VERSION "created by canmatrix"

NS_ :

BS_:

BU_: MD1_ECM ETC NODE_5 BSM_EBS RM_IRCS IC_Multic SGW BCM_NBM VCM NODE_31 ETS NODE_45 FCCU DICO NODE_72 FMReceiver SGW2 VCU ADCU MRGEN DTCO MBMS TPMS AI_CAID ELC ELC_R NODE_F7 BMS3 TUROLLA PCM SRR_Front_Left SRR_Rear_Right SRR_Front_Right SRR_Front SRR_Rear_Left ELFA3_S THERMOKING_M TMU_HP_Rr NODE_B1 NODE_B2 NODE_B3 NODE_B4 NODE_B5 NODE_B6 NODE_B7 NODE_B8 BMS2 NODE_B9 NODE_BA NODE_FC NODE_BB NODE_BC NODE_BE NODE_BD NODE_BF ACU NODE_C0 BMS1 NODE_C1 FCU NODE_C3 NODE_C4 NODE_EC NODE_C5 NODE_C6 NODE_C7 NODE_C8 VCU2 NODE_CA NODE_CB NODE_CD NODE_CE NODE_CF NODE_ED ST_ScanTool MASTER68_STD1 NODE_D1 NODE_F2 NODE_FD NODE_D2 MCSL NODE_EB NODE_D3 NODE_D4 NODE_D5 NODE_D6 VCCU NODE_D8 NODE_D9 NODE_F9 DiagTool NODE_DA NODE_DB NODE_DC NODE_DD NODE_DE NODE_DF NODE_E0 NODE_E1 NODE_E2 NODE_E9 NODE_E3 SAS NODE_FB NODE_F8 NODE_E6 ELFA3 NODE_F THERMOKING_D FMS MULTIC_S MULTIC_2 BMS4 BMS5 BMS6 BMS7 BMS8 BMS9 BMS10 BMS11 NODE_71

BO_ 2566725632 A1DOC1: 8 MD1_ECM
 SG_ At1DocInTemp : 0|16@1+ (0.03125,-273) [-273|1734.96875] "°C"  PCM

BO_ 2565874432 A1SCRDSI1: 8 MD1_ECM
 SG_ At1DefActDosQty : 0|16@1+ (0.3,0) [0|19276.5] "g/h"  PCM

BO_ 2499624448 A1SCREGT1: 8 MD1_ECM
 SG_ At1ScrOutTemp : 24|16@1+ (0.03125,-273) [-273|1734.96875] "°C"  PCM
 SG_ At1ScrInTemp : 0|16@1+ (0.03125,-273) [-273|1734.96875] "°C"  PCM

BO_ 2566811431 ACC1_27: 8 VCM
 SG_ AccSetDistMode : 27|3@1+ (1,0) [0|7] ""  PCM
 SG_ AccMode : 24|3@1+ (1,0) [0|7] ""  PCM

BO_ 2566803735 ACC2_17: 8 IC_Multic
 SG_ AccUseDem : 0|2@1+ (1,0) [0|3] ""  PCM

BO_ 2565406464 ACKM_00: 8 MD1_ECM
 SG_ Pgn_Busy m3 : 40|24@1+ (1,0) [0|16777215] "binary"  PCM
 SG_ Pgn_Ad m2 : 40|24@1+ (1,0) [0|16777215] "binary"  PCM
 SG_ Pgn_Nack m1 : 40|24@1+ (1,0) [0|16777215] "binary"  PCM
 SG_ Pgn_Ack m0 : 40|24@1+ (1,0) [0|16777215] "binary"  PCM
 SG_ CtrlByte_Ackm M : 0|8@1+ (1,0) [0|255] "binary"  PCM

BO_ 2565406467 ACKM_03: 8 ETC
 SG_ Pgn_Busy_E8FF03 m3 : 40|24@1+ (1,0) [0|16777215] "binary"  PCM
 SG_ Pgn_Ad_E8FF03 m2 : 40|24@1+ (1,0) [0|16777215] "binary"  PCM
 SG_ Pgn_Nack_E8FF03 m1 : 40|24@1+ (1,0) [0|16777215] "binary"  PCM
 SG_ Pgn_Ack_E8FF03 m0 : 40|24@1+ (1,0) [0|16777215] "binary"  PCM
 SG_ CtrlByte_Ackm_E8FF03 M : 0|8@1+ (1,0) [0|255] "binary"  PCM

BO_ 2565406475 ACKM_0B: 8 BSM_EBS
 SG_ Pgn_Busy_E8FF0B m3 : 40|24@1+ (1,0) [0|16777215] "binary"  PCM
 SG_ Pgn_Ad_E8FF0B m2 : 40|24@1+ (1,0) [0|16777215] "binary"  PCM
 SG_ Pgn_Nack_E8FF0B m1 : 40|24@1+ (1,0) [0|16777215] "binary"  PCM
 SG_ Pgn_Ack_E8FF0B m0 : 40|24@1+ (1,0) [0|16777215] "binary"  PCM
 SG_ CtrlByte_Ackm_E8FF0B M : 0|8@1+ (1,0) [0|255] "binary"  PCM

BO_ 2565406487 ACKM_17: 8 IC_Multic
 SG_ Pgn_Busy_E8FF17 m3 : 40|24@1+ (1,0) [0|16777215] "binary"  PCM
 SG_ Pgn_Ad_E8FF17 m2 : 40|24@1+ (1,0) [0|16777215] "binary"  PCM
 SG_ Pgn_Nack_E8FF17 m1 : 40|24@1+ (1,0) [0|16777215] "binary"  PCM
 SG_ Pgn_Ack_E8FF17 m0 : 40|24@1+ (1,0) [0|16777215] "binary"  PCM
 SG_ CtrlByte_Ackm_E8FF17 M : 0|8@1+ (1,0) [0|255] "binary"  PCM

BO_ 2565406492 ACKM_1C: 8 PCM
 SG_ Pgn_Busy_E8FF1C m3 : 40|24@1+ (1,0) [0|16777215] "binary" Vector__XXX
 SG_ Pgn_Ad_E8FF1C m2 : 40|24@1+ (1,0) [0|16777215] "binary" Vector__XXX
 SG_ Pgn_Nack_E8FF1C m1 : 40|24@1+ (1,0) [0|16777215] "binary" Vector__XXX
 SG_ Pgn_Ack_E8FF1C m0 : 40|24@1+ (1,0) [0|16777215] "binary" Vector__XXX
 SG_ AddrBusy m3 : 32|8@1+ (1,0) [0|255] "" Vector__XXX
 SG_ AddrAccessDenied m2 : 32|8@1+ (1,0) [0|255] "" Vector__XXX
 SG_ AddrNack m1 : 32|8@1+ (1,0) [0|255] "" Vector__XXX
 SG_ AddrAckd m0 : 32|8@1+ (1,0) [0|255] "" Vector__XXX
 SG_ CtrlByte_Ackm_E8FF1C M : 0|8@1+ (1,0) [0|255] "binary" Vector__XXX

BO_ 2565406493 ACKM_1D: 8 SGW
 SG_ Pgn_Busy_E8FF1D m3 : 40|24@1+ (1,0) [0|16777215] "binary"  PCM
 SG_ Pgn_Ad_E8FF1D m2 : 40|24@1+ (1,0) [0|16777215] "binary"  PCM
 SG_ Pgn_Nack_E8FF1D m1 : 40|24@1+ (1,0) [0|16777215] "binary"  PCM
 SG_ Pgn_Ack_E8FF1D m0 : 40|24@1+ (1,0) [0|16777215] "binary"  PCM
 SG_ AddrBusy_E8FF1D m3 : 32|8@1+ (1,0) [0|255] ""  PCM
 SG_ AddrAccessDenied_E8FF1D m2 : 32|8@1+ (1,0) [0|255] ""  PCM
 SG_ AddrNack_E8FF1D m1 : 32|8@1+ (1,0) [0|255] ""  PCM
 SG_ AddrAckd_E8FF1D m0 : 32|8@1+ (1,0) [0|255] ""  PCM
 SG_ CtrlByte_Ackm_E8FF1D M : 0|8@1+ (1,0) [0|255] "binary"  PCM

BO_ 2565406503 ACKM_27: 8 VCM
 SG_ Pgn_Busy_E8FF27 m3 : 40|24@1+ (1,0) [0|16777215] "binary"  PCM
 SG_ Pgn_Ad_E8FF27 m2 : 40|24@1+ (1,0) [0|16777215] "binary"  PCM
 SG_ Pgn_Nack_E8FF27 m1 : 40|24@1+ (1,0) [0|16777215] "binary"  PCM
 SG_ Pgn_Ack_E8FF27 m0 : 40|24@1+ (1,0) [0|16777215] "binary"  PCM
 SG_ CtrlByte_Ackm_E8FF27 M : 0|8@1+ (1,0) [0|255] "binary"  PCM

BO_ 2565406515 ACKM_33: 8 TPMS
 SG_ Pgn_Busy_E8FF33 m3 : 40|24@1+ (1,0) [0|16777215] "binary"  PCM
 SG_ Pgn_Ad_E8FF33 m2 : 40|24@1+ (1,0) [0|16777215] "binary"  PCM
 SG_ Pgn_Nack_E8FF33 m1 : 40|24@1+ (1,0) [0|16777215] "binary"  PCM
 SG_ Pgn_Ack_E8FF33 m0 : 40|24@1+ (1,0) [0|16777215] "binary"  PCM
 SG_ CtrlByte_Ackm_E8FF33 M : 0|8@1+ (1,0) [0|255] "binary"  PCM

BO_ 2565406520 ACKM_38: 8 ETS
 SG_ Pgn_Busy_E8FF38 m3 : 40|24@1+ (1,0) [0|16777215] "binary"  PCM
 SG_ Pgn_Ad_E8FF38 m2 : 40|24@1+ (1,0) [0|16777215] "binary"  PCM
 SG_ Pgn_Nack_E8FF38 m1 : 40|24@1+ (1,0) [0|16777215] "binary"  PCM
 SG_ Pgn_Ack_E8FF38 m0 : 40|24@1+ (1,0) [0|16777215] "binary"  PCM
 SG_ CtrlByte_Ackm_E8FF38 M : 0|8@1+ (1,0) [0|255] "binary"  PCM

BO_ 2565406590 ACKM_7E: 8 SGW2
 SG_ Pgn_Busy_E8FF7E m3 : 40|24@1+ (1,0) [0|16777215] "binary"  PCM
 SG_ Pgn_Ad_E8FF7E m2 : 40|24@1+ (1,0) [0|16777215] "binary"  PCM
 SG_ Pgn_Nack_E8FF7E m1 : 40|24@1+ (1,0) [0|16777215] "binary"  PCM
 SG_ Pgn_Ack_E8FF7E m0 : 40|24@1+ (1,0) [0|16777215] "binary"  PCM
 SG_ CtrlByte_Ackm_E8FF7E M : 0|8@1+ (1,0) [0|255] "binary"  PCM

BO_ 2565406622 ACKM_9E: 8 ADCU
 SG_ Pgn_Busy_E8FF9E m3 : 40|24@1+ (1,0) [0|16777215] "binary"  PCM
 SG_ Pgn_Ad_E8FF9E m2 : 40|24@1+ (1,0) [0|16777215] "binary"  PCM
 SG_ Pgn_Nack_E8FF9E m1 : 40|24@1+ (1,0) [0|16777215] "binary"  PCM
 SG_ Pgn_Ack_E8FF9E m0 : 40|24@1+ (1,0) [0|16777215] "binary"  PCM
 SG_ CtrlByte_Ackm_E8FF9E M : 0|8@1+ (1,0) [0|255] "binary"  PCM

BO_ 2565406624 ACKM_A0: 8 MRGEN
 SG_ Pgn_Busy_E8FFA0 m3 : 40|24@1+ (1,0) [0|16777215] "binary"  PCM
 SG_ Pgn_Ad_E8FFA0 m2 : 40|24@1+ (1,0) [0|16777215] "binary"  PCM
 SG_ Pgn_Nack_E8FFA0 m1 : 40|24@1+ (1,0) [0|16777215] "binary"  PCM
 SG_ Pgn_Ack_E8FFA0 m0 : 40|24@1+ (1,0) [0|16777215] "binary"  PCM
 SG_ CtrlByte_Ackm_E8FFA0 M : 0|8@1+ (1,0) [0|255] "binary"  PCM

BO_ 2364551072 AEBS1_A0: 8 MRGEN
 SG_ TimeToCollWithRelvObj : 16|8@1+ (0.05,0) [0|12.5] "s"  PCM
 SG_ AebsSts : 0|4@1+ (1,0) [0|15] ""  PCM

BO_ 2349572119 AEBS2_17_A0: 8 IC_Multic
 SG_ DrivActvDemForAebs : 0|2@1+ (1,0) [0|3] ""  PCM,MRGEN

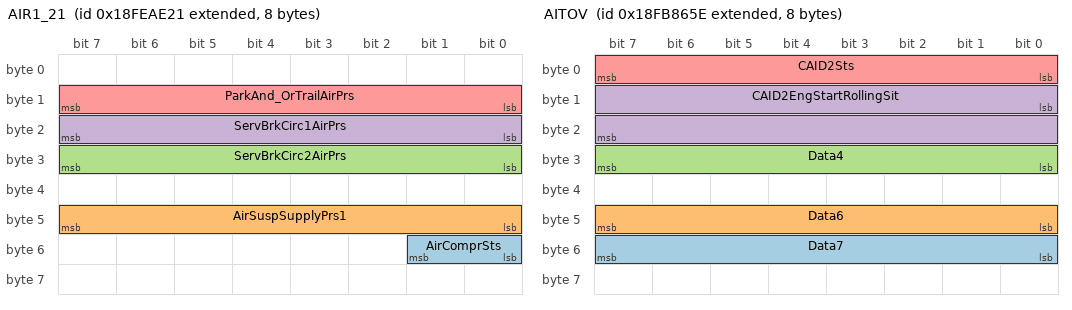
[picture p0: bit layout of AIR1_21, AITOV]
BO_ 2566827553 AIR1_21: 8 BCM_NBM
 SG_ AirComprSts : 48|2@1+ (1,0) [0|3] ""  PCM
 SG_ AirSuspSupplyPrs1 : 40|8@1+ (8,0) [0|2000] "kPa"  PCM
 SG_ ServBrkCirc2AirPrs : 24|8@1+ (8,0) [0|2000] "kPa"  PCM
 SG_ ServBrkCirc1AirPrs : 16|8@1+ (8,0) [0|2000] "kPa"  PCM
 SG_ ParkAnd_OrTrailAirPrs : 8|8@1+ (8,0) [0|2000] "kPa"  PCM

BO_ 2566620766 AITOV: 8 AI_CAID
 SG_ Data7 : 48|8@1+ (1,0) [0|250] ""  PCM
 SG_ Data6 : 40|8@1+ (1,0) [0|250] ""  PCM
 SG_ Data4 : 24|8@1+ (1,0) [0|250] ""  PCM
 SG_ CAID2EngStartRollingSit : 8|16@1+ (1,0) [0|64255] ""  PCM
 SG_ CAID2Sts : 0|8@1+ (1,0) [0|250] ""  PCM

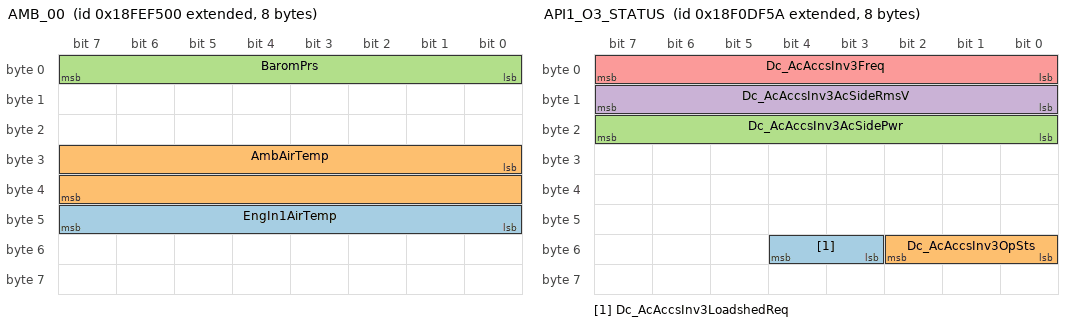
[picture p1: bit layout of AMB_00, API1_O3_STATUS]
BO_ 2566845696 AMB_00: 8 MD1_ECM
 SG_ EngIn1AirTemp : 40|8@1+ (1,-40) [-40|210] "°C"  PCM
 SG_ AmbAirTemp : 24|16@1+ (0.03125,-273) [-273|1734.96875] "°C"  PCM
 SG_ BaromPrs : 0|8@1+ (0.5,0) [0|125] "kPa"  PCM

BO_ 2566845719 AMB_17: 8 IC_Multic
 SG_ AmbAirTemp_FEF517 : 24|16@1+ (0.03125,-273) [-273|1734.96875] "°C"  PCM
 SG_ CabInternTemp : 8|16@1+ (0.03125,-273) [-273|1734.96875] "°C"  PCM

BO_ 2565920602 API1_O1_STATUS: 8 DICO
 SG_ Dc_AcAccsInv1Freq : 0|8@1+ (1,0) [0|250] "Hz"  PCM

BO_ 2565921626 API1_O2_STATUS: 8 DICO
 SG_ Dc_AcAccsInv2OpSts : 48|3@1+ (1,0) [0|7] ""  PCM
 SG_ Dc_AcAccsInv2AcSidePwr : 16|8@1+ (0.1,0) [0|25] "kW"  PCM

BO_ 2565922650 API1_O3_STATUS: 8 DICO
 SG_ Dc_AcAccsInv3LoadshedReq : 51|2@1+ (1,0) [0|3] ""  PCM
 SG_ Dc_AcAccsInv3OpSts : 48|3@1+ (1,0) [0|7] ""  PCM
 SG_ Dc_AcAccsInv3AcSidePwr : 16|8@1+ (0.1,0) [0|25] "kW"  PCM
 SG_ Dc_AcAccsInv3AcSideRmsV : 8|8@1+ (2,0) [0|500] "Vrms"  PCM
 SG_ Dc_AcAccsInv3Freq : 0|8@1+ (1,0) [0|250] "Hz"  PCM

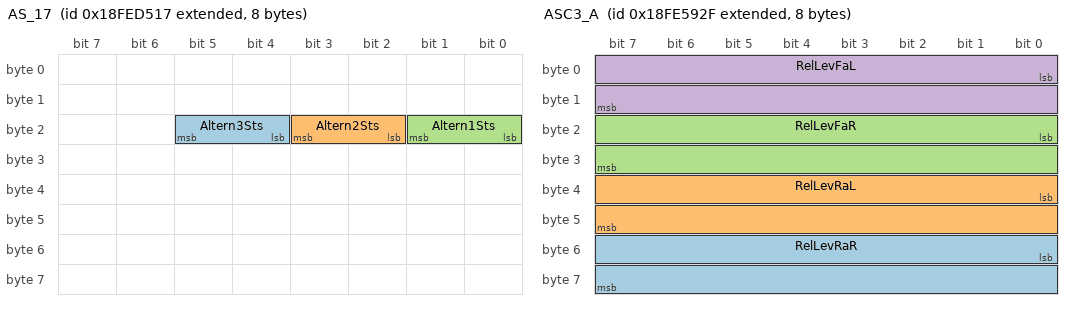
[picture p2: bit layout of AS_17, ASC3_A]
BO_ 2566837527 AS_17: 8 IC_Multic
 SG_ Altern3Sts : 20|2@1+ (1,0) [0|3] ""  PCM
 SG_ Altern2Sts : 18|2@1+ (1,0) [0|3] ""  PCM
 SG_ Altern1Sts : 16|2@1+ (1,0) [0|3] ""  PCM

BO_ 2365479471 ASC1_A: 8 ELC
 SG_ KneelInfo : 24|4@1+ (1,0) [0|15] ""  PCM

BO_ 2365479488 ASC1_B: 8 ELC_R
 SG_ KneelInfo_E5A40 : 24|4@1+ (1,0) [0|15] ""  PCM

BO_ 2566805807 ASC3_A: 8 ELC
 SG_ RelLevRaR : 48|16@1+ (0.1,-3200) [-3200|3225.5] "mm"  PCM
 SG_ RelLevRaL : 32|16@1+ (0.1,-3200) [-3200|3225.5] "mm"  PCM
 SG_ RelLevFaR : 16|16@1+ (0.1,-3200) [-3200|3225.5] "mm"  PCM
 SG_ RelLevFaL : 0|16@1+ (0.1,-3200) [-3200|3225.5] "mm"  PCM

BO_ 2566805824 ASC3_B: 8 ELC_R
 SG_ RelLevRaR_FE5940 : 48|16@1+ (0.1,-3200) [-3200|3225.5] "mm"  PCM
 SG_ RelLevRaL_FE5940 : 32|16@1+ (0.1,-3200) [-3200|3225.5] "mm"  PCM

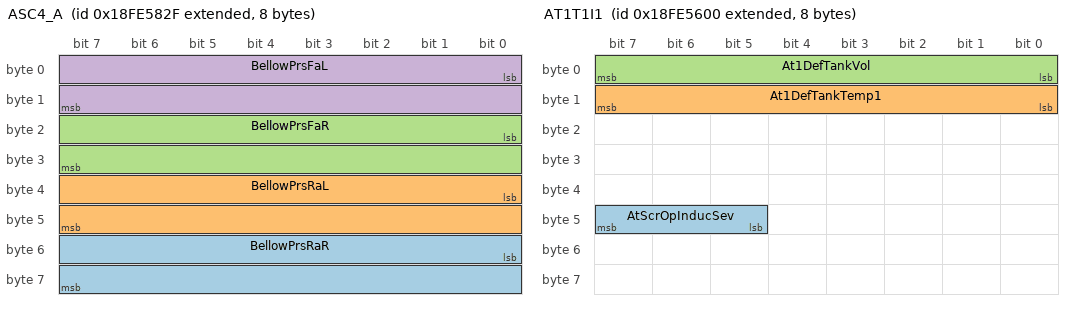
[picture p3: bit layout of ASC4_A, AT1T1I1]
BO_ 2566805551 ASC4_A: 8 ELC
 SG_ BellowPrsRaR : 48|16@1+ (0.1,0) [0|6425.5] "kPa"  PCM
 SG_ BellowPrsRaL : 32|16@1+ (0.1,0) [0|6425.5] "kPa"  PCM
 SG_ BellowPrsFaR : 16|16@1+ (0.1,0) [0|6425.5] "kPa"  PCM
 SG_ BellowPrsFaL : 0|16@1+ (0.1,0) [0|6425.5] "kPa"  PCM

BO_ 2566805568 ASC4_B: 8 ELC_R
 SG_ BellowPrsRaR_FE5840 : 48|16@1+ (0.1,0) [0|6425.5] "kPa"  PCM
 SG_ BellowPrsRaL_FE5840 : 32|16@1+ (0.1,0) [0|6425.5] "kPa"  PCM

BO_ 2566763520 AT1IG2: 8 MD1_ECM
 SG_ At1DpfInTemp : 16|16@1+ (0.03125,-273) [-273|1734.96875] "°C"  PCM

BO_ 2566804992 AT1T1I1: 8 MD1_ECM
 SG_ AtScrOpInducSev : 45|3@1+ (1,0) [0|7] ""  PCM
 SG_ At1DefTankTemp1 : 8|8@1+ (1,-40) [-40|210] "°C"  PCM
 SG_ At1DefTankVol : 0|8@1+ (0.4,0) [0|100] "%"  PCM

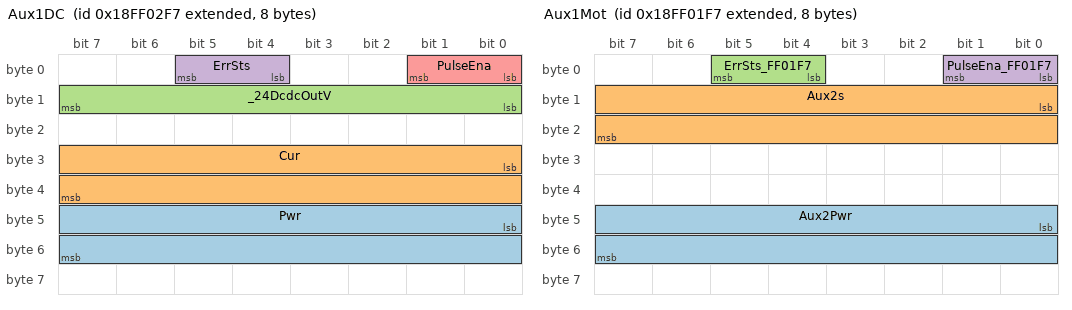
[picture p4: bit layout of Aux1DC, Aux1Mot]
BO_ 2566849271 Aux1DC: 8 NODE_F7
 SG_ Pwr : 40|16@1+ (0.005,-160) [-160|161.275] "Kw"  PCM
 SG_ Cur : 24|16@1+ (0.05,-1600) [-1600|1612.75] "A"  PCM
 SG_ _24DcdcOutV : 8|8@1+ (0.2,0) [0|50] "V"  PCM
 SG_ ErrSts : 4|2@1+ (1,0) [0|3] ""  PCM
 SG_ PulseEna : 0|2@1+ (1,0) [0|3] ""  PCM

BO_ 2566849015 Aux1Mot: 8 NODE_F7
 SG_ Aux2Pwr : 40|16@1+ (0.005,-160) [-160|161.275] "Kw"  PCM
 SG_ Aux2s : 8|16@1+ (1,-32127) [-32127|32128] "rpm"  PCM
 SG_ ErrSts_FF01F7 : 4|2@1+ (1,0) [0|3] ""  PCM
 SG_ PulseEna_FF01F7 : 0|2@1+ (1,0) [0|3] ""  PCM

BO_ 2566848759 Aux1St: 8 NODE_F7
 SG_ DcLinkV : 32|8@1+ (4,0) [0|1000] "V"  PCM
 SG_ Term15Sts : 8|2@1+ (1,0) [0|3] ""  PCM

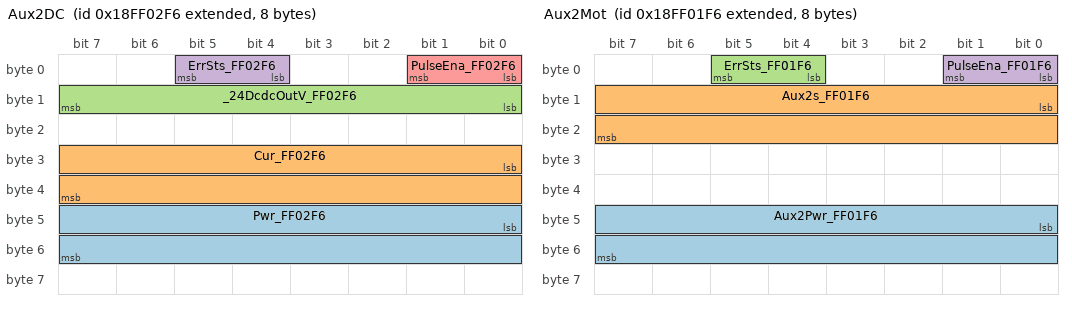
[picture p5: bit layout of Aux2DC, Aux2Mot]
BO_ 2566849270 Aux2DC: 8 BMS3
 SG_ Pwr_FF02F6 : 40|16@1+ (0.005,-160) [-160|161.275] "Kw"  PCM
 SG_ Cur_FF02F6 : 24|16@1+ (0.05,-1600) [-1600|1612.75] "A"  PCM
 SG_ _24DcdcOutV_FF02F6 : 8|8@1+ (0.2,0) [0|50] "V"  PCM
 SG_ ErrSts_FF02F6 : 4|2@1+ (1,0) [0|3] ""  PCM
 SG_ PulseEna_FF02F6 : 0|2@1+ (1,0) [0|3] ""  PCM

BO_ 2566849014 Aux2Mot: 8 BMS3
 SG_ Aux2Pwr_FF01F6 : 40|16@1+ (0.005,-160) [-160|161.275] "Kw"  PCM
 SG_ Aux2s_FF01F6 : 8|16@1+ (1,-32127) [-32127|32128] "rpm"  PCM
 SG_ ErrSts_FF01F6 : 4|2@1+ (1,0) [0|3] ""  PCM
 SG_ PulseEna_FF01F6 : 0|2@1+ (1,0) [0|3] ""  PCM

BO_ 2566848758 Aux2St: 8 BMS3
 SG_ DcLinkV_FF00F6 : 32|8@1+ (4,0) [0|1000] "V"  PCM
 SG_ Term15Sts_FF00F6 : 8|2@1+ (1,0) [0|3] ""  PCM

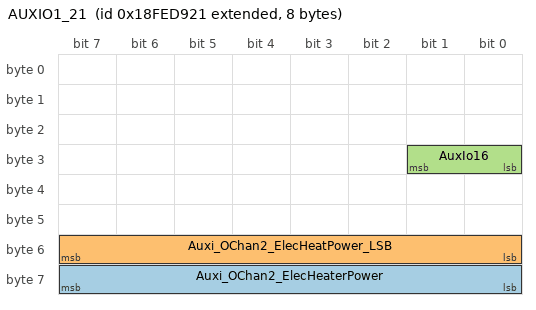
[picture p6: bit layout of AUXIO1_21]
BO_ 2566838561 AUXIO1_21: 8 BCM_NBM
 SG_ Auxi_OChan2_ElecHeaterPower : 56|8@1+ (1,0) [0|255] " kW"  PCM
 SG_ Auxi_OChan2_ElecHeatPower_LSB : 48|8@1+ (1,0) [0|255] " kW"  PCM
 SG_ AuxIo16 : 24|2@1+ (1,0) [0|3] ""  PCM

CM_ BO_ 2566725632 "- CUC.C.PCM..3..TELEM: FPT request - Diesel vehicle only";
CM_ BO_ 2565874432 "- Diesel vehicle only";
CM_ BO_ 2499624448 "- Testing purpose.
- CUC.C.PCM..3..TELEM: FPT request - Diesel vehicle only";
CM_ BO_ 2566811431 "- Only if ACC option is enabled";
CM_ BO_ 2566803735 "- Only if ACC option is enabled.
-  VCM VDB File: For bus both signals are in ACC2_17.
- s.Ib..24.work.TELEM: Telem FE: In acccording with NGT file";
CM_ BO_ 2565406464 "- NACK required as a response to a destination specific request that cannot be served, ACK/NACK not permitted for a global request (SAE J1939/21).
-  Negative ACK MD1 to ALL.";
CM_ SG_ 2565406464 Pgn_Busy "- Value Table filled with the most commonly used PGNs in Iveco applications, ECU implementation may differ";
CM_ SG_ 2565406464 Pgn_Ad "- Value Table filled with the most commonly used PGNs in Iveco applications, ECU implementation may differ";
CM_ SG_ 2565406464 Pgn_Nack "- Value Table filled with the most commonly used PGNs in Iveco applications, ECU implementation may differ";
CM_ SG_ 2565406464 Pgn_Ack "- Value Table filled with the most commonly used PGNs in Iveco applications, ECU implementation may differ";
CM_ BO_ 2565406467 "- NACK required as a response to a destination specific request that cannot be served, ACK/NACK not permitted for a global request (SAE J1939/21).
-  Negative ACK Gearbox to ALL.";
CM_ SG_ 2565406467 Pgn_Busy_E8FF03 "- Value Table filled with the most commonly used PGNs in Iveco applications, ECU implementation may differ";
CM_ SG_ 2565406467 Pgn_Ad_E8FF03 "- Value Table filled with the most commonly used PGNs in Iveco applications, ECU implementation may differ";
CM_ SG_ 2565406467 Pgn_Nack_E8FF03 "- Value Table filled with the most commonly used PGNs in Iveco applications, ECU implementation may differ";
CM_ SG_ 2565406467 Pgn_Ack_E8FF03 "- Value Table filled with the most commonly used PGNs in Iveco applications, ECU implementation may differ";
CM_ BO_ 2565406475 "- NACK required as a response to a destination specific request that cannot be served, ACK/NACK not permitted for a global request (SAE J1939/21).
-  Negative ACK EBS to ALL.";
CM_ SG_ 2565406475 Pgn_Busy_E8FF0B "- Value Table filled with the most commonly used PGNs in Iveco applications, ECU implementation may differ";
CM_ SG_ 2565406475 Pgn_Ad_E8FF0B "- Value Table filled with the most commonly used PGNs in Iveco applications, ECU implementation may differ";
CM_ SG_ 2565406475 Pgn_Nack_E8FF0B "- Value Table filled with the most commonly used PGNs in Iveco applications, ECU implementation may differ";
CM_ SG_ 2565406475 Pgn_Ack_E8FF0B "- Value Table filled with the most commonly used PGNs in Iveco applications, ECU implementation may differ";
CM_ BO_ 2565406487 "- NACK required as a response to a destination specific request that cannot be served, ACK/NACK not permitted for a global request (SAE J1939/21).
-  Negative ACK IC to ALL.";
CM_ SG_ 2565406487 Pgn_Busy_E8FF17 "- Value Table filled with the most commonly used PGNs in Iveco applications, ECU implementation may differ";
CM_ SG_ 2565406487 Pgn_Ad_E8FF17 "- Value Table filled with the most commonly used PGNs in Iveco applications, ECU implementation may differ";
CM_ SG_ 2565406487 Pgn_Nack_E8FF17 "- Value Table filled with the most commonly used PGNs in Iveco applications, ECU implementation may differ";
CM_ SG_ 2565406487 Pgn_Ack_E8FF17 "- Value Table filled with the most commonly used PGNs in Iveco applications, ECU implementation may differ";
CM_ BO_ 2565406492 "- NACK required as a response to a destination specific request that cannot be served, ACK/NACK not permitted for a global request (SAE J1939/21).
-  Negative ACK eHorizon to ALL. eHorizon integrated on PCM3 starting from ADAS.";
CM_ SG_ 2565406492 Pgn_Busy_E8FF1C "- Value Table filled with the most commonly used PGNs in Iveco applications, ECU implementation may differ";
CM_ SG_ 2565406492 Pgn_Ad_E8FF1C "- Value Table filled with the most commonly used PGNs in Iveco applications, ECU implementation may differ";
CM_ SG_ 2565406492 Pgn_Nack_E8FF1C "- Value Table filled with the most commonly used PGNs in Iveco applications, ECU implementation may differ";
CM_ SG_ 2565406492 Pgn_Ack_E8FF1C "- Value Table filled with the most commonly used PGNs in Iveco applications, ECU implementation may differ";
CM_ BO_ 2565406493 "- NACK required as a response to a destination specific request that cannot be served, ACK/NACK not permitted for a global request (SAE J1939/21).
-  Negative ACK SGW1 to ALL.";
CM_ SG_ 2565406493 Pgn_Busy_E8FF1D "- Value Table filled with the most commonly used PGNs in Iveco applications, ECU implementation may differ";
CM_ SG_ 2565406493 Pgn_Ad_E8FF1D "- Value Table filled with the most commonly used PGNs in Iveco applications, ECU implementation may differ";
CM_ SG_ 2565406493 Pgn_Nack_E8FF1D "- Value Table filled with the most commonly used PGNs in Iveco applications, ECU implementation may differ";
CM_ SG_ 2565406493 Pgn_Ack_E8FF1D "- Value Table filled with the most commonly used PGNs in Iveco applications, ECU implementation may differ";
CM_ BO_ 2565406503 "- NACK required as a response to a destination specific request that cannot be served, ACK/NACK not permitted for a global request (SAE J1939/21).
-  Negative ACK VCM4 to ALL.";
CM_ SG_ 2565406503 Pgn_Busy_E8FF27 "- Value Table filled with the most commonly used PGNs in Iveco applications, ECU implementation may differ";
CM_ SG_ 2565406503 Pgn_Ad_E8FF27 "- Value Table filled with the most commonly used PGNs in Iveco applications, ECU implementation may differ";
CM_ SG_ 2565406503 Pgn_Nack_E8FF27 "- Value Table filled with the most commonly used PGNs in Iveco applications, ECU implementation may differ";
CM_ SG_ 2565406503 Pgn_Ack_E8FF27 "- Value Table filled with the most commonly used PGNs in Iveco applications, ECU implementation may differ";
CM_ BO_ 2565406515 "- NACK required as a response to a destination specific request that cannot be served, ACK/NACK not permitted for a global request (SAE J1939/21).
-  Negative ACK TPMS to ALL.";
CM_ SG_ 2565406515 Pgn_Busy_E8FF33 "- Value Table filled with the most commonly used PGNs in Iveco applications, ECU implementation may differ";
CM_ SG_ 2565406515 Pgn_Ad_E8FF33 "- Value Table filled with the most commonly used PGNs in Iveco applications, ECU implementation may differ";
CM_ SG_ 2565406515 Pgn_Nack_E8FF33 "- Value Table filled with the most commonly used PGNs in Iveco applications, ECU implementation may differ";
CM_ SG_ 2565406515 Pgn_Ack_E8FF33 "- Value Table filled with the most commonly used PGNs in Iveco applications, ECU implementation may differ";
CM_ BO_ 2565406520 "- Negative ACK ETS to ALL. NACK required as a response to a destination specific request that cannot be served, ACK/NACK not permitted for a global request (SAE J1939/21).
-  Only CW Diesel.";
CM_ SG_ 2565406520 Pgn_Busy_E8FF38 "- Value Table filled with the most commonly used PGNs in Iveco applications, ECU implementation may differ";
CM_ SG_ 2565406520 Pgn_Ad_E8FF38 "- Value Table filled with the most commonly used PGNs in Iveco applications, ECU implementation may differ";
CM_ SG_ 2565406520 Pgn_Nack_E8FF38 "- Value Table filled with the most commonly used PGNs in Iveco applications, ECU implementation may differ";
CM_ SG_ 2565406520 Pgn_Ack_E8FF38 "- Value Table filled with the most commonly used PGNs in Iveco applications, ECU implementation may differ";
CM_ BO_ 2565406590 "- NACK required as a response to a destination specific request that cannot be served, ACK/NACK not permitted for a global request (SAE J1939/21).
-  Negative ACK SGW2 to ALL.";
CM_ SG_ 2565406590 Pgn_Busy_E8FF7E "- Value Table filled with the most commonly used PGNs in Iveco applications, ECU implementation may differ";
CM_ SG_ 2565406590 Pgn_Ad_E8FF7E "- Value Table filled with the most commonly used PGNs in Iveco applications, ECU implementation may differ";
CM_ SG_ 2565406590 Pgn_Nack_E8FF7E "- Value Table filled with the most commonly used PGNs in Iveco applications, ECU implementation may differ";
CM_ SG_ 2565406590 Pgn_Ack_E8FF7E "- Value Table filled with the most commonly used PGNs in Iveco applications, ECU implementation may differ";
CM_ BO_ 2565406622 "- NACK required as a response to a destination specific request that cannot be served, ACK/NACK not permitted for a global request (SAE J1939/21).
-  Negative ACK ADCU to ALL.";
CM_ SG_ 2565406622 Pgn_Busy_E8FF9E "- Value Table filled with the most commonly used PGNs in Iveco applications, ECU implementation may differ";
CM_ SG_ 2565406622 Pgn_Ad_E8FF9E "- Value Table filled with the most commonly used PGNs in Iveco applications, ECU implementation may differ";
CM_ SG_ 2565406622 Pgn_Nack_E8FF9E "- Value Table filled with the most commonly used PGNs in Iveco applications, ECU implementation may differ";
CM_ SG_ 2565406622 Pgn_Ack_E8FF9E "- Value Table filled with the most commonly used PGNs in Iveco applications, ECU implementation may differ";
CM_ BO_ 2565406624 "- NACK required as a response to a destination specific request that cannot be served, ACK/NACK not permitted for a global request (SAE J1939/21).
-  Negative ACK ADCU (AEBS) to ALL. CW Class III only.
-  SA=0xA0. ECU Sender is MRGen21 (CAN RADAR).";
CM_ SG_ 2565406624 Pgn_Busy_E8FFA0 "- Value Table filled with the most commonly used PGNs in Iveco applications, ECU implementation may differ";
CM_ SG_ 2565406624 Pgn_Ad_E8FFA0 "- Value Table filled with the most commonly used PGNs in Iveco applications, ECU implementation may differ";
CM_ SG_ 2565406624 Pgn_Nack_E8FFA0 "- Value Table filled with the most commonly used PGNs in Iveco applications, ECU implementation may differ";
CM_ SG_ 2565406624 Pgn_Ack_E8FFA0 "- Value Table filled with the most commonly used PGNs in Iveco applications, ECU implementation may differ";
CM_ BO_ 2364551072 "- For vehicle with AEBS only (CW Bus only)
-  SA=0xA0. ECU Sender is MRGen21 (CAN RADAR).";
CM_ SG_ 2364551072 TimeToCollWithRelvObj "- 1=20ms";
CM_ BO_ 2349572119 "- CW Bus only
-  DA=0xA0. MRGen21 (CAN RADAR).
-  Update: Gap Interface AEBS on CW Elec BEV only. Not on EBS ZF. (OPL 136)";
CM_ BO_ 2566827553 "- MC.W.VCM....VDB: Transmission rate: 1000/On change";
CM_ SG_ 2566827553 AirComprSts "- NBM send to FF";
CM_ SG_ 2566827553 AirSuspSupplyPrs1 "- Set to FF (not available)";
CM_ SG_ 2566620766 Data6 "- Vehicle Status according to 50436-4:2020";
CM_ BO_ 2566845696 "- Ambient air temperature signal set not available (0xFFFF) in some AMB_00 VDB version hence EDB version is preferred.";
CM_ SG_ 2566845696 EngIn1AirTemp "- Not evaluated by ECM (FFh).
-  Signal available ICE Only";
CM_ SG_ 2566845696 AmbAirTemp "- On Elec vehicles: Data is sent by BCM (AMB_21: 18 FE F5 21) or IC (AMB_17: 18 FE F5 17) ECUs.
-  On ICE vehicles: Data not transfered by VCM. Set to 0xFFFF.";
CM_ SG_ 2566845696 BaromPrs "- FEh in case of defective sensor";
CM_ BO_ 2566845719 "- GX: Multic2 is Sender ECU.
-  Intercity: Only ambient temperature is provided by SPR1 instrument cluster.
-  No more requested on FMS V5.
-  Not used on CAN INFOT, not consomed by RADB.
-  UW: NBM is Sender ECU.";
CM_ SG_ 2566845719 CabInternTemp "- CW only";
CM_ BO_ 2565920602 "- Elec Siemens message available only.";
CM_ SG_ 2565920602 Dc_AcAccsInv1Freq "- Signal to the Accessory Power Inverter frequency of the attached accessory, Corresponds to 100% Frequency Percentage Command parameter";
CM_ BO_ 2565921626 "- 'DC/AC Accessory Inverter 2 Feedback'' / ''DCAC_AI2_FDBK'' in NormeJ1939DA
-  Elec Siemens message available only.";
CM_ SG_ 2565921626 Dc_AcAccsInv2OpSts "- Signal from the API 1 Output 2 declaring the status of the inverter, The Inverter Output Faulted state will be communicated when the inverter has shutdown due to an overload condition or other fault,";
CM_ SG_ 2565921626 Dc_AcAccsInv2AcSidePwr "- Signal from the API 1 Output 2 declaring present operating power of the inverter";
CM_ BO_ 2565922650 "- Elec Siemens 18m with HeatPunp available only. Gx BEV only.";
CM_ SG_ 2565922650 Dc_AcAccsInv3LoadshedReq "- API 1 Output 3  Loadshed Request";
CM_ SG_ 2565922650 Dc_AcAccsInv3OpSts "- API 1 Output 3 Operating Status";
CM_ SG_ 2565922650 Dc_AcAccsInv3AcSidePwr "- API 1 Output 3 Inverter Power";
CM_ SG_ 2565922650 Dc_AcAccsInv3AcSideRmsV "- API 1 Output 3 Operating Voltage";
CM_ SG_ 2565922650 Dc_AcAccsInv3Freq "- API 1 Output 3 Operating Frequency";
CM_ BO_ 2566837527 "- On CAN FMS: Predisposal (confirmation by responsible), even concerning FE applications.
-  Used RATP.";
CM_ BO_ 2365479488 "- From Articulated bus Dolly";
CM_ BO_ 2566805807 "- The message contains relative levels (in millimeters) to the nominal ride height (Normal level).";
CM_ BO_ 2566805824 "- From Articulated bus Dolly";
CM_ BO_ 2566805551 "- The message contains actual air bellow pressures in kilopascals (KPa) based on the pressure sensor  installed in the bellows.
- CUC.C.PCM..3..TELEM: : DSE Fonctionnement
- EBC.ZF.BSM..27..VDB: to be considered for future usage
- OVG.Mtx.FMS.4.24.Generic.FMSi: if option";
CM_ BO_ 2566805568 "- Specific RATP. PCM3: DSE Fonctionnement";
CM_ BO_ 2566763520 "- FPT request - Only for Diesel vehicles";
CM_ SG_ 2566763520 At1DpfInTemp "- The maximum value is 1734,96875 (not 1735).";
CM_ BO_ 2566804992 "- Diesel vehicle only";
CM_ BO_ 2566849271 "- Specific to Siemens Full Elec vehicles. DC DC 24V (main). Only Elfa2.";
CM_ BO_ 2566849015 "- Specific to Siemens Full Elec vehicles. Air compressor. Only Elfa2.";
CM_ BO_ 2566848759 "- Specific to Siemens Full Elec vehicles. Air compressor. Only Elfa2.";
CM_ BO_ 2566849270 "- Specific to Siemens Full Elec vehicles. DC DC 24V (secondary). Only Elfa2.";
CM_ BO_ 2566849014 "- Specific to Siemens Full Elec vehicles. Air compressor. Only Elfa2.";
CM_ BO_ 2566848758 "- Specific to Siemens Full Elec vehicles. Air compressor. Only Elfa2.";
CM_ SG_ 2566838561 AuxIo16 "- Active electric heater.
- VS1.B.SGW..23..FMSi: FMSV5 ZEV only.";
BA_DEF_ BO_  "CI_MsgDefinition" STRING ;
BA_DEF_ BO_  "CI_MsgId" INT 0 2147483647;
BA_DEF_ BO_  "CI_MsgName" STRING ;
BA_DEF_ BO_  "GenMsgCycleTime" INT 0 3600000;
BA_DEF_ BO_  "GenMsgCycleTimeFast" INT 0 3600000;
BA_DEF_ BO_  "GenMsgDelayTime" INT 0 3600000;
BA_DEF_ BO_  "GenMsgILSupport" ENUM  "No","Yes";
BA_DEF_ BO_  "GenMsgNrOfRepetition" INT 0 1000000;
BA_DEF_ BO_  "GenMsgRequestable" INT 0 1;
BA_DEF_ BO_  "GenMsgSendType" ENUM  "cyclic","NotUsed","NotUsed","NotUsed","NotUsed","NotUsed","NotUsed","IfActive","noMsgSendType";
BA_DEF_ BO_  "GenMsgStartDelayTime" INT 0 100000;
BA_DEF_ BO_  "TpJ1939VarDlc" ENUM  "No","Yes";
BA_DEF_ BO_  "VFrameFormat" ENUM  "StandardCAN","ExtendedCAN","reserved","J1939PG";
BA_DEF_ SG_  "CI_ParId" STRING ;
BA_DEF_ SG_  "CI_SigId" INT 0 2147483647;
BA_DEF_ SG_  "CI_SigName" STRING ;
BA_DEF_ SG_  "GenSigEVName" STRING ;
BA_DEF_ SG_  "GenSigILSupport" ENUM  "No","Yes";
BA_DEF_ SG_  "GenSigInactiveValue" INT 0 2147483647;
BA_DEF_ SG_  "GenSigSendType" ENUM  "Cyclic","OnWrite","OnWriteWithRepetition","OnChange","OnChangeWithRepetition","IfActive","IfActiveWithRepetition","NoSigSendType";
BA_DEF_ SG_  "GenSigStartValue" INT 0 2147483647;
BA_DEF_ SG_  "GenSigTimeoutTime_ACM_CANAIR" INT 0 3600000;
BA_DEF_ SG_  "GenSigTimeoutTime_ACU" INT 0 3600000;
BA_DEF_ SG_  "GenSigTimeoutTime_ADCU" INT 0 3600000;
BA_DEF_ SG_  "GenSigTimeoutTime_AI_CAID" INT 0 3600000;
BA_DEF_ SG_  "GenSigTimeoutTime_ASM_ELC5_Fr" INT 0 3600000;
BA_DEF_ SG_  "GenSigTimeoutTime_AVAS" INT 0 3600000;
BA_DEF_ SG_  "GenSigTimeoutTime_Av2HP" INT 0 3600000;
BA_DEF_ SG_  "GenSigTimeoutTime_BCM_NBM" INT 0 3600000;
BA_DEF_ SG_  "GenSigTimeoutTime_BSM_EBS" INT 0 3600000;
BA_DEF_ SG_  "GenSigTimeoutTime_DICO" INT 0 3600000;
BA_DEF_ SG_  "GenSigTimeoutTime_DMS" INT 0 3600000;
BA_DEF_ SG_  "GenSigTimeoutTime_EBS_EBR" INT 0 3600000;
BA_DEF_ SG_  "GenSigTimeoutTime_ECM_MD1_D" INT 0 3600000;
BA_DEF_ SG_  "GenSigTimeoutTime_ECM_MD1_G" INT 0 3600000;
BA_DEF_ SG_  "GenSigTimeoutTime_ETC_DiwaNXT" INT 0 3600000;
BA_DEF_ SG_  "GenSigTimeoutTime_ETC_DiwaNXT_MH" INT 0 3600000;
BA_DEF_ SG_  "GenSigTimeoutTime_ETC_Ecolife2" INT 0 3600000;
BA_DEF_ SG_  "GenSigTimeoutTime_FCCU" INT 0 3600000;
BA_DEF_ SG_  "GenSigTimeoutTime_FMS_FMS4" INT 0 3600000;
BA_DEF_ SG_  "GenSigTimeoutTime_FMS_FMS5" INT 0 3600000;
BA_DEF_ SG_  "GenSigTimeoutTime_HVPDU_HV_BOX" INT 0 3600000;
BA_DEF_ SG_  "GenSigTimeoutTime_IC_MulticII" INT 0 3600000;
BA_DEF_ SG_  "GenSigTimeoutTime_IC_MulticS" INT 0 3600000;
BA_DEF_ SG_  "GenSigTimeoutTime_INVEM1_ELFA3" INT 0 3600000;
BA_DEF_ SG_  "GenSigTimeoutTime_MBMS" INT 0 3600000;
BA_DEF_ SG_  "GenSigTimeoutTime_MCSL" INT 0 3600000;
BA_DEF_ SG_  "GenSigTimeoutTime_MPPxPTFE2" INT 0 3600000;
BA_DEF_ SG_  "GenSigTimeoutTime_PCM" INT 0 3600000;
BA_DEF_ SG_  "GenSigTimeoutTime_RDAB_SmtRadio" INT 0 3600000;
BA_DEF_ SG_  "GenSigTimeoutTime_RM_INTD" INT 0 3600000;
BA_DEF_ SG_  "GenSigTimeoutTime_RM_IRCS" INT 0 3600000;
BA_DEF_ SG_  "GenSigTimeoutTime_SAS" INT 0 3600000;
BA_DEF_ SG_  "GenSigTimeoutTime_SGW" INT 0 3600000;
BA_DEF_ SG_  "GenSigTimeoutTime_SGW2" INT 0 3600000;
BA_DEF_ SG_  "GenSigTimeoutTime_TASM_ETS" INT 0 3600000;
BA_DEF_ SG_  "GenSigTimeoutTime_TMU_HP_Fr" INT 0 3600000;
BA_DEF_ SG_  "GenSigTimeoutTime_TMU_HP_Rr" INT 0 3600000;
BA_DEF_ SG_  "GenSigTimeoutTime_TPMS" INT 0 3600000;
BA_DEF_ SG_  "GenSigTimeoutTime_Tacho_DTCO" INT 0 3600000;
BA_DEF_ SG_  "GenSigTimeoutTime_Tacho_MTCO" INT 0 3600000;
BA_DEF_ SG_  "GenSigTimeoutTime_Tacho_TSU" INT 0 3600000;
BA_DEF_ SG_  "GenSigTimeoutTime_VCM" INT 0 3600000;
BA_DEF_ SG_  "GenSigTimeoutTime_VCU" INT 0 3600000;
BA_DEF_ SG_  "GenSigTimeoutTime_VMU" INT 0 3600000;
BA_DEF_ SG_  "SPN" INT 0 524287;
BA_DEF_ SG_  "SigType" ENUM  "Default","Range","RangeSigned","ASCII","Discrete","Control","ReferencePGN","DTC","StringDelimiter","StringLength","StringLengthControl";
BA_DEF_ BU_  "ILUsed" ENUM  "No","Yes";
BA_DEF_ BU_  "NmStationAddress" INT 0 255;
BA_DEF_ BU_  "NodeLayerModules" STRING ;
BA_DEF_  "Baudrate" INT 0 1000000;
BA_DEF_  "BusType" STRING ;
BA_DEF_  "CI_CcdVersion" STRING ;
BA_DEF_  "Manufacturer" STRING ;
BA_DEF_DEF_  "CI_MsgDefinition" "";
BA_DEF_DEF_  "CI_MsgId" 0;
BA_DEF_DEF_  "CI_MsgName" "";
BA_DEF_DEF_  "GenMsgCycleTime" 0;
BA_DEF_DEF_  "GenMsgCycleTimeFast" 0;
BA_DEF_DEF_  "GenMsgDelayTime" 1;
BA_DEF_DEF_  "GenMsgILSupport" "Yes";
BA_DEF_DEF_  "GenMsgNrOfRepetition" 0;
BA_DEF_DEF_  "GenMsgRequestable" 0;
BA_DEF_DEF_  "GenMsgSendType" "noMsgSendType";
BA_DEF_DEF_  "GenMsgStartDelayTime" 0;
BA_DEF_DEF_  "TpJ1939VarDlc" "No";
BA_DEF_DEF_  "VFrameFormat" "J1939PG";
BA_DEF_DEF_  "CI_ParId" "";
BA_DEF_DEF_  "CI_SigId" 0;
BA_DEF_DEF_  "CI_SigName" "";
BA_DEF_DEF_  "GenSigEVName" "Env@Nodename_@Signame";
BA_DEF_DEF_  "GenSigILSupport" "Yes";
BA_DEF_DEF_  "GenSigInactiveValue" 0;
BA_DEF_DEF_  "GenSigSendType" "NoSigSendType";
BA_DEF_DEF_  "GenSigStartValue" 0;
BA_DEF_DEF_  "GenSigTimeoutTime_ACM_CANAIR" 0;
BA_DEF_DEF_  "GenSigTimeoutTime_ACU" 0;
BA_DEF_DEF_  "GenSigTimeoutTime_ADCU" 0;
BA_DEF_DEF_  "GenSigTimeoutTime_AI_CAID" 0;
BA_DEF_DEF_  "GenSigTimeoutTime_ASM_ELC5_Fr" 0;
BA_DEF_DEF_  "GenSigTimeoutTime_AVAS" 0;
BA_DEF_DEF_  "GenSigTimeoutTime_Av2HP" 0;
BA_DEF_DEF_  "GenSigTimeoutTime_BCM_NBM" 0;
BA_DEF_DEF_  "GenSigTimeoutTime_BSM_EBS" 0;
BA_DEF_DEF_  "GenSigTimeoutTime_DICO" 0;
BA_DEF_DEF_  "GenSigTimeoutTime_DMS" 0;
BA_DEF_DEF_  "GenSigTimeoutTime_EBS_EBR" 0;
BA_DEF_DEF_  "GenSigTimeoutTime_ECM_MD1_D" 0;
BA_DEF_DEF_  "GenSigTimeoutTime_ECM_MD1_G" 0;
BA_DEF_DEF_  "GenSigTimeoutTime_ETC_DiwaNXT" 0;
BA_DEF_DEF_  "GenSigTimeoutTime_ETC_DiwaNXT_MH" 0;
BA_DEF_DEF_  "GenSigTimeoutTime_ETC_Ecolife2" 0;
BA_DEF_DEF_  "GenSigTimeoutTime_FCCU" 0;
BA_DEF_DEF_  "GenSigTimeoutTime_FMS_FMS4" 0;
BA_DEF_DEF_  "GenSigTimeoutTime_FMS_FMS5" 0;
BA_DEF_DEF_  "GenSigTimeoutTime_HVPDU_HV_BOX" 0;
BA_DEF_DEF_  "GenSigTimeoutTime_IC_MulticII" 0;
BA_DEF_DEF_  "GenSigTimeoutTime_IC_MulticS" 0;
BA_DEF_DEF_  "GenSigTimeoutTime_INVEM1_ELFA3" 0;
BA_DEF_DEF_  "GenSigTimeoutTime_MBMS" 0;
BA_DEF_DEF_  "GenSigTimeoutTime_MCSL" 0;
BA_DEF_DEF_  "GenSigTimeoutTime_MPPxPTFE2" 0;
BA_DEF_DEF_  "GenSigTimeoutTime_PCM" 0;
BA_DEF_DEF_  "GenSigTimeoutTime_RDAB_SmtRadio" 0;
BA_DEF_DEF_  "GenSigTimeoutTime_RM_INTD" 0;
BA_DEF_DEF_  "GenSigTimeoutTime_RM_IRCS" 0;
BA_DEF_DEF_  "GenSigTimeoutTime_SAS" 0;
BA_DEF_DEF_  "GenSigTimeoutTime_SGW" 0;
BA_DEF_DEF_  "GenSigTimeoutTime_SGW2" 0;
BA_DEF_DEF_  "GenSigTimeoutTime_TASM_ETS" 0;
BA_DEF_DEF_  "GenSigTimeoutTime_TMU_HP_Fr" 0;
BA_DEF_DEF_  "GenSigTimeoutTime_TMU_HP_Rr" 0;
BA_DEF_DEF_  "GenSigTimeoutTime_TPMS" 0;
BA_DEF_DEF_  "GenSigTimeoutTime_Tacho_DTCO" 0;
BA_DEF_DEF_  "GenSigTimeoutTime_Tacho_MTCO" 0;
BA_DEF_DEF_  "GenSigTimeoutTime_Tacho_TSU" 0;
BA_DEF_DEF_  "GenSigTimeoutTime_VCM" 0;
BA_DEF_DEF_  "GenSigTimeoutTime_VCU" 0;
BA_DEF_DEF_  "GenSigTimeoutTime_VMU" 0;
BA_DEF_DEF_  "SPN" 0;
BA_DEF_DEF_  "SigType" "Default";
BA_DEF_DEF_  "ILUsed" "Yes";
BA_DEF_DEF_  "NmStationAddress" 254;
BA_DEF_DEF_  "NodeLayerModules" "J1939_IL.dll";
BA_DEF_DEF_  "Baudrate" 0;
BA_DEF_DEF_  "BusType" "";
BA_DEF_DEF_  "CI_CcdVersion" "";
BA_DEF_DEF_  "Manufacturer" "";
BA_ "Manufacturer" "Vector";
BA_ "CI_CcdVersion" "AE";
BA_ "BusType" "CAN";
BA_ "Baudrate" 500000;
BA_ "NmStationAddress" BU_ MD1_ECM 0;
BA_ "NmStationAddress" BU_ ETC 3;
BA_ "NmStationAddress" BU_ NODE_5 5;
BA_ "NmStationAddress" BU_ BSM_EBS 11;
BA_ "NmStationAddress" BU_ RM_IRCS 16;
BA_ "NmStationAddress" BU_ IC_Multic 23;
BA_ "NmStationAddress" BU_ SGW 29;
BA_ "NmStationAddress" BU_ BCM_NBM 33;
BA_ "NmStationAddress" BU_ VCM 39;
BA_ "NmStationAddress" BU_ NODE_31 49;
BA_ "NmStationAddress" BU_ ETS 56;
BA_ "NmStationAddress" BU_ NODE_45 69;
BA_ "NmStationAddress" BU_ FCCU 73;
BA_ "NmStationAddress" BU_ DICO 90;
BA_ "NmStationAddress" BU_ NODE_72 114;
BA_ "NmStationAddress" BU_ FMReceiver 117;
BA_ "NmStationAddress" BU_ SGW2 126;
BA_ "NmStationAddress" BU_ VCU 128;
BA_ "NmStationAddress" BU_ ADCU 158;
BA_ "NmStationAddress" BU_ MRGEN 160;
BA_ "NmStationAddress" BU_ DTCO 238;
BA_ "NmStationAddress" BU_ MBMS 243;
BA_ "NmStationAddress" BU_ TPMS 51;
BA_ "NmStationAddress" BU_ AI_CAID 94;
BA_ "NmStationAddress" BU_ ELC 47;
BA_ "NmStationAddress" BU_ ELC_R 64;
BA_ "NmStationAddress" BU_ NODE_F7 247;
BA_ "NmStationAddress" BU_ BMS3 246;
BA_ "NmStationAddress" BU_ TUROLLA 46;
BA_ "NmStationAddress" BU_ PCM 74;
BA_ "NmStationAddress" BU_ SRR_Front_Left 144;
BA_ "NmStationAddress" BU_ SRR_Rear_Right 145;
BA_ "NmStationAddress" BU_ SRR_Front_Right 146;
BA_ "NmStationAddress" BU_ SRR_Front 156;
BA_ "NmStationAddress" BU_ SRR_Rear_Left 232;
BA_ "NmStationAddress" BU_ ELFA3_S 240;
BA_ "NmStationAddress" BU_ THERMOKING_M 25;
BA_ "NmStationAddress" BU_ TMU_HP_Rr 58;
BA_ "NmStationAddress" BU_ NODE_B1 177;
BA_ "NmStationAddress" BU_ NODE_B2 178;
BA_ "NmStationAddress" BU_ NODE_B3 179;
BA_ "NmStationAddress" BU_ NODE_B4 180;
BA_ "NmStationAddress" BU_ NODE_B5 181;
BA_ "NmStationAddress" BU_ NODE_B6 182;
BA_ "NmStationAddress" BU_ NODE_B7 183;
BA_ "NmStationAddress" BU_ NODE_B8 184;
BA_ "NmStationAddress" BU_ BMS2 245;
BA_ "NmStationAddress" BU_ NODE_B9 185;
BA_ "NmStationAddress" BU_ NODE_BA 186;
BA_ "NmStationAddress" BU_ NODE_FC 252;
BA_ "NmStationAddress" BU_ NODE_BB 187;
BA_ "NmStationAddress" BU_ NODE_BC 188;
BA_ "NmStationAddress" BU_ NODE_BE 190;
BA_ "NmStationAddress" BU_ NODE_BD 189;
BA_ "NmStationAddress" BU_ NODE_BF 191;
BA_ "NmStationAddress" BU_ ACU 231;
BA_ "NmStationAddress" BU_ NODE_C0 192;
BA_ "NmStationAddress" BU_ BMS1 244;
BA_ "NmStationAddress" BU_ NODE_C1 193;
BA_ "NmStationAddress" BU_ FCU 194;
BA_ "NmStationAddress" BU_ NODE_C3 195;
BA_ "NmStationAddress" BU_ NODE_C4 196;
BA_ "NmStationAddress" BU_ NODE_EC 236;
BA_ "NmStationAddress" BU_ NODE_C5 197;
BA_ "NmStationAddress" BU_ NODE_C6 198;
BA_ "NmStationAddress" BU_ NODE_C7 199;
BA_ "NmStationAddress" BU_ NODE_C8 200;
BA_ "NmStationAddress" BU_ VCU2 201;
BA_ "NmStationAddress" BU_ NODE_CA 202;
BA_ "NmStationAddress" BU_ NODE_CB 203;
BA_ "NmStationAddress" BU_ NODE_CD 205;
BA_ "NmStationAddress" BU_ NODE_CE 206;
BA_ "NmStationAddress" BU_ NODE_CF 207;
BA_ "NmStationAddress" BU_ NODE_ED 237;
BA_ "NmStationAddress" BU_ ST_ScanTool 241;
BA_ "NmStationAddress" BU_ MASTER68_STD1 208;
BA_ "NmStationAddress" BU_ NODE_D1 209;
BA_ "NmStationAddress" BU_ NODE_F2 242;
BA_ "NmStationAddress" BU_ NODE_FD 253;
BA_ "NmStationAddress" BU_ NODE_D2 210;
BA_ "NmStationAddress" BU_ MCSL 234;
BA_ "NmStationAddress" BU_ NODE_EB 235;
BA_ "NmStationAddress" BU_ NODE_D3 211;
BA_ "NmStationAddress" BU_ NODE_D4 212;
BA_ "NmStationAddress" BU_ NODE_D5 213;
BA_ "NmStationAddress" BU_ NODE_D6 214;
BA_ "NmStationAddress" BU_ VCCU 215;
BA_ "NmStationAddress" BU_ NODE_D8 216;
BA_ "NmStationAddress" BU_ NODE_D9 217;
BA_ "NmStationAddress" BU_ NODE_F9 249;
BA_ "NmStationAddress" BU_ DiagTool 250;
BA_ "NmStationAddress" BU_ NODE_DA 218;
BA_ "NmStationAddress" BU_ NODE_DB 219;
BA_ "NmStationAddress" BU_ NODE_DC 220;
BA_ "NmStationAddress" BU_ NODE_DD 221;
BA_ "NmStationAddress" BU_ NODE_DE 222;
BA_ "NmStationAddress" BU_ NODE_DF 223;
BA_ "NmStationAddress" BU_ NODE_E0 224;
BA_ "NmStationAddress" BU_ NODE_E1 225;
BA_ "NmStationAddress" BU_ NODE_E2 226;
BA_ "NmStationAddress" BU_ NODE_E9 233;
BA_ "NmStationAddress" BU_ NODE_E3 227;
BA_ "NmStationAddress" BU_ SAS 228;
BA_ "NmStationAddress" BU_ NODE_FB 251;
BA_ "NmStationAddress" BU_ NODE_F8 248;
BA_ "NmStationAddress" BU_ NODE_E6 230;
BA_ "NmStationAddress" BU_ ELFA3 239;
BA_ "NmStationAddress" BU_ NODE_F 15;
BA_ "NmStationAddress" BU_ THERMOKING_D 26;
BA_ "NmStationAddress" BU_ FMS 37;
BA_ "NmStationAddress" BU_ MULTIC_S 96;
BA_ "NmStationAddress" BU_ MULTIC_2 98;
BA_ "NmStationAddress" BU_ BMS4 134;
BA_ "NmStationAddress" BU_ BMS5 135;
BA_ "NmStationAddress" BU_ BMS6 136;
BA_ "NmStationAddress" BU_ BMS7 137;
BA_ "NmStationAddress" BU_ BMS8 138;
BA_ "NmStationAddress" BU_ BMS9 139;
BA_ "NmStationAddress" BU_ BMS10 140;
BA_ "NmStationAddress" BU_ BMS11 141;
BA_ "NmStationAddress" BU_ NODE_71 113;
BA_ "GenMsgStartDelayTime" BO_ 2566725632 25;
BA_ "GenMsgSendType" BO_ 2566725632 0;
BA_ "GenMsgDelayTime" BO_ 2566725632 250;
BA_ "GenMsgCycleTimeFast" BO_ 2566725632 500;
BA_ "GenMsgCycleTime" BO_ 2566725632 500;
BA_ "CI_MsgName" BO_ 2566725632 "A1DOC1 - Aftertreatment 1 Diesel Oxidation Catalyst 1";
BA_ "CI_MsgId" BO_ 2566725632 1604;
BA_ "CI_MsgDefinition" BO_ 2566725632 "J1939DA";
BA_ "GenMsgStartDelayTime" BO_ 2565874432 11;
BA_ "GenMsgSendType" BO_ 2565874432 0;
BA_ "GenMsgDelayTime" BO_ 2565874432 25;
BA_ "GenMsgCycleTimeFast" BO_ 2565874432 50;
BA_ "GenMsgCycleTime" BO_ 2565874432 50;
BA_ "CI_MsgName" BO_ 2565874432 "A1SCRDSI1 - Aftertreatment 1 SCR Dosing System Information 1";
BA_ "CI_MsgId" BO_ 2565874432 1238;
BA_ "CI_MsgDefinition" BO_ 2565874432 "J1939DA";
BA_ "GenMsgStartDelayTime" BO_ 2499624448 24;
BA_ "GenMsgSendType" BO_ 2499624448 0;
BA_ "GenMsgDelayTime" BO_ 2499624448 250;
BA_ "GenMsgCycleTimeFast" BO_ 2499624448 500;
BA_ "GenMsgCycleTime" BO_ 2499624448 500;
BA_ "CI_MsgName" BO_ 2499624448 "A1SCREGT1 - Aftertreatment 1 SCR Exhaust Gas Temperature 1";
BA_ "CI_MsgId" BO_ 2499624448 1611;
BA_ "CI_MsgDefinition" BO_ 2499624448 "J1939DA";
BA_ "GenMsgStartDelayTime" BO_ 2566811431 22;
BA_ "GenMsgSendType" BO_ 2566811431 0;
BA_ "GenMsgDelayTime" BO_ 2566811431 50;
BA_ "GenMsgCycleTimeFast" BO_ 2566811431 100;
BA_ "GenMsgCycleTime" BO_ 2566811431 100;
BA_ "CI_MsgName" BO_ 2566811431 "ACC1_27 - Adaptive Cruise Control 1";
BA_ "CI_MsgId" BO_ 2566811431 3765;
BA_ "CI_MsgDefinition" BO_ 2566811431 "J1939DA";
BA_ "GenMsgStartDelayTime" BO_ 2566803735 60;
BA_ "GenMsgSendType" BO_ 2566803735 0;
BA_ "GenMsgDelayTime" BO_ 2566803735 125;
BA_ "GenMsgCycleTimeFast" BO_ 2566803735 250;
BA_ "GenMsgCycleTime" BO_ 2566803735 250;
BA_ "CI_MsgName" BO_ 2566803735 "ACC2_17 - Adaptive Cruise Control, Operator Input";
BA_ "CI_MsgId" BO_ 2566803735 3787;
BA_ "CI_MsgDefinition" BO_ 2566803735 "J1939DA";
BA_ "CI_MsgName" BO_ 2565406464 "ACKM_00 - Acknowledgment Message";
BA_ "CI_MsgId" BO_ 2565406464 11104;
BA_ "CI_MsgDefinition" BO_ 2565406464 "J1939-21";
BA_ "CI_MsgName" BO_ 2565406467 "ACKM_03 - Acknowledgment Message";
BA_ "CI_MsgId" BO_ 2565406467 11146;
BA_ "CI_MsgDefinition" BO_ 2565406467 "J1939-21";
BA_ "GenMsgDelayTime" BO_ 2565406475 200;
BA_ "CI_MsgName" BO_ 2565406475 "ACKM_0B - Acknowledgment Message";
BA_ "CI_MsgId" BO_ 2565406475 11160;
BA_ "CI_MsgDefinition" BO_ 2565406475 "J1939-21";
BA_ "CI_MsgName" BO_ 2565406487 "ACKM_17 - Acknowledgment Message";
BA_ "CI_MsgId" BO_ 2565406487 11174;
BA_ "CI_MsgDefinition" BO_ 2565406487 "J1939-21";
BA_ "CI_MsgName" BO_ 2565406492 "ACKM_1C - Acknowledgment Message";
BA_ "CI_MsgId" BO_ 2565406492 11188;
BA_ "CI_MsgDefinition" BO_ 2565406492 "J1939-21";
BA_ "CI_MsgName" BO_ 2565406493 "ACKM_1D - Acknowledgment Message";
BA_ "CI_MsgId" BO_ 2565406493 11202;
BA_ "CI_MsgDefinition" BO_ 2565406493 "J1939-21";
BA_ "CI_MsgName" BO_ 2565406503 "ACKM_27 - Acknowledgment Message";
BA_ "CI_MsgId" BO_ 2565406503 11216;
BA_ "CI_MsgDefinition" BO_ 2565406503 "J1939-21";
BA_ "CI_MsgName" BO_ 2565406515 "ACKM_33 - Acknowledgment Message";
BA_ "CI_MsgId" BO_ 2565406515 13488;
BA_ "CI_MsgDefinition" BO_ 2565406515 "J1939-21";
BA_ "CI_MsgName" BO_ 2565406520 "ACKM_38 - Acknowledgment Message";
BA_ "CI_MsgId" BO_ 2565406520 11326;
BA_ "CI_MsgDefinition" BO_ 2565406520 "J1939-21";
BA_ "CI_MsgName" BO_ 2565406590 "ACKM_7E - Acknowledgment Message";
BA_ "CI_MsgId" BO_ 2565406590 11258;
BA_ "CI_MsgDefinition" BO_ 2565406590 "J1939-21";
BA_ "CI_MsgName" BO_ 2565406622 "ACKM_9E - Acknowledgment Message";
BA_ "CI_MsgId" BO_ 2565406622 17283;
BA_ "CI_MsgDefinition" BO_ 2565406622 "J1939-21";
BA_ "CI_MsgName" BO_ 2565406624 "ACKM_A0 - Acknowledgment Message";
BA_ "CI_MsgId" BO_ 2565406624 11272;
BA_ "CI_MsgDefinition" BO_ 2565406624 "J1939-21";
BA_ "GenMsgStartDelayTime" BO_ 2364551072 2;
BA_ "GenMsgSendType" BO_ 2364551072 0;
BA_ "GenMsgDelayTime" BO_ 2364551072 10;
BA_ "GenMsgCycleTimeFast" BO_ 2364551072 50;
BA_ "GenMsgCycleTime" BO_ 2364551072 50;
BA_ "CI_MsgName" BO_ 2364551072 "AEBS1_A0 - Advanced Emergency Braking System 1";
BA_ "CI_MsgId" BO_ 2364551072 363;
BA_ "CI_MsgDefinition" BO_ 2364551072 "J1939DA";
BA_ "GenMsgStartDelayTime" BO_ 2349572119 59;
BA_ "GenMsgSendType" BO_ 2349572119 0;
BA_ "GenMsgDelayTime" BO_ 2349572119 125;
BA_ "GenMsgCycleTimeFast" BO_ 2349572119 250;
BA_ "GenMsgCycleTime" BO_ 2349572119 250;
BA_ "CI_MsgName" BO_ 2349572119 "AEBS2_17_A0 - Advanced Emergency Braking System 2";
BA_ "CI_MsgId" BO_ 2349572119 372;
BA_ "CI_MsgDefinition" BO_ 2349572119 "J1939 p2p";
BA_ "GenMsgStartDelayTime" BO_ 2566827553 120;
BA_ "GenMsgSendType" BO_ 2566827553 0;
BA_ "GenMsgDelayTime" BO_ 2566827553 500;
BA_ "GenMsgCycleTimeFast" BO_ 2566827553 1000;
BA_ "GenMsgCycleTime" BO_ 2566827553 1000;
BA_ "CI_MsgName" BO_ 2566827553 "AIR1_21 - Air Supply Pressure";
BA_ "CI_MsgId" BO_ 2566827553 2597;
BA_ "CI_MsgDefinition" BO_ 2566827553 "J1939DA";
BA_ "GenMsgSendType" BO_ 2566620766 0;
BA_ "GenMsgDelayTime" BO_ 2566620766 100;
BA_ "GenMsgCycleTimeFast" BO_ 2566620766 200;
BA_ "GenMsgCycleTime" BO_ 2566620766 200;
BA_ "CI_MsgName" BO_ 2566620766 "AITOV - Alcohol Interlock To Vehicle";
BA_ "CI_MsgId" BO_ 2566620766 2611;
BA_ "CI_MsgDefinition" BO_ 2566620766 "CENELEC EN 50436-4";
BA_ "GenMsgStartDelayTime" BO_ 2566845696 44;
BA_ "GenMsgSendType" BO_ 2566845696 0;
BA_ "GenMsgDelayTime" BO_ 2566845696 500;
BA_ "GenMsgCycleTimeFast" BO_ 2566845696 1000;
BA_ "GenMsgCycleTime" BO_ 2566845696 1000;
BA_ "CI_MsgName" BO_ 2566845696 "AMB_00 - Ambient Conditions";
BA_ "CI_MsgId" BO_ 2566845696 2024;
BA_ "CI_MsgDefinition" BO_ 2566845696 "J1939DA";
BA_ "GenMsgStartDelayTime" BO_ 2566845719 133;
BA_ "GenMsgSendType" BO_ 2566845719 0;
BA_ "GenMsgDelayTime" BO_ 2566845719 500;
BA_ "GenMsgCycleTimeFast" BO_ 2566845719 1000;
BA_ "GenMsgCycleTime" BO_ 2566845719 1000;
BA_ "CI_MsgName" BO_ 2566845719 "AMB_17 - Ambient Conditions";
BA_ "CI_MsgId" BO_ 2566845719 2030;
BA_ "CI_MsgDefinition" BO_ 2566845719 "J1939DA";
BA_ "GenMsgStartDelayTime" BO_ 2565920602 8;
BA_ "GenMsgSendType" BO_ 2565920602 0;
BA_ "GenMsgDelayTime" BO_ 2565920602 50;
BA_ "GenMsgCycleTimeFast" BO_ 2565920602 100;
BA_ "GenMsgCycleTime" BO_ 2565920602 100;
BA_ "CI_MsgName" BO_ 2565920602 "API1_O1_STATUS - Accessory Power Inverter 1 STATUS - Output 1";
BA_ "CI_MsgId" BO_ 2565920602 2058;
BA_ "CI_MsgDefinition" BO_ 2565920602 "J1939DA";
BA_ "GenMsgStartDelayTime" BO_ 2565921626 10;
BA_ "GenMsgSendType" BO_ 2565921626 0;
BA_ "GenMsgDelayTime" BO_ 2565921626 50;
BA_ "GenMsgCycleTimeFast" BO_ 2565921626 100;
BA_ "GenMsgCycleTime" BO_ 2565921626 100;
BA_ "CI_MsgName" BO_ 2565921626 "API1_O2_STATUS - Accessory Power Inverter 1 STATUS - Output 2";
BA_ "CI_MsgId" BO_ 2565921626 2074;
BA_ "CI_MsgDefinition" BO_ 2565921626 "J1939DA";
BA_ "GenMsgStartDelayTime" BO_ 2565922650 12;
BA_ "GenMsgSendType" BO_ 2565922650 0;
BA_ "GenMsgDelayTime" BO_ 2565922650 50;
BA_ "GenMsgCycleTimeFast" BO_ 2565922650 100;
BA_ "GenMsgCycleTime" BO_ 2565922650 100;
BA_ "CI_MsgName" BO_ 2565922650 "API1_O3_STATUS - Accessory Power Inverter 1 STATUS - Output 3";
BA_ "CI_MsgId" BO_ 2565922650 14810;
BA_ "CI_MsgDefinition" BO_ 2565922650 "J1939DA";
BA_ "GenMsgStartDelayTime" BO_ 2566837527 85;
BA_ "GenMsgSendType" BO_ 2566837527 0;
BA_ "GenMsgDelayTime" BO_ 2566837527 100;
BA_ "GenMsgCycleTimeFast" BO_ 2566837527 1000;
BA_ "GenMsgCycleTime" BO_ 2566837527 1000;
BA_ "CI_MsgName" BO_ 2566837527 "AS_17 - Alternator Information";
BA_ "CI_MsgId" BO_ 2566837527 2199;
BA_ "CI_MsgDefinition" BO_ 2566837527 "J1939DA";
BA_ "GenMsgSendType" BO_ 2365479471 0;
BA_ "GenMsgDelayTime" BO_ 2365479471 50;
BA_ "GenMsgCycleTimeFast" BO_ 2365479471 100;
BA_ "GenMsgCycleTime" BO_ 2365479471 100;
BA_ "CI_MsgName" BO_ 2365479471 "ASC1_A - Air Suspension Control 1";
BA_ "CI_MsgId" BO_ 2365479471 3012;
BA_ "CI_MsgDefinition" BO_ 2365479471 "J1939DA";
BA_ "GenMsgSendType" BO_ 2365479488 0;
BA_ "GenMsgDelayTime" BO_ 2365479488 50;
BA_ "GenMsgCycleTimeFast" BO_ 2365479488 100;
BA_ "GenMsgCycleTime" BO_ 2365479488 100;
BA_ "CI_MsgName" BO_ 2365479488 "ASC1_B - Air Suspension Control 1";
BA_ "CI_MsgId" BO_ 2365479488 3038;
BA_ "CI_MsgDefinition" BO_ 2365479488 "J1939DA";
BA_ "GenMsgStartDelayTime" BO_ 2566805807 4;
BA_ "GenMsgSendType" BO_ 2566805807 0;
BA_ "GenMsgDelayTime" BO_ 2566805807 50;
BA_ "GenMsgCycleTimeFast" BO_ 2566805807 100;
BA_ "GenMsgCycleTime" BO_ 2566805807 100;
BA_ "CI_MsgName" BO_ 2566805807 "ASC3_A - Air Suspension Control 3";
BA_ "CI_MsgId" BO_ 2566805807 3079;
BA_ "CI_MsgDefinition" BO_ 2566805807 "J1939DA";
BA_ "GenMsgStartDelayTime" BO_ 2566805824 4;
BA_ "GenMsgSendType" BO_ 2566805824 0;
BA_ "GenMsgDelayTime" BO_ 2566805824 50;
BA_ "GenMsgCycleTimeFast" BO_ 2566805824 100;
BA_ "GenMsgCycleTime" BO_ 2566805824 100;
BA_ "CI_MsgName" BO_ 2566805824 "ASC3_B - Air Suspension Control 3";
BA_ "CI_MsgId" BO_ 2566805824 3084;
BA_ "CI_MsgDefinition" BO_ 2566805824 "J1939DA";
BA_ "GenMsgStartDelayTime" BO_ 2566805551 2;
BA_ "GenMsgSendType" BO_ 2566805551 0;
BA_ "GenMsgDelayTime" BO_ 2566805551 50;
BA_ "GenMsgCycleTimeFast" BO_ 2566805551 100;
BA_ "GenMsgCycleTime" BO_ 2566805551 100;
BA_ "CI_MsgName" BO_ 2566805551 "ASC4_A - Air Suspension Control 4";
BA_ "CI_MsgId" BO_ 2566805551 3089;
BA_ "CI_MsgDefinition" BO_ 2566805551 "J1939DA";
BA_ "GenMsgStartDelayTime" BO_ 2566805568 2;
BA_ "GenMsgSendType" BO_ 2566805568 0;
BA_ "GenMsgDelayTime" BO_ 2566805568 50;
BA_ "GenMsgCycleTimeFast" BO_ 2566805568 100;
BA_ "GenMsgCycleTime" BO_ 2566805568 100;
BA_ "CI_MsgName" BO_ 2566805568 "ASC4_B - Air Suspension Control 4";
BA_ "CI_MsgId" BO_ 2566805568 3094;
BA_ "CI_MsgDefinition" BO_ 2566805568 "J1939DA";
BA_ "GenMsgStartDelayTime" BO_ 2566763520 26;
BA_ "GenMsgSendType" BO_ 2566763520 0;
BA_ "GenMsgDelayTime" BO_ 2566763520 250;
BA_ "GenMsgCycleTimeFast" BO_ 2566763520 500;
BA_ "GenMsgCycleTime" BO_ 2566763520 500;
BA_ "CI_MsgName" BO_ 2566763520 "AT1IG2 - Aftertreatment 1 Intake Gas 2";
BA_ "CI_MsgId" BO_ 2566763520 1226;
BA_ "CI_MsgDefinition" BO_ 2566763520 "J1939DA";
BA_ "GenMsgStartDelayTime" BO_ 2566804992 46;
BA_ "GenMsgSendType" BO_ 2566804992 0;
BA_ "GenMsgDelayTime" BO_ 2566804992 500;
BA_ "GenMsgCycleTimeFast" BO_ 2566804992 1000;
BA_ "GenMsgCycleTime" BO_ 2566804992 1000;
BA_ "CI_MsgName" BO_ 2566804992 "AT1T1I1 - Aftertreatment 1 Diesel Exhaust Fluid Tank 1 Information 1";
BA_ "CI_MsgId" BO_ 2566804992 1245;
BA_ "CI_MsgDefinition" BO_ 2566804992 "J1939DA";
BA_ "GenMsgStartDelayTime" BO_ 2566849271 16;
BA_ "GenMsgSendType" BO_ 2566849271 0;
BA_ "GenMsgDelayTime" BO_ 2566849271 50;
BA_ "GenMsgCycleTimeFast" BO_ 2566849271 100;
BA_ "GenMsgCycleTime" BO_ 2566849271 100;
BA_ "CI_MsgName" BO_ 2566849271 "Aux1DC - Aux1DCDCFeedback";
BA_ "CI_MsgId" BO_ 2566849271 1255;
BA_ "CI_MsgDefinition" BO_ 2566849271 "Iveco Proprietary";
BA_ "GenMsgStartDelayTime" BO_ 2566849015 14;
BA_ "GenMsgSendType" BO_ 2566849015 0;
BA_ "GenMsgDelayTime" BO_ 2566849015 50;
BA_ "GenMsgCycleTimeFast" BO_ 2566849015 100;
BA_ "GenMsgCycleTime" BO_ 2566849015 100;
BA_ "CI_MsgName" BO_ 2566849015 "Aux1Mot - Aux1MotorFeedback";
BA_ "CI_MsgId" BO_ 2566849015 1261;
BA_ "CI_MsgDefinition" BO_ 2566849015 "Iveco Proprietary";
BA_ "GenMsgStartDelayTime" BO_ 2566848759 12;
BA_ "GenMsgSendType" BO_ 2566848759 0;
BA_ "GenMsgDelayTime" BO_ 2566848759 50;
BA_ "GenMsgCycleTimeFast" BO_ 2566848759 100;
BA_ "GenMsgCycleTime" BO_ 2566848759 100;
BA_ "CI_MsgName" BO_ 2566848759 "Aux1St - Aux1Status";
BA_ "CI_MsgId" BO_ 2566848759 1266;
BA_ "CI_MsgDefinition" BO_ 2566848759 "Iveco Proprietary";
BA_ "GenMsgStartDelayTime" BO_ 2566849270 15;
BA_ "GenMsgSendType" BO_ 2566849270 0;
BA_ "GenMsgDelayTime" BO_ 2566849270 50;
BA_ "GenMsgCycleTimeFast" BO_ 2566849270 100;
BA_ "GenMsgCycleTime" BO_ 2566849270 100;
BA_ "CI_MsgName" BO_ 2566849270 "Aux2DC - Aux2DCDCFeedback";
BA_ "CI_MsgId" BO_ 2566849270 1269;
BA_ "CI_MsgDefinition" BO_ 2566849270 "Iveco Proprietary";
BA_ "GenMsgStartDelayTime" BO_ 2566849014 13;
BA_ "GenMsgSendType" BO_ 2566849014 0;
BA_ "GenMsgDelayTime" BO_ 2566849014 50;
BA_ "GenMsgCycleTimeFast" BO_ 2566849014 100;
BA_ "GenMsgCycleTime" BO_ 2566849014 100;
BA_ "CI_MsgName" BO_ 2566849014 "Aux2Mot - Aux2MotorFeedback";
BA_ "CI_MsgId" BO_ 2566849014 1275;
BA_ "CI_MsgDefinition" BO_ 2566849014 "Iveco Proprietary";
BA_ "GenMsgStartDelayTime" BO_ 2566848758 11;
BA_ "GenMsgSendType" BO_ 2566848758 0;
BA_ "GenMsgDelayTime" BO_ 2566848758 50;
BA_ "GenMsgCycleTimeFast" BO_ 2566848758 100;
BA_ "GenMsgCycleTime" BO_ 2566848758 100;
BA_ "CI_MsgName" BO_ 2566848758 "Aux2St - Aux2Status";
BA_ "CI_MsgId" BO_ 2566848758 1280;
BA_ "CI_MsgDefinition" BO_ 2566848758 "Iveco Proprietary";
BA_ "GenMsgStartDelayTime" BO_ 2566838561 66;
BA_ "GenMsgSendType" BO_ 2566838561 0;
BA_ "GenMsgDelayTime" BO_ 2566838561 100;
BA_ "GenMsgCycleTimeFast" BO_ 2566838561 100;
BA_ "GenMsgCycleTime" BO_ 2566838561 100;
BA_ "CI_MsgName" BO_ 2566838561 "AUXIO1_21 - Auxiliary Input/Output Status 1";
BA_ "CI_MsgId" BO_ 2566838561 2948;
BA_ "CI_MsgDefinition" BO_ 2566838561 "J1939DA";
BA_ "SigType" SG_ 2566725632 At1DocInTemp 1;
BA_ "SPN" SG_ 2566725632 At1DocInTemp 4765;
BA_ "GenSigTimeoutTime_SGW" SG_ 2566725632 At1DocInTemp 2500;
BA_ "GenSigTimeoutTime_PCM" SG_ 2566725632 At1DocInTemp 2500;
BA_ "GenSigStartValue" SG_ 2566725632 At1DocInTemp 8736;
BA_ "CI_SigName" SG_ 2566725632 At1DocInTemp "Aftertreatment 1 Diesel Oxidation Catalyst Intake Temperature";
BA_ "CI_SigId" SG_ 2566725632 At1DocInTemp 1605;
BA_ "CI_ParId" SG_ 2566725632 At1DocInTemp "4765";
BA_ "SigType" SG_ 2565874432 At1DefActDosQty 1;
BA_ "SPN" SG_ 2565874432 At1DefActDosQty 4331;
BA_ "GenSigTimeoutTime_VCM" SG_ 2565874432 At1DefActDosQty 500;
BA_ "GenSigTimeoutTime_SGW" SG_ 2565874432 At1DefActDosQty 500;
BA_ "GenSigTimeoutTime_PCM" SG_ 2565874432 At1DefActDosQty 500;
BA_ "CI_SigName" SG_ 2565874432 At1DefActDosQty "Aftertreatment 1 Diesel Exhaust Fluid Actual Dosing Quantity";
BA_ "CI_SigId" SG_ 2565874432 At1DefActDosQty 1239;
BA_ "CI_ParId" SG_ 2565874432 At1DefActDosQty "4331";
BA_ "SigType" SG_ 2499624448 At1ScrOutTemp 1;
BA_ "SPN" SG_ 2499624448 At1ScrOutTemp 4363;
BA_ "GenSigTimeoutTime_SGW" SG_ 2499624448 At1ScrOutTemp 2500;
BA_ "GenSigTimeoutTime_PCM" SG_ 2499624448 At1ScrOutTemp 2500;
BA_ "GenSigStartValue" SG_ 2499624448 At1ScrOutTemp 8736;
BA_ "CI_SigName" SG_ 2499624448 At1ScrOutTemp "Aftertreatment 1 SCR Outlet Temperature";
BA_ "CI_SigId" SG_ 2499624448 At1ScrOutTemp 1614;
BA_ "CI_ParId" SG_ 2499624448 At1ScrOutTemp "4363";
BA_ "SigType" SG_ 2499624448 At1ScrInTemp 1;
BA_ "SPN" SG_ 2499624448 At1ScrInTemp 4360;
BA_ "GenSigTimeoutTime_SGW" SG_ 2499624448 At1ScrInTemp 2500;
BA_ "GenSigTimeoutTime_PCM" SG_ 2499624448 At1ScrInTemp 2500;
BA_ "GenSigStartValue" SG_ 2499624448 At1ScrInTemp 8736;
BA_ "CI_SigName" SG_ 2499624448 At1ScrInTemp "Aftertreatment 1 SCR Intake Temperature";
BA_ "CI_SigId" SG_ 2499624448 At1ScrInTemp 1612;
BA_ "CI_ParId" SG_ 2499624448 At1ScrInTemp "4360";
BA_ "SPN" SG_ 2566811431 AccSetDistMode 1589;
BA_ "GenSigTimeoutTime_SGW" SG_ 2566811431 AccSetDistMode 500;
BA_ "GenSigTimeoutTime_PCM" SG_ 2566811431 AccSetDistMode 500;
BA_ "GenSigTimeoutTime_IC_MulticS" SG_ 2566811431 AccSetDistMode 500;
BA_ "CI_SigName" SG_ 2566811431 AccSetDistMode "Adaptive cruise control set distance mode";
BA_ "CI_SigId" SG_ 2566811431 AccSetDistMode 3770;
BA_ "CI_ParId" SG_ 2566811431 AccSetDistMode "1589";
BA_ "SPN" SG_ 2566811431 AccMode 1590;
BA_ "GenSigTimeoutTime_SGW" SG_ 2566811431 AccMode 500;
BA_ "GenSigTimeoutTime_PCM" SG_ 2566811431 AccMode 500;
BA_ "GenSigTimeoutTime_IC_MulticS" SG_ 2566811431 AccMode 500;
BA_ "GenSigTimeoutTime_BSM_EBS" SG_ 2566811431 AccMode 500;
BA_ "CI_SigName" SG_ 2566811431 AccMode "Adaptive Cruise Control Mode";
BA_ "CI_SigId" SG_ 2566811431 AccMode 3769;
BA_ "CI_ParId" SG_ 2566811431 AccMode "1590";
BA_ "SigType" SG_ 2566803735 AccUseDem 4;
BA_ "SPN" SG_ 2566803735 AccUseDem 5023;
BA_ "GenSigTimeoutTime_VCM" SG_ 2566803735 AccUseDem 1250;
BA_ "GenSigTimeoutTime_SGW" SG_ 2566803735 AccUseDem 1250;
BA_ "GenSigTimeoutTime_PCM" SG_ 2566803735 AccUseDem 1250;
BA_ "CI_SigName" SG_ 2566803735 AccUseDem "ACC usage demand";
BA_ "CI_SigId" SG_ 2566803735 AccUseDem 3788;
BA_ "CI_ParId" SG_ 2566803735 AccUseDem "5023";
BA_ "SPN" SG_ 2565406464 Pgn_Busy 2549;
BA_ "CI_SigName" SG_ 2565406464 Pgn_Busy "Parameter Group Number (NACK_Busy)";
BA_ "CI_SigId" SG_ 2565406464 Pgn_Busy 11117;
BA_ "CI_ParId" SG_ 2565406464 Pgn_Busy "2549";
BA_ "SPN" SG_ 2565406464 Pgn_Ad 2547;
BA_ "CI_SigName" SG_ 2565406464 Pgn_Ad "Parameter Group Number (NACK_AD)";
BA_ "CI_SigId" SG_ 2565406464 Pgn_Ad 11116;
BA_ "CI_ParId" SG_ 2565406464 Pgn_Ad "2547";
BA_ "SPN" SG_ 2565406464 Pgn_Nack 2545;
BA_ "CI_SigName" SG_ 2565406464 Pgn_Nack "Parameter Group Number (NACK)";
BA_ "CI_SigId" SG_ 2565406464 Pgn_Nack 11115;
BA_ "CI_ParId" SG_ 2565406464 Pgn_Nack "2545";
BA_ "SPN" SG_ 2565406464 Pgn_Ack 2543;
BA_ "CI_SigName" SG_ 2565406464 Pgn_Ack "Parameter Group Number (ACK)";
BA_ "CI_SigId" SG_ 2565406464 Pgn_Ack 11114;
BA_ "CI_ParId" SG_ 2565406464 Pgn_Ack "2543";
BA_ "SPN" SG_ 2565406464 CtrlByte_Ackm 2541;
BA_ "CI_SigName" SG_ 2565406464 CtrlByte_Ackm "Control Byte (ACKM)";
BA_ "CI_SigId" SG_ 2565406464 CtrlByte_Ackm 11105;
BA_ "CI_ParId" SG_ 2565406464 CtrlByte_Ackm "2541";
BA_ "SPN" SG_ 2565406467 Pgn_Busy_E8FF03 2549;
BA_ "CI_SigName" SG_ 2565406467 Pgn_Busy_E8FF03 "Parameter Group Number (NACK_Busy)";
BA_ "CI_SigId" SG_ 2565406467 Pgn_Busy_E8FF03 11159;
BA_ "CI_ParId" SG_ 2565406467 Pgn_Busy_E8FF03 "2549";
BA_ "SPN" SG_ 2565406467 Pgn_Ad_E8FF03 2547;
BA_ "CI_SigName" SG_ 2565406467 Pgn_Ad_E8FF03 "Parameter Group Number (NACK_AD)";
BA_ "CI_SigId" SG_ 2565406467 Pgn_Ad_E8FF03 11158;
BA_ "CI_ParId" SG_ 2565406467 Pgn_Ad_E8FF03 "2547";
BA_ "SPN" SG_ 2565406467 Pgn_Nack_E8FF03 2545;
BA_ "CI_SigName" SG_ 2565406467 Pgn_Nack_E8FF03 "Parameter Group Number (NACK)";
BA_ "CI_SigId" SG_ 2565406467 Pgn_Nack_E8FF03 11157;
BA_ "CI_ParId" SG_ 2565406467 Pgn_Nack_E8FF03 "2545";
BA_ "SPN" SG_ 2565406467 Pgn_Ack_E8FF03 2543;
BA_ "CI_SigName" SG_ 2565406467 Pgn_Ack_E8FF03 "Parameter Group Number (ACK)";
BA_ "CI_SigId" SG_ 2565406467 Pgn_Ack_E8FF03 11156;
BA_ "CI_ParId" SG_ 2565406467 Pgn_Ack_E8FF03 "2543";
BA_ "SPN" SG_ 2565406467 CtrlByte_Ackm_E8FF03 2541;
BA_ "CI_SigName" SG_ 2565406467 CtrlByte_Ackm_E8FF03 "Control Byte (ACKM)";
BA_ "CI_SigId" SG_ 2565406467 CtrlByte_Ackm_E8FF03 11147;
BA_ "CI_ParId" SG_ 2565406467 CtrlByte_Ackm_E8FF03 "2541";
BA_ "SPN" SG_ 2565406475 Pgn_Busy_E8FF0B 2549;
BA_ "CI_SigName" SG_ 2565406475 Pgn_Busy_E8FF0B "Parameter Group Number (NACK_Busy)";
BA_ "CI_SigId" SG_ 2565406475 Pgn_Busy_E8FF0B 11173;
BA_ "CI_ParId" SG_ 2565406475 Pgn_Busy_E8FF0B "2549";
BA_ "SPN" SG_ 2565406475 Pgn_Ad_E8FF0B 2547;
BA_ "CI_SigName" SG_ 2565406475 Pgn_Ad_E8FF0B "Parameter Group Number (NACK_AD)";
BA_ "CI_SigId" SG_ 2565406475 Pgn_Ad_E8FF0B 11172;
BA_ "CI_ParId" SG_ 2565406475 Pgn_Ad_E8FF0B "2547";
BA_ "SPN" SG_ 2565406475 Pgn_Nack_E8FF0B 2545;
BA_ "CI_SigName" SG_ 2565406475 Pgn_Nack_E8FF0B "Parameter Group Number (NACK)";
BA_ "CI_SigId" SG_ 2565406475 Pgn_Nack_E8FF0B 11171;
BA_ "CI_ParId" SG_ 2565406475 Pgn_Nack_E8FF0B "2545";
BA_ "SPN" SG_ 2565406475 Pgn_Ack_E8FF0B 2543;
BA_ "CI_SigName" SG_ 2565406475 Pgn_Ack_E8FF0B "Parameter Group Number (ACK)";
BA_ "CI_SigId" SG_ 2565406475 Pgn_Ack_E8FF0B 11170;
BA_ "CI_ParId" SG_ 2565406475 Pgn_Ack_E8FF0B "2543";
BA_ "SPN" SG_ 2565406475 CtrlByte_Ackm_E8FF0B 2541;
BA_ "CI_SigName" SG_ 2565406475 CtrlByte_Ackm_E8FF0B "Control Byte (ACKM)";
BA_ "CI_SigId" SG_ 2565406475 CtrlByte_Ackm_E8FF0B 11161;
BA_ "CI_ParId" SG_ 2565406475 CtrlByte_Ackm_E8FF0B "2541";
BA_ "SPN" SG_ 2565406487 Pgn_Busy_E8FF17 2549;
BA_ "CI_SigName" SG_ 2565406487 Pgn_Busy_E8FF17 "Parameter Group Number (NACK_Busy)";
BA_ "CI_SigId" SG_ 2565406487 Pgn_Busy_E8FF17 11187;
BA_ "CI_ParId" SG_ 2565406487 Pgn_Busy_E8FF17 "2549";
BA_ "SPN" SG_ 2565406487 Pgn_Ad_E8FF17 2547;
BA_ "CI_SigName" SG_ 2565406487 Pgn_Ad_E8FF17 "Parameter Group Number (NACK_AD)";
BA_ "CI_SigId" SG_ 2565406487 Pgn_Ad_E8FF17 11186;
BA_ "CI_ParId" SG_ 2565406487 Pgn_Ad_E8FF17 "2547";
BA_ "SPN" SG_ 2565406487 Pgn_Nack_E8FF17 2545;
BA_ "CI_SigName" SG_ 2565406487 Pgn_Nack_E8FF17 "Parameter Group Number (NACK)";
BA_ "CI_SigId" SG_ 2565406487 Pgn_Nack_E8FF17 11185;
BA_ "CI_ParId" SG_ 2565406487 Pgn_Nack_E8FF17 "2545";
BA_ "SPN" SG_ 2565406487 Pgn_Ack_E8FF17 2543;
BA_ "CI_SigName" SG_ 2565406487 Pgn_Ack_E8FF17 "Parameter Group Number (ACK)";
BA_ "CI_SigId" SG_ 2565406487 Pgn_Ack_E8FF17 11184;
BA_ "CI_ParId" SG_ 2565406487 Pgn_Ack_E8FF17 "2543";
BA_ "SPN" SG_ 2565406487 CtrlByte_Ackm_E8FF17 2541;
BA_ "CI_SigName" SG_ 2565406487 CtrlByte_Ackm_E8FF17 "Control Byte (ACKM)";
BA_ "CI_SigId" SG_ 2565406487 CtrlByte_Ackm_E8FF17 11175;
BA_ "CI_ParId" SG_ 2565406487 CtrlByte_Ackm_E8FF17 "2541";
BA_ "SPN" SG_ 2565406492 Pgn_Busy_E8FF1C 2549;
BA_ "CI_SigName" SG_ 2565406492 Pgn_Busy_E8FF1C "Parameter Group Number (NACK_Busy)";
BA_ "CI_SigId" SG_ 2565406492 Pgn_Busy_E8FF1C 11201;
BA_ "CI_ParId" SG_ 2565406492 Pgn_Busy_E8FF1C "2549";
BA_ "SPN" SG_ 2565406492 Pgn_Ad_E8FF1C 2547;
BA_ "CI_SigName" SG_ 2565406492 Pgn_Ad_E8FF1C "Parameter Group Number (NACK_AD)";
BA_ "CI_SigId" SG_ 2565406492 Pgn_Ad_E8FF1C 11200;
BA_ "CI_ParId" SG_ 2565406492 Pgn_Ad_E8FF1C "2547";
BA_ "SPN" SG_ 2565406492 Pgn_Nack_E8FF1C 2545;
BA_ "CI_SigName" SG_ 2565406492 Pgn_Nack_E8FF1C "Parameter Group Number (NACK)";
BA_ "CI_SigId" SG_ 2565406492 Pgn_Nack_E8FF1C 11199;
BA_ "CI_ParId" SG_ 2565406492 Pgn_Nack_E8FF1C "2545";
BA_ "SPN" SG_ 2565406492 Pgn_Ack_E8FF1C 2543;
BA_ "CI_SigName" SG_ 2565406492 Pgn_Ack_E8FF1C "Parameter Group Number (ACK)";
BA_ "CI_SigId" SG_ 2565406492 Pgn_Ack_E8FF1C 11198;
BA_ "CI_ParId" SG_ 2565406492 Pgn_Ack_E8FF1C "2543";
BA_ "SPN" SG_ 2565406492 AddrBusy 3293;
BA_ "CI_SigName" SG_ 2565406492 AddrBusy "Address Busy";
BA_ "CI_SigId" SG_ 2565406492 AddrBusy 11197;
BA_ "CI_ParId" SG_ 2565406492 AddrBusy "3293";
BA_ "SPN" SG_ 2565406492 AddrAccessDenied 3292;
BA_ "CI_SigName" SG_ 2565406492 AddrAccessDenied "Address Access Denied";
BA_ "CI_SigId" SG_ 2565406492 AddrAccessDenied 11196;
BA_ "CI_ParId" SG_ 2565406492 AddrAccessDenied "3292";
BA_ "SPN" SG_ 2565406492 AddrNack 3291;
BA_ "CI_SigName" SG_ 2565406492 AddrNack "Address Negative Acknowledgement";
BA_ "CI_SigId" SG_ 2565406492 AddrNack 11195;
BA_ "CI_ParId" SG_ 2565406492 AddrNack "3291";
BA_ "SPN" SG_ 2565406492 AddrAckd 3290;
BA_ "CI_SigName" SG_ 2565406492 AddrAckd "Address Acknowledged";
BA_ "CI_SigId" SG_ 2565406492 AddrAckd 11194;
BA_ "CI_ParId" SG_ 2565406492 AddrAckd "3290";
BA_ "SPN" SG_ 2565406492 CtrlByte_Ackm_E8FF1C 2541;
BA_ "CI_SigName" SG_ 2565406492 CtrlByte_Ackm_E8FF1C "Control Byte (ACKM)";
BA_ "CI_SigId" SG_ 2565406492 CtrlByte_Ackm_E8FF1C 11189;
BA_ "CI_ParId" SG_ 2565406492 CtrlByte_Ackm_E8FF1C "2541";
BA_ "SPN" SG_ 2565406493 Pgn_Busy_E8FF1D 2549;
BA_ "CI_SigName" SG_ 2565406493 Pgn_Busy_E8FF1D "Parameter Group Number (NACK_Busy)";
BA_ "CI_SigId" SG_ 2565406493 Pgn_Busy_E8FF1D 11215;
BA_ "CI_ParId" SG_ 2565406493 Pgn_Busy_E8FF1D "2549";
BA_ "SPN" SG_ 2565406493 Pgn_Ad_E8FF1D 2547;
BA_ "CI_SigName" SG_ 2565406493 Pgn_Ad_E8FF1D "Parameter Group Number (NACK_AD)";
BA_ "CI_SigId" SG_ 2565406493 Pgn_Ad_E8FF1D 11214;
BA_ "CI_ParId" SG_ 2565406493 Pgn_Ad_E8FF1D "2547";
BA_ "SPN" SG_ 2565406493 Pgn_Nack_E8FF1D 2545;
BA_ "CI_SigName" SG_ 2565406493 Pgn_Nack_E8FF1D "Parameter Group Number (NACK)";
BA_ "CI_SigId" SG_ 2565406493 Pgn_Nack_E8FF1D 11213;
BA_ "CI_ParId" SG_ 2565406493 Pgn_Nack_E8FF1D "2545";
BA_ "SPN" SG_ 2565406493 Pgn_Ack_E8FF1D 2543;
BA_ "CI_SigName" SG_ 2565406493 Pgn_Ack_E8FF1D "Parameter Group Number (ACK)";
BA_ "CI_SigId" SG_ 2565406493 Pgn_Ack_E8FF1D 11212;
BA_ "CI_ParId" SG_ 2565406493 Pgn_Ack_E8FF1D "2543";
BA_ "SPN" SG_ 2565406493 AddrBusy_E8FF1D 3293;
BA_ "CI_SigName" SG_ 2565406493 AddrBusy_E8FF1D "Address Busy";
BA_ "CI_SigId" SG_ 2565406493 AddrBusy_E8FF1D 11211;
BA_ "CI_ParId" SG_ 2565406493 AddrBusy_E8FF1D "3293";
BA_ "SPN" SG_ 2565406493 AddrAccessDenied_E8FF1D 3292;
BA_ "CI_SigName" SG_ 2565406493 AddrAccessDenied_E8FF1D "Address Access Denied";
BA_ "CI_SigId" SG_ 2565406493 AddrAccessDenied_E8FF1D 11210;
BA_ "CI_ParId" SG_ 2565406493 AddrAccessDenied_E8FF1D "3292";
BA_ "SPN" SG_ 2565406493 AddrNack_E8FF1D 3291;
BA_ "CI_SigName" SG_ 2565406493 AddrNack_E8FF1D "Address Negative Acknowledgement";
BA_ "CI_SigId" SG_ 2565406493 AddrNack_E8FF1D 11209;
BA_ "CI_ParId" SG_ 2565406493 AddrNack_E8FF1D "3291";
BA_ "SPN" SG_ 2565406493 AddrAckd_E8FF1D 3290;
BA_ "CI_SigName" SG_ 2565406493 AddrAckd_E8FF1D "Address Acknowledged";
BA_ "CI_SigId" SG_ 2565406493 AddrAckd_E8FF1D 11208;
BA_ "CI_ParId" SG_ 2565406493 AddrAckd_E8FF1D "3290";
BA_ "SPN" SG_ 2565406493 CtrlByte_Ackm_E8FF1D 2541;
BA_ "CI_SigName" SG_ 2565406493 CtrlByte_Ackm_E8FF1D "Control Byte (ACKM)";
BA_ "CI_SigId" SG_ 2565406493 CtrlByte_Ackm_E8FF1D 11203;
BA_ "CI_ParId" SG_ 2565406493 CtrlByte_Ackm_E8FF1D "2541";
BA_ "SPN" SG_ 2565406503 Pgn_Busy_E8FF27 2549;
BA_ "CI_SigName" SG_ 2565406503 Pgn_Busy_E8FF27 "Parameter Group Number (NACK_Busy)";
BA_ "CI_SigId" SG_ 2565406503 Pgn_Busy_E8FF27 11229;
BA_ "CI_ParId" SG_ 2565406503 Pgn_Busy_E8FF27 "2549";
BA_ "SPN" SG_ 2565406503 Pgn_Ad_E8FF27 2547;
BA_ "CI_SigName" SG_ 2565406503 Pgn_Ad_E8FF27 "Parameter Group Number (NACK_AD)";
BA_ "CI_SigId" SG_ 2565406503 Pgn_Ad_E8FF27 11228;
BA_ "CI_ParId" SG_ 2565406503 Pgn_Ad_E8FF27 "2547";
BA_ "SPN" SG_ 2565406503 Pgn_Nack_E8FF27 2545;
BA_ "CI_SigName" SG_ 2565406503 Pgn_Nack_E8FF27 "Parameter Group Number (NACK)";
BA_ "CI_SigId" SG_ 2565406503 Pgn_Nack_E8FF27 11227;
BA_ "CI_ParId" SG_ 2565406503 Pgn_Nack_E8FF27 "2545";
BA_ "SPN" SG_ 2565406503 Pgn_Ack_E8FF27 2543;
BA_ "CI_SigName" SG_ 2565406503 Pgn_Ack_E8FF27 "Parameter Group Number (ACK)";
BA_ "CI_SigId" SG_ 2565406503 Pgn_Ack_E8FF27 11226;
BA_ "CI_ParId" SG_ 2565406503 Pgn_Ack_E8FF27 "2543";
BA_ "SPN" SG_ 2565406503 CtrlByte_Ackm_E8FF27 2541;
BA_ "CI_SigName" SG_ 2565406503 CtrlByte_Ackm_E8FF27 "Control Byte (ACKM)";
BA_ "CI_SigId" SG_ 2565406503 CtrlByte_Ackm_E8FF27 11217;
BA_ "CI_ParId" SG_ 2565406503 CtrlByte_Ackm_E8FF27 "2541";
BA_ "SPN" SG_ 2565406515 Pgn_Busy_E8FF33 2549;
BA_ "CI_SigName" SG_ 2565406515 Pgn_Busy_E8FF33 "Parameter Group Number (NACK_Busy)";
BA_ "CI_SigId" SG_ 2565406515 Pgn_Busy_E8FF33 13501;
BA_ "CI_ParId" SG_ 2565406515 Pgn_Busy_E8FF33 "2549";
BA_ "SPN" SG_ 2565406515 Pgn_Ad_E8FF33 2547;
BA_ "CI_SigName" SG_ 2565406515 Pgn_Ad_E8FF33 "Parameter Group Number (NACK_AD)";
BA_ "CI_SigId" SG_ 2565406515 Pgn_Ad_E8FF33 13500;
BA_ "CI_ParId" SG_ 2565406515 Pgn_Ad_E8FF33 "2547";
BA_ "SPN" SG_ 2565406515 Pgn_Nack_E8FF33 2545;
BA_ "CI_SigName" SG_ 2565406515 Pgn_Nack_E8FF33 "Parameter Group Number (NACK)";
BA_ "CI_SigId" SG_ 2565406515 Pgn_Nack_E8FF33 13499;
BA_ "CI_ParId" SG_ 2565406515 Pgn_Nack_E8FF33 "2545";
BA_ "SPN" SG_ 2565406515 Pgn_Ack_E8FF33 2543;
BA_ "CI_SigName" SG_ 2565406515 Pgn_Ack_E8FF33 "Parameter Group Number (ACK)";
BA_ "CI_SigId" SG_ 2565406515 Pgn_Ack_E8FF33 13498;
BA_ "CI_ParId" SG_ 2565406515 Pgn_Ack_E8FF33 "2543";
BA_ "SPN" SG_ 2565406515 CtrlByte_Ackm_E8FF33 2541;
BA_ "CI_SigName" SG_ 2565406515 CtrlByte_Ackm_E8FF33 "Control Byte (ACKM)";
BA_ "CI_SigId" SG_ 2565406515 CtrlByte_Ackm_E8FF33 13489;
BA_ "CI_ParId" SG_ 2565406515 CtrlByte_Ackm_E8FF33 "2541";
BA_ "SPN" SG_ 2565406520 Pgn_Busy_E8FF38 2549;
BA_ "CI_SigName" SG_ 2565406520 Pgn_Busy_E8FF38 "Parameter Group Number (NACK_Busy)";
BA_ "CI_SigId" SG_ 2565406520 Pgn_Busy_E8FF38 11339;
BA_ "CI_ParId" SG_ 2565406520 Pgn_Busy_E8FF38 "2549";
BA_ "SPN" SG_ 2565406520 Pgn_Ad_E8FF38 2547;
BA_ "CI_SigName" SG_ 2565406520 Pgn_Ad_E8FF38 "Parameter Group Number (NACK_AD)";
BA_ "CI_SigId" SG_ 2565406520 Pgn_Ad_E8FF38 11338;
BA_ "CI_ParId" SG_ 2565406520 Pgn_Ad_E8FF38 "2547";
BA_ "SPN" SG_ 2565406520 Pgn_Nack_E8FF38 2545;
BA_ "CI_SigName" SG_ 2565406520 Pgn_Nack_E8FF38 "Parameter Group Number (NACK)";
BA_ "CI_SigId" SG_ 2565406520 Pgn_Nack_E8FF38 11337;
BA_ "CI_ParId" SG_ 2565406520 Pgn_Nack_E8FF38 "2545";
BA_ "SPN" SG_ 2565406520 Pgn_Ack_E8FF38 2543;
BA_ "CI_SigName" SG_ 2565406520 Pgn_Ack_E8FF38 "Parameter Group Number (ACK)";
BA_ "CI_SigId" SG_ 2565406520 Pgn_Ack_E8FF38 11336;
BA_ "CI_ParId" SG_ 2565406520 Pgn_Ack_E8FF38 "2543";
BA_ "SPN" SG_ 2565406520 CtrlByte_Ackm_E8FF38 2541;
BA_ "CI_SigName" SG_ 2565406520 CtrlByte_Ackm_E8FF38 "Control Byte (ACKM)";
BA_ "CI_SigId" SG_ 2565406520 CtrlByte_Ackm_E8FF38 11327;
BA_ "CI_ParId" SG_ 2565406520 CtrlByte_Ackm_E8FF38 "2541";
BA_ "SPN" SG_ 2565406590 Pgn_Busy_E8FF7E 2549;
BA_ "CI_SigName" SG_ 2565406590 Pgn_Busy_E8FF7E "Parameter Group Number (NACK_Busy)";
BA_ "CI_SigId" SG_ 2565406590 Pgn_Busy_E8FF7E 11271;
BA_ "CI_ParId" SG_ 2565406590 Pgn_Busy_E8FF7E "2549";
BA_ "SPN" SG_ 2565406590 Pgn_Ad_E8FF7E 2547;
BA_ "CI_SigName" SG_ 2565406590 Pgn_Ad_E8FF7E "Parameter Group Number (NACK_AD)";
BA_ "CI_SigId" SG_ 2565406590 Pgn_Ad_E8FF7E 11270;
BA_ "CI_ParId" SG_ 2565406590 Pgn_Ad_E8FF7E "2547";
BA_ "SPN" SG_ 2565406590 Pgn_Nack_E8FF7E 2545;
BA_ "CI_SigName" SG_ 2565406590 Pgn_Nack_E8FF7E "Parameter Group Number (NACK)";
BA_ "CI_SigId" SG_ 2565406590 Pgn_Nack_E8FF7E 11269;
BA_ "CI_ParId" SG_ 2565406590 Pgn_Nack_E8FF7E "2545";
BA_ "SPN" SG_ 2565406590 Pgn_Ack_E8FF7E 2543;
BA_ "CI_SigName" SG_ 2565406590 Pgn_Ack_E8FF7E "Parameter Group Number (ACK)";
BA_ "CI_SigId" SG_ 2565406590 Pgn_Ack_E8FF7E 11268;
BA_ "CI_ParId" SG_ 2565406590 Pgn_Ack_E8FF7E "2543";
BA_ "SPN" SG_ 2565406590 CtrlByte_Ackm_E8FF7E 2541;
BA_ "CI_SigName" SG_ 2565406590 CtrlByte_Ackm_E8FF7E "Control Byte (ACKM)";
BA_ "CI_SigId" SG_ 2565406590 CtrlByte_Ackm_E8FF7E 11259;
BA_ "CI_ParId" SG_ 2565406590 CtrlByte_Ackm_E8FF7E "2541";
BA_ "SPN" SG_ 2565406622 Pgn_Busy_E8FF9E 2549;
BA_ "CI_SigName" SG_ 2565406622 Pgn_Busy_E8FF9E "Parameter Group Number (NACK_Busy)";
BA_ "CI_SigId" SG_ 2565406622 Pgn_Busy_E8FF9E 17296;
BA_ "CI_ParId" SG_ 2565406622 Pgn_Busy_E8FF9E "2549";
BA_ "SPN" SG_ 2565406622 Pgn_Ad_E8FF9E 2547;
BA_ "CI_SigName" SG_ 2565406622 Pgn_Ad_E8FF9E "Parameter Group Number (NACK_AD)";
BA_ "CI_SigId" SG_ 2565406622 Pgn_Ad_E8FF9E 17295;
BA_ "CI_ParId" SG_ 2565406622 Pgn_Ad_E8FF9E "2547";
BA_ "SPN" SG_ 2565406622 Pgn_Nack_E8FF9E 2545;
BA_ "CI_SigName" SG_ 2565406622 Pgn_Nack_E8FF9E "Parameter Group Number (NACK)";
BA_ "CI_SigId" SG_ 2565406622 Pgn_Nack_E8FF9E 17294;
BA_ "CI_ParId" SG_ 2565406622 Pgn_Nack_E8FF9E "2545";
BA_ "SPN" SG_ 2565406622 Pgn_Ack_E8FF9E 2543;
BA_ "CI_SigName" SG_ 2565406622 Pgn_Ack_E8FF9E "Parameter Group Number (ACK)";
BA_ "CI_SigId" SG_ 2565406622 Pgn_Ack_E8FF9E 17293;
BA_ "CI_ParId" SG_ 2565406622 Pgn_Ack_E8FF9E "2543";
BA_ "SPN" SG_ 2565406622 CtrlByte_Ackm_E8FF9E 2541;
BA_ "CI_SigName" SG_ 2565406622 CtrlByte_Ackm_E8FF9E "Control Byte (ACKM)";
BA_ "CI_SigId" SG_ 2565406622 CtrlByte_Ackm_E8FF9E 17284;
BA_ "CI_ParId" SG_ 2565406622 CtrlByte_Ackm_E8FF9E "2541";
BA_ "SPN" SG_ 2565406624 Pgn_Busy_E8FFA0 2549;
BA_ "CI_SigName" SG_ 2565406624 Pgn_Busy_E8FFA0 "Parameter Group Number (NACK_Busy)";
BA_ "CI_SigId" SG_ 2565406624 Pgn_Busy_E8FFA0 11285;
BA_ "CI_ParId" SG_ 2565406624 Pgn_Busy_E8FFA0 "2549";
BA_ "SPN" SG_ 2565406624 Pgn_Ad_E8FFA0 2547;
BA_ "CI_SigName" SG_ 2565406624 Pgn_Ad_E8FFA0 "Parameter Group Number (NACK_AD)";
BA_ "CI_SigId" SG_ 2565406624 Pgn_Ad_E8FFA0 11284;
BA_ "CI_ParId" SG_ 2565406624 Pgn_Ad_E8FFA0 "2547";
BA_ "SPN" SG_ 2565406624 Pgn_Nack_E8FFA0 2545;
BA_ "CI_SigName" SG_ 2565406624 Pgn_Nack_E8FFA0 "Parameter Group Number (NACK)";
BA_ "CI_SigId" SG_ 2565406624 Pgn_Nack_E8FFA0 11283;
BA_ "CI_ParId" SG_ 2565406624 Pgn_Nack_E8FFA0 "2545";
BA_ "SPN" SG_ 2565406624 Pgn_Ack_E8FFA0 2543;
BA_ "CI_SigName" SG_ 2565406624 Pgn_Ack_E8FFA0 "Parameter Group Number (ACK)";
BA_ "CI_SigId" SG_ 2565406624 Pgn_Ack_E8FFA0 11282;
BA_ "CI_ParId" SG_ 2565406624 Pgn_Ack_E8FFA0 "2543";
BA_ "SPN" SG_ 2565406624 CtrlByte_Ackm_E8FFA0 2541;
BA_ "CI_SigName" SG_ 2565406624 CtrlByte_Ackm_E8FFA0 "Control Byte (ACKM)";
BA_ "CI_SigId" SG_ 2565406624 CtrlByte_Ackm_E8FFA0 11273;
BA_ "CI_ParId" SG_ 2565406624 CtrlByte_Ackm_E8FFA0 "2541";
BA_ "SigType" SG_ 2364551072 TimeToCollWithRelvObj 1;
BA_ "SPN" SG_ 2364551072 TimeToCollWithRelvObj 5680;
BA_ "GenSigTimeoutTime_SGW" SG_ 2364551072 TimeToCollWithRelvObj 500;
BA_ "GenSigTimeoutTime_PCM" SG_ 2364551072 TimeToCollWithRelvObj 500;
BA_ "GenSigTimeoutTime_IC_MulticS" SG_ 2364551072 TimeToCollWithRelvObj 500;
BA_ "GenSigSendType" SG_ 2364551072 TimeToCollWithRelvObj 3;
BA_ "CI_SigName" SG_ 2364551072 TimeToCollWithRelvObj "Time to collision with relevant object";
BA_ "CI_SigId" SG_ 2364551072 TimeToCollWithRelvObj 368;
BA_ "CI_ParId" SG_ 2364551072 TimeToCollWithRelvObj "5680";
BA_ "SPN" SG_ 2364551072 AebsSts 5676;
BA_ "GenSigTimeoutTime_VMU" SG_ 2364551072 AebsSts 500;
BA_ "GenSigTimeoutTime_VCM" SG_ 2364551072 AebsSts 500;
BA_ "GenSigTimeoutTime_SGW" SG_ 2364551072 AebsSts 500;
BA_ "GenSigTimeoutTime_PCM" SG_ 2364551072 AebsSts 500;
BA_ "GenSigTimeoutTime_IC_MulticS" SG_ 2364551072 AebsSts 500;
BA_ "GenSigTimeoutTime_BSM_EBS" SG_ 2364551072 AebsSts 500;
BA_ "GenSigTimeoutTime_BCM_NBM" SG_ 2364551072 AebsSts 500;
BA_ "GenSigSendType" SG_ 2364551072 AebsSts 3;
BA_ "CI_SigName" SG_ 2364551072 AebsSts "Forward Collision Advanced Emergency Braking System State";
BA_ "CI_SigId" SG_ 2364551072 AebsSts 364;
BA_ "CI_ParId" SG_ 2364551072 AebsSts "5676";
BA_ "SigType" SG_ 2349572119 DrivActvDemForAebs 4;
BA_ "SPN" SG_ 2349572119 DrivActvDemForAebs 5681;
BA_ "GenSigTimeoutTime_SGW" SG_ 2349572119 DrivActvDemForAebs 1250;
BA_ "GenSigTimeoutTime_PCM" SG_ 2349572119 DrivActvDemForAebs 1250;
BA_ "GenSigTimeoutTime_ADCU" SG_ 2349572119 DrivActvDemForAebs 1250;
BA_ "GenSigSendType" SG_ 2349572119 DrivActvDemForAebs 3;
BA_ "CI_SigName" SG_ 2349572119 DrivActvDemForAebs "Driver activation demand for Advanced Emergency Braking System";
BA_ "CI_SigId" SG_ 2349572119 DrivActvDemForAebs 373;
BA_ "CI_ParId" SG_ 2349572119 DrivActvDemForAebs "5681";
BA_ "SigType" SG_ 2566827553 AirComprSts 4;
BA_ "SPN" SG_ 2566827553 AirComprSts 1351;
BA_ "GenSigTimeoutTime_VCM" SG_ 2566827553 AirComprSts 5000;
BA_ "GenSigTimeoutTime_SGW" SG_ 2566827553 AirComprSts 5000;
BA_ "GenSigTimeoutTime_PCM" SG_ 2566827553 AirComprSts 5000;
BA_ "CI_SigName" SG_ 2566827553 AirComprSts "Air Compressor Status";
BA_ "CI_SigId" SG_ 2566827553 AirComprSts 2604;
BA_ "CI_ParId" SG_ 2566827553 AirComprSts "1351";
BA_ "SigType" SG_ 2566827553 AirSuspSupplyPrs1 1;
BA_ "SPN" SG_ 2566827553 AirSuspSupplyPrs1 1090;
BA_ "GenSigTimeoutTime_VCM" SG_ 2566827553 AirSuspSupplyPrs1 5000;
BA_ "GenSigTimeoutTime_SGW" SG_ 2566827553 AirSuspSupplyPrs1 5000;
BA_ "GenSigTimeoutTime_PCM" SG_ 2566827553 AirSuspSupplyPrs1 5000;
BA_ "GenSigTimeoutTime_BSM_EBS" SG_ 2566827553 AirSuspSupplyPrs1 5000;
BA_ "CI_SigName" SG_ 2566827553 AirSuspSupplyPrs1 "Air Suspension Supply Pressure 1";
BA_ "CI_SigId" SG_ 2566827553 AirSuspSupplyPrs1 2603;
BA_ "CI_ParId" SG_ 2566827553 AirSuspSupplyPrs1 "1090";
BA_ "SigType" SG_ 2566827553 ServBrkCirc2AirPrs 1;
BA_ "SPN" SG_ 2566827553 ServBrkCirc2AirPrs 1088;
BA_ "GenSigTimeoutTime_VCM" SG_ 2566827553 ServBrkCirc2AirPrs 5000;
BA_ "GenSigTimeoutTime_SGW" SG_ 2566827553 ServBrkCirc2AirPrs 5000;
BA_ "GenSigTimeoutTime_PCM" SG_ 2566827553 ServBrkCirc2AirPrs 5000;
BA_ "GenSigTimeoutTime_MPPxPTFE2" SG_ 2566827553 ServBrkCirc2AirPrs 5000;
BA_ "GenSigTimeoutTime_IC_MulticS" SG_ 2566827553 ServBrkCirc2AirPrs 5000;
BA_ "GenSigTimeoutTime_FMS_FMS5" SG_ 2566827553 ServBrkCirc2AirPrs 5000;
BA_ "GenSigTimeoutTime_FMS_FMS4" SG_ 2566827553 ServBrkCirc2AirPrs 5000;
BA_ "GenSigTimeoutTime_BSM_EBS" SG_ 2566827553 ServBrkCirc2AirPrs 5000;
BA_ "CI_SigName" SG_ 2566827553 ServBrkCirc2AirPrs "Service Brake Circuit 2 Air Pressure";
BA_ "CI_SigId" SG_ 2566827553 ServBrkCirc2AirPrs 2601;
BA_ "CI_ParId" SG_ 2566827553 ServBrkCirc2AirPrs "1088";
BA_ "SigType" SG_ 2566827553 ServBrkCirc1AirPrs 1;
BA_ "SPN" SG_ 2566827553 ServBrkCirc1AirPrs 1087;
BA_ "GenSigTimeoutTime_VCM" SG_ 2566827553 ServBrkCirc1AirPrs 5000;
BA_ "GenSigTimeoutTime_SGW" SG_ 2566827553 ServBrkCirc1AirPrs 5000;
BA_ "GenSigTimeoutTime_PCM" SG_ 2566827553 ServBrkCirc1AirPrs 5000;
BA_ "GenSigTimeoutTime_MPPxPTFE2" SG_ 2566827553 ServBrkCirc1AirPrs 5000;
BA_ "GenSigTimeoutTime_IC_MulticS" SG_ 2566827553 ServBrkCirc1AirPrs 5000;
BA_ "GenSigTimeoutTime_FMS_FMS5" SG_ 2566827553 ServBrkCirc1AirPrs 5000;
BA_ "GenSigTimeoutTime_FMS_FMS4" SG_ 2566827553 ServBrkCirc1AirPrs 5000;
BA_ "GenSigTimeoutTime_BSM_EBS" SG_ 2566827553 ServBrkCirc1AirPrs 5000;
BA_ "CI_SigName" SG_ 2566827553 ServBrkCirc1AirPrs "Service Brake Circuit 1 Air Pressure";
BA_ "CI_SigId" SG_ 2566827553 ServBrkCirc1AirPrs 2600;
BA_ "CI_ParId" SG_ 2566827553 ServBrkCirc1AirPrs "1087";
BA_ "SigType" SG_ 2566827553 ParkAnd_OrTrailAirPrs 1;
BA_ "SPN" SG_ 2566827553 ParkAnd_OrTrailAirPrs 1086;
BA_ "GenSigTimeoutTime_VCM" SG_ 2566827553 ParkAnd_OrTrailAirPrs 5000;
BA_ "GenSigTimeoutTime_SGW" SG_ 2566827553 ParkAnd_OrTrailAirPrs 5000;
BA_ "GenSigTimeoutTime_PCM" SG_ 2566827553 ParkAnd_OrTrailAirPrs 5000;
BA_ "GenSigTimeoutTime_IC_MulticS" SG_ 2566827553 ParkAnd_OrTrailAirPrs 5000;
BA_ "GenSigTimeoutTime_BSM_EBS" SG_ 2566827553 ParkAnd_OrTrailAirPrs 5000;
BA_ "CI_SigName" SG_ 2566827553 ParkAnd_OrTrailAirPrs "Parking and/or Trailer Air Pressure";
BA_ "CI_SigId" SG_ 2566827553 ParkAnd_OrTrailAirPrs 2599;
BA_ "CI_ParId" SG_ 2566827553 ParkAnd_OrTrailAirPrs "1086";
BA_ "GenSigTimeoutTime_SGW2" SG_ 2566620766 Data7 1000;
BA_ "GenSigTimeoutTime_SGW" SG_ 2566620766 Data7 1000;
BA_ "GenSigTimeoutTime_PCM" SG_ 2566620766 Data7 1000;
BA_ "GenSigTimeoutTime_IC_MulticS" SG_ 2566620766 Data7 1000;
BA_ "GenSigTimeoutTime_BCM_NBM" SG_ 2566620766 Data7 1000;
BA_ "CI_SigName" SG_ 2566620766 Data7 "Data7";
BA_ "CI_SigId" SG_ 2566620766 Data7 13531;
BA_ "CI_ParId" SG_ 2566620766 Data7 "IB661";
BA_ "GenSigTimeoutTime_SGW2" SG_ 2566620766 Data6 1000;
BA_ "GenSigTimeoutTime_SGW" SG_ 2566620766 Data6 1000;
BA_ "GenSigTimeoutTime_PCM" SG_ 2566620766 Data6 1000;
BA_ "GenSigTimeoutTime_IC_MulticS" SG_ 2566620766 Data6 1000;
BA_ "GenSigTimeoutTime_BCM_NBM" SG_ 2566620766 Data6 1000;
BA_ "CI_SigName" SG_ 2566620766 Data6 "Data6";
BA_ "CI_SigId" SG_ 2566620766 Data6 13530;
BA_ "CI_ParId" SG_ 2566620766 Data6 "IB660";
BA_ "GenSigTimeoutTime_SGW2" SG_ 2566620766 Data4 1000;
BA_ "GenSigTimeoutTime_SGW" SG_ 2566620766 Data4 1000;
BA_ "GenSigTimeoutTime_PCM" SG_ 2566620766 Data4 1000;
BA_ "GenSigTimeoutTime_IC_MulticS" SG_ 2566620766 Data4 1000;
BA_ "GenSigTimeoutTime_BCM_NBM" SG_ 2566620766 Data4 1000;
BA_ "CI_SigName" SG_ 2566620766 Data4 "Data4";
BA_ "CI_SigId" SG_ 2566620766 Data4 13529;
BA_ "CI_ParId" SG_ 2566620766 Data4 "IB659";
BA_ "GenSigTimeoutTime_SGW2" SG_ 2566620766 CAID2EngStartRollingSit 1000;
BA_ "GenSigTimeoutTime_SGW" SG_ 2566620766 CAID2EngStartRollingSit 1000;
BA_ "GenSigTimeoutTime_PCM" SG_ 2566620766 CAID2EngStartRollingSit 1000;
BA_ "GenSigTimeoutTime_IC_MulticS" SG_ 2566620766 CAID2EngStartRollingSit 1000;
BA_ "GenSigTimeoutTime_BCM_NBM" SG_ 2566620766 CAID2EngStartRollingSit 1000;
BA_ "CI_SigName" SG_ 2566620766 CAID2EngStartRollingSit "CAID2 Engine Start / Rolling situation";
BA_ "CI_SigId" SG_ 2566620766 CAID2EngStartRollingSit 13528;
BA_ "CI_ParId" SG_ 2566620766 CAID2EngStartRollingSit "IB658";
BA_ "GenSigTimeoutTime_SGW2" SG_ 2566620766 CAID2Sts 1000;
BA_ "GenSigTimeoutTime_SGW" SG_ 2566620766 CAID2Sts 1000;
BA_ "GenSigTimeoutTime_PCM" SG_ 2566620766 CAID2Sts 1000;
BA_ "GenSigTimeoutTime_IC_MulticS" SG_ 2566620766 CAID2Sts 1000;
BA_ "GenSigTimeoutTime_BCM_NBM" SG_ 2566620766 CAID2Sts 1000;
BA_ "CI_SigName" SG_ 2566620766 CAID2Sts "CAID2 Status";
BA_ "CI_SigId" SG_ 2566620766 CAID2Sts 13527;
BA_ "CI_ParId" SG_ 2566620766 CAID2Sts "IB657";
BA_ "SigType" SG_ 2566845696 EngIn1AirTemp 1;
BA_ "SPN" SG_ 2566845696 EngIn1AirTemp 172;
BA_ "GenSigTimeoutTime_VCM" SG_ 2566845696 EngIn1AirTemp 5000;
BA_ "GenSigTimeoutTime_SGW" SG_ 2566845696 EngIn1AirTemp 5000;
BA_ "GenSigTimeoutTime_PCM" SG_ 2566845696 EngIn1AirTemp 5000;
BA_ "GenSigTimeoutTime_FMS_FMS5" SG_ 2566845696 EngIn1AirTemp 5000;
BA_ "GenSigTimeoutTime_FMS_FMS4" SG_ 2566845696 EngIn1AirTemp 5000;
BA_ "GenSigStartValue" SG_ 2566845696 EngIn1AirTemp 40;
BA_ "CI_SigName" SG_ 2566845696 EngIn1AirTemp "Engine Intake 1 Air Temperature";
BA_ "CI_SigId" SG_ 2566845696 EngIn1AirTemp 2028;
BA_ "CI_ParId" SG_ 2566845696 EngIn1AirTemp "172";
BA_ "SigType" SG_ 2566845696 AmbAirTemp 1;
BA_ "SPN" SG_ 2566845696 AmbAirTemp 171;
BA_ "GenSigTimeoutTime_VCM" SG_ 2566845696 AmbAirTemp 5000;
BA_ "GenSigTimeoutTime_TASM_ETS" SG_ 2566845696 AmbAirTemp 5000;
BA_ "GenSigTimeoutTime_SGW" SG_ 2566845696 AmbAirTemp 5000;
BA_ "GenSigTimeoutTime_PCM" SG_ 2566845696 AmbAirTemp 5000;
BA_ "GenSigTimeoutTime_ETC_Ecolife2" SG_ 2566845696 AmbAirTemp 5000;
BA_ "GenSigTimeoutTime_BSM_EBS" SG_ 2566845696 AmbAirTemp 5000;
BA_ "GenSigStartValue" SG_ 2566845696 AmbAirTemp 8736;
BA_ "CI_SigName" SG_ 2566845696 AmbAirTemp "Ambient Air Temperature";
BA_ "CI_SigId" SG_ 2566845696 AmbAirTemp 2027;
BA_ "CI_ParId" SG_ 2566845696 AmbAirTemp "171";
BA_ "SigType" SG_ 2566845696 BaromPrs 1;
BA_ "SPN" SG_ 2566845696 BaromPrs 108;
BA_ "GenSigTimeoutTime_VCM" SG_ 2566845696 BaromPrs 5000;
BA_ "GenSigTimeoutTime_TPMS" SG_ 2566845696 BaromPrs 5000;
BA_ "GenSigTimeoutTime_SGW" SG_ 2566845696 BaromPrs 5000;
BA_ "GenSigTimeoutTime_PCM" SG_ 2566845696 BaromPrs 5000;
BA_ "GenSigTimeoutTime_MPPxPTFE2" SG_ 2566845696 BaromPrs 5000;
BA_ "GenSigTimeoutTime_FMS_FMS5" SG_ 2566845696 BaromPrs 5000;
BA_ "GenSigTimeoutTime_FMS_FMS4" SG_ 2566845696 BaromPrs 5000;
BA_ "CI_SigName" SG_ 2566845696 BaromPrs "Barometric Pressure";
BA_ "CI_SigId" SG_ 2566845696 BaromPrs 2025;
BA_ "CI_ParId" SG_ 2566845696 BaromPrs "108";
BA_ "SigType" SG_ 2566845719 AmbAirTemp_FEF517 1;
BA_ "SPN" SG_ 2566845719 AmbAirTemp_FEF517 171;
BA_ "GenSigTimeoutTime_VMU" SG_ 2566845719 AmbAirTemp_FEF517 5000;
BA_ "GenSigTimeoutTime_VCU" SG_ 2566845719 AmbAirTemp_FEF517 5000;
BA_ "GenSigTimeoutTime_SGW" SG_ 2566845719 AmbAirTemp_FEF517 5000;
BA_ "GenSigTimeoutTime_PCM" SG_ 2566845719 AmbAirTemp_FEF517 5000;
BA_ "GenSigTimeoutTime_IC_MulticS" SG_ 2566845719 AmbAirTemp_FEF517 5000;
BA_ "GenSigTimeoutTime_BSM_EBS" SG_ 2566845719 AmbAirTemp_FEF517 5000;
BA_ "GenSigTimeoutTime_BCM_NBM" SG_ 2566845719 AmbAirTemp_FEF517 5000;
BA_ "GenSigTimeoutTime_ACM_CANAIR" SG_ 2566845719 AmbAirTemp_FEF517 5000;
BA_ "GenSigStartValue" SG_ 2566845719 AmbAirTemp_FEF517 8736;
BA_ "CI_SigName" SG_ 2566845719 AmbAirTemp_FEF517 "Ambient Air Temperature";
BA_ "CI_SigId" SG_ 2566845719 AmbAirTemp_FEF517 2033;
BA_ "CI_ParId" SG_ 2566845719 AmbAirTemp_FEF517 "171";
BA_ "SigType" SG_ 2566845719 CabInternTemp 1;
BA_ "SPN" SG_ 2566845719 CabInternTemp 170;
BA_ "GenSigTimeoutTime_SGW" SG_ 2566845719 CabInternTemp 5000;
BA_ "GenSigTimeoutTime_PCM" SG_ 2566845719 CabInternTemp 5000;
BA_ "GenSigStartValue" SG_ 2566845719 CabInternTemp 8736;
BA_ "CI_SigName" SG_ 2566845719 CabInternTemp "Cab Interior Temperature";
BA_ "CI_SigId" SG_ 2566845719 CabInternTemp 2032;
BA_ "CI_ParId" SG_ 2566845719 CabInternTemp "170";
BA_ "SigType" SG_ 2565920602 Dc_AcAccsInv1Freq 1;
BA_ "SPN" SG_ 2565920602 Dc_AcAccsInv1Freq 8337;
BA_ "GenSigTimeoutTime_SGW" SG_ 2565920602 Dc_AcAccsInv1Freq 500;
BA_ "GenSigTimeoutTime_PCM" SG_ 2565920602 Dc_AcAccsInv1Freq 500;
BA_ "GenSigTimeoutTime_MPPxPTFE2" SG_ 2565920602 Dc_AcAccsInv1Freq 500;
BA_ "GenSigTimeoutTime_FMS_FMS4" SG_ 2565920602 Dc_AcAccsInv1Freq 500;
BA_ "GenSigTimeoutTime_BCM_NBM" SG_ 2565920602 Dc_AcAccsInv1Freq 500;
BA_ "CI_SigName" SG_ 2565920602 Dc_AcAccsInv1Freq "DC/AC Accessory Inverter 1 Frequency";
BA_ "CI_SigId" SG_ 2565920602 Dc_AcAccsInv1Freq 2059;
BA_ "CI_ParId" SG_ 2565920602 Dc_AcAccsInv1Freq "8337";
BA_ "SPN" SG_ 2565921626 Dc_AcAccsInv2OpSts 8354;
BA_ "GenSigTimeoutTime_SGW" SG_ 2565921626 Dc_AcAccsInv2OpSts 500;
BA_ "GenSigTimeoutTime_PCM" SG_ 2565921626 Dc_AcAccsInv2OpSts 500;
BA_ "GenSigTimeoutTime_MPPxPTFE2" SG_ 2565921626 Dc_AcAccsInv2OpSts 500;
BA_ "GenSigTimeoutTime_FMS_FMS4" SG_ 2565921626 Dc_AcAccsInv2OpSts 500;
BA_ "GenSigTimeoutTime_BCM_NBM" SG_ 2565921626 Dc_AcAccsInv2OpSts 500;
BA_ "GenSigTimeoutTime_ACM_CANAIR" SG_ 2565921626 Dc_AcAccsInv2OpSts 500;
BA_ "CI_SigName" SG_ 2565921626 Dc_AcAccsInv2OpSts "DC/AC Accessory Inverter 2 Operational Status";
BA_ "CI_SigId" SG_ 2565921626 Dc_AcAccsInv2OpSts 2078;
BA_ "CI_ParId" SG_ 2565921626 Dc_AcAccsInv2OpSts "8354";
BA_ "SigType" SG_ 2565921626 Dc_AcAccsInv2AcSidePwr 1;
BA_ "SPN" SG_ 2565921626 Dc_AcAccsInv2AcSidePwr 8353;
BA_ "GenSigTimeoutTime_TMU_HP_Fr" SG_ 2565921626 Dc_AcAccsInv2AcSidePwr 500;
BA_ "GenSigTimeoutTime_SGW" SG_ 2565921626 Dc_AcAccsInv2AcSidePwr 500;
BA_ "GenSigTimeoutTime_PCM" SG_ 2565921626 Dc_AcAccsInv2AcSidePwr 500;
BA_ "GenSigTimeoutTime_MPPxPTFE2" SG_ 2565921626 Dc_AcAccsInv2AcSidePwr 500;
BA_ "GenSigTimeoutTime_FMS_FMS4" SG_ 2565921626 Dc_AcAccsInv2AcSidePwr 500;
BA_ "GenSigTimeoutTime_ACM_CANAIR" SG_ 2565921626 Dc_AcAccsInv2AcSidePwr 500;
BA_ "CI_SigName" SG_ 2565921626 Dc_AcAccsInv2AcSidePwr "DC/AC Accessory Inverter 2 AC Side Power";
BA_ "CI_SigId" SG_ 2565921626 Dc_AcAccsInv2AcSidePwr 2077;
BA_ "CI_ParId" SG_ 2565921626 Dc_AcAccsInv2AcSidePwr "8353";
BA_ "SigType" SG_ 2565922650 Dc_AcAccsInv3LoadshedReq 4;
BA_ "SPN" SG_ 2565922650 Dc_AcAccsInv3LoadshedReq 8369;
BA_ "GenSigTimeoutTime_SGW" SG_ 2565922650 Dc_AcAccsInv3LoadshedReq 500;
BA_ "GenSigTimeoutTime_PCM" SG_ 2565922650 Dc_AcAccsInv3LoadshedReq 500;
BA_ "GenSigTimeoutTime_BCM_NBM" SG_ 2565922650 Dc_AcAccsInv3LoadshedReq 500;
BA_ "CI_SigName" SG_ 2565922650 Dc_AcAccsInv3LoadshedReq "DC/AC Accessory Inverter 3 Loadshed Request";
BA_ "CI_SigId" SG_ 2565922650 Dc_AcAccsInv3LoadshedReq 14815;
BA_ "CI_ParId" SG_ 2565922650 Dc_AcAccsInv3LoadshedReq "8369";
BA_ "SPN" SG_ 2565922650 Dc_AcAccsInv3OpSts 8368;
BA_ "GenSigTimeoutTime_SGW" SG_ 2565922650 Dc_AcAccsInv3OpSts 500;
BA_ "GenSigTimeoutTime_PCM" SG_ 2565922650 Dc_AcAccsInv3OpSts 500;
BA_ "GenSigTimeoutTime_BCM_NBM" SG_ 2565922650 Dc_AcAccsInv3OpSts 500;
BA_ "CI_SigName" SG_ 2565922650 Dc_AcAccsInv3OpSts "DC/AC Accessory Inverter 3 Operational Status";
BA_ "CI_SigId" SG_ 2565922650 Dc_AcAccsInv3OpSts 14814;
BA_ "CI_ParId" SG_ 2565922650 Dc_AcAccsInv3OpSts "8368";
BA_ "SigType" SG_ 2565922650 Dc_AcAccsInv3AcSidePwr 1;
BA_ "SPN" SG_ 2565922650 Dc_AcAccsInv3AcSidePwr 8367;
BA_ "GenSigTimeoutTime_TMU_HP_Rr" SG_ 2565922650 Dc_AcAccsInv3AcSidePwr 500;
BA_ "GenSigTimeoutTime_SGW" SG_ 2565922650 Dc_AcAccsInv3AcSidePwr 500;
BA_ "GenSigTimeoutTime_PCM" SG_ 2565922650 Dc_AcAccsInv3AcSidePwr 500;
BA_ "GenSigTimeoutTime_BCM_NBM" SG_ 2565922650 Dc_AcAccsInv3AcSidePwr 500;
BA_ "CI_SigName" SG_ 2565922650 Dc_AcAccsInv3AcSidePwr "DC/AC Accessory Inverter 3 AC Side Power";
BA_ "CI_SigId" SG_ 2565922650 Dc_AcAccsInv3AcSidePwr 14813;
BA_ "CI_ParId" SG_ 2565922650 Dc_AcAccsInv3AcSidePwr "8367";
BA_ "SigType" SG_ 2565922650 Dc_AcAccsInv3AcSideRmsV 1;
BA_ "SPN" SG_ 2565922650 Dc_AcAccsInv3AcSideRmsV 8366;
BA_ "GenSigTimeoutTime_SGW" SG_ 2565922650 Dc_AcAccsInv3AcSideRmsV 500;
BA_ "GenSigTimeoutTime_PCM" SG_ 2565922650 Dc_AcAccsInv3AcSideRmsV 500;
BA_ "GenSigTimeoutTime_BCM_NBM" SG_ 2565922650 Dc_AcAccsInv3AcSideRmsV 500;
BA_ "CI_SigName" SG_ 2565922650 Dc_AcAccsInv3AcSideRmsV "DC/AC Accessory Inverter 3 AC Side RMS Voltage";
BA_ "CI_SigId" SG_ 2565922650 Dc_AcAccsInv3AcSideRmsV 14812;
BA_ "CI_ParId" SG_ 2565922650 Dc_AcAccsInv3AcSideRmsV "8366";
BA_ "SigType" SG_ 2565922650 Dc_AcAccsInv3Freq 1;
BA_ "SPN" SG_ 2565922650 Dc_AcAccsInv3Freq 8365;
BA_ "GenSigTimeoutTime_TMU_HP_Rr" SG_ 2565922650 Dc_AcAccsInv3Freq 500;
BA_ "GenSigTimeoutTime_SGW" SG_ 2565922650 Dc_AcAccsInv3Freq 500;
BA_ "GenSigTimeoutTime_PCM" SG_ 2565922650 Dc_AcAccsInv3Freq 500;
BA_ "GenSigTimeoutTime_BCM_NBM" SG_ 2565922650 Dc_AcAccsInv3Freq 500;
BA_ "CI_SigName" SG_ 2565922650 Dc_AcAccsInv3Freq "DC/AC Accessory Inverter 3 Frequency";
BA_ "CI_SigId" SG_ 2565922650 Dc_AcAccsInv3Freq 14811;
BA_ "CI_ParId" SG_ 2565922650 Dc_AcAccsInv3Freq "8365";
BA_ "SigType" SG_ 2566837527 Altern3Sts 4;
BA_ "SPN" SG_ 2566837527 Altern3Sts 3355;
BA_ "GenSigTimeoutTime_SGW" SG_ 2566837527 Altern3Sts 5000;
BA_ "GenSigTimeoutTime_PCM" SG_ 2566837527 Altern3Sts 5000;
BA_ "GenSigTimeoutTime_FMS_FMS5" SG_ 2566837527 Altern3Sts 5000;
BA_ "GenSigTimeoutTime_FMS_FMS4" SG_ 2566837527 Altern3Sts 5000;
BA_ "CI_SigName" SG_ 2566837527 Altern3Sts "Alternator 3 Status";
BA_ "CI_SigId" SG_ 2566837527 Altern3Sts 2203;
BA_ "CI_ParId" SG_ 2566837527 Altern3Sts "3355";
BA_ "SigType" SG_ 2566837527 Altern2Sts 4;
BA_ "SPN" SG_ 2566837527 Altern2Sts 3354;
BA_ "GenSigTimeoutTime_SGW" SG_ 2566837527 Altern2Sts 5000;
BA_ "GenSigTimeoutTime_PCM" SG_ 2566837527 Altern2Sts 5000;
BA_ "GenSigTimeoutTime_FMS_FMS5" SG_ 2566837527 Altern2Sts 5000;
BA_ "GenSigTimeoutTime_FMS_FMS4" SG_ 2566837527 Altern2Sts 5000;
BA_ "CI_SigName" SG_ 2566837527 Altern2Sts "Alternator 2 Status";
BA_ "CI_SigId" SG_ 2566837527 Altern2Sts 2202;
BA_ "CI_ParId" SG_ 2566837527 Altern2Sts "3354";
BA_ "SigType" SG_ 2566837527 Altern1Sts 4;
BA_ "SPN" SG_ 2566837527 Altern1Sts 3353;
BA_ "GenSigTimeoutTime_SGW" SG_ 2566837527 Altern1Sts 5000;
BA_ "GenSigTimeoutTime_PCM" SG_ 2566837527 Altern1Sts 5000;
BA_ "GenSigTimeoutTime_FMS_FMS5" SG_ 2566837527 Altern1Sts 5000;
BA_ "GenSigTimeoutTime_FMS_FMS4" SG_ 2566837527 Altern1Sts 5000;
BA_ "CI_SigName" SG_ 2566837527 Altern1Sts "Alternator 1 Status";
BA_ "CI_SigId" SG_ 2566837527 Altern1Sts 2201;
BA_ "CI_ParId" SG_ 2566837527 Altern1Sts "3353";
BA_ "SPN" SG_ 2365479471 KneelInfo 1742;
BA_ "GenSigTimeoutTime_VCM" SG_ 2365479471 KneelInfo 500;
BA_ "GenSigTimeoutTime_SGW" SG_ 2365479471 KneelInfo 500;
BA_ "GenSigTimeoutTime_PCM" SG_ 2365479471 KneelInfo 500;
BA_ "GenSigTimeoutTime_BCM_NBM" SG_ 2365479471 KneelInfo 500;
BA_ "CI_SigName" SG_ 2365479471 KneelInfo "Kneeling Information";
BA_ "CI_SigId" SG_ 2365479471 KneelInfo 3023;
BA_ "CI_ParId" SG_ 2365479471 KneelInfo "1742";
BA_ "SPN" SG_ 2365479488 KneelInfo_E5A40 1742;
BA_ "GenSigTimeoutTime_SGW" SG_ 2365479488 KneelInfo_E5A40 500;
BA_ "GenSigTimeoutTime_PCM" SG_ 2365479488 KneelInfo_E5A40 500;
BA_ "GenSigTimeoutTime_BCM_NBM" SG_ 2365479488 KneelInfo_E5A40 500;
BA_ "CI_SigName" SG_ 2365479488 KneelInfo_E5A40 "Kneeling Information";
BA_ "CI_SigId" SG_ 2365479488 KneelInfo_E5A40 3049;
BA_ "CI_ParId" SG_ 2365479488 KneelInfo_E5A40 "1742";
BA_ "SigType" SG_ 2566805807 RelLevRaR 1;
BA_ "SPN" SG_ 2566805807 RelLevRaR 1723;
BA_ "GenSigTimeoutTime_SGW" SG_ 2566805807 RelLevRaR 500;
BA_ "GenSigTimeoutTime_PCM" SG_ 2566805807 RelLevRaR 500;
BA_ "GenSigTimeoutTime_BSM_EBS" SG_ 2566805807 RelLevRaR 500;
BA_ "GenSigStartValue" SG_ 2566805807 RelLevRaR 32000;
BA_ "CI_SigName" SG_ 2566805807 RelLevRaR "Relative Level Rear Axle Right";
BA_ "CI_SigId" SG_ 2566805807 RelLevRaR 3083;
BA_ "CI_ParId" SG_ 2566805807 RelLevRaR "1723";
BA_ "SigType" SG_ 2566805807 RelLevRaL 1;
BA_ "SPN" SG_ 2566805807 RelLevRaL 1724;
BA_ "GenSigTimeoutTime_SGW" SG_ 2566805807 RelLevRaL 500;
BA_ "GenSigTimeoutTime_PCM" SG_ 2566805807 RelLevRaL 500;
BA_ "GenSigTimeoutTime_BSM_EBS" SG_ 2566805807 RelLevRaL 500;
BA_ "GenSigStartValue" SG_ 2566805807 RelLevRaL 32000;
BA_ "CI_SigName" SG_ 2566805807 RelLevRaL "Relative Level Rear Axle Left";
BA_ "CI_SigId" SG_ 2566805807 RelLevRaL 3082;
BA_ "CI_ParId" SG_ 2566805807 RelLevRaL "1724";
BA_ "SigType" SG_ 2566805807 RelLevFaR 1;
BA_ "SPN" SG_ 2566805807 RelLevFaR 1722;
BA_ "GenSigTimeoutTime_SGW" SG_ 2566805807 RelLevFaR 500;
BA_ "GenSigTimeoutTime_PCM" SG_ 2566805807 RelLevFaR 500;
BA_ "GenSigTimeoutTime_BSM_EBS" SG_ 2566805807 RelLevFaR 500;
BA_ "GenSigStartValue" SG_ 2566805807 RelLevFaR 32000;
BA_ "CI_SigName" SG_ 2566805807 RelLevFaR "Relative Level Front Axle Right";
BA_ "CI_SigId" SG_ 2566805807 RelLevFaR 3081;
BA_ "CI_ParId" SG_ 2566805807 RelLevFaR "1722";
BA_ "SigType" SG_ 2566805807 RelLevFaL 1;
BA_ "SPN" SG_ 2566805807 RelLevFaL 1721;
BA_ "GenSigTimeoutTime_SGW" SG_ 2566805807 RelLevFaL 500;
BA_ "GenSigTimeoutTime_PCM" SG_ 2566805807 RelLevFaL 500;
BA_ "GenSigTimeoutTime_BSM_EBS" SG_ 2566805807 RelLevFaL 500;
BA_ "GenSigStartValue" SG_ 2566805807 RelLevFaL 32000;
BA_ "CI_SigName" SG_ 2566805807 RelLevFaL "Relative Level Front Axle Left";
BA_ "CI_SigId" SG_ 2566805807 RelLevFaL 3080;
BA_ "CI_ParId" SG_ 2566805807 RelLevFaL "1721";
BA_ "SigType" SG_ 2566805824 RelLevRaR_FE5940 1;
BA_ "SPN" SG_ 2566805824 RelLevRaR_FE5940 1723;
BA_ "GenSigTimeoutTime_SGW" SG_ 2566805824 RelLevRaR_FE5940 500;
BA_ "GenSigTimeoutTime_PCM" SG_ 2566805824 RelLevRaR_FE5940 500;
BA_ "GenSigStartValue" SG_ 2566805824 RelLevRaR_FE5940 32000;
BA_ "CI_SigName" SG_ 2566805824 RelLevRaR_FE5940 "Relative Level Rear Axle Right";
BA_ "CI_SigId" SG_ 2566805824 RelLevRaR_FE5940 3087;
BA_ "CI_ParId" SG_ 2566805824 RelLevRaR_FE5940 "1723";
BA_ "SigType" SG_ 2566805824 RelLevRaL_FE5940 1;
BA_ "SPN" SG_ 2566805824 RelLevRaL_FE5940 1724;
BA_ "GenSigTimeoutTime_SGW" SG_ 2566805824 RelLevRaL_FE5940 500;
BA_ "GenSigTimeoutTime_PCM" SG_ 2566805824 RelLevRaL_FE5940 500;
BA_ "GenSigStartValue" SG_ 2566805824 RelLevRaL_FE5940 32000;
BA_ "CI_SigName" SG_ 2566805824 RelLevRaL_FE5940 "Relative Level Rear Axle Left";
BA_ "CI_SigId" SG_ 2566805824 RelLevRaL_FE5940 3088;
BA_ "CI_ParId" SG_ 2566805824 RelLevRaL_FE5940 "1724";
BA_ "SigType" SG_ 2566805551 BellowPrsRaR 1;
BA_ "SPN" SG_ 2566805551 BellowPrsRaR 1728;
BA_ "GenSigTimeoutTime_SGW" SG_ 2566805551 BellowPrsRaR 500;
BA_ "GenSigTimeoutTime_PCM" SG_ 2566805551 BellowPrsRaR 500;
BA_ "GenSigTimeoutTime_MPPxPTFE2" SG_ 2566805551 BellowPrsRaR 500;
BA_ "GenSigTimeoutTime_FMS_FMS5" SG_ 2566805551 BellowPrsRaR 500;
BA_ "GenSigTimeoutTime_FMS_FMS4" SG_ 2566805551 BellowPrsRaR 500;
BA_ "GenSigTimeoutTime_BSM_EBS" SG_ 2566805551 BellowPrsRaR 500;
BA_ "CI_SigName" SG_ 2566805551 BellowPrsRaR "Bellow Pressure Rear Axle Right";
BA_ "CI_SigId" SG_ 2566805551 BellowPrsRaR 3093;
BA_ "CI_ParId" SG_ 2566805551 BellowPrsRaR "1728";
BA_ "SigType" SG_ 2566805551 BellowPrsRaL 1;
BA_ "SPN" SG_ 2566805551 BellowPrsRaL 1727;
BA_ "GenSigTimeoutTime_SGW" SG_ 2566805551 BellowPrsRaL 500;
BA_ "GenSigTimeoutTime_PCM" SG_ 2566805551 BellowPrsRaL 500;
BA_ "GenSigTimeoutTime_MPPxPTFE2" SG_ 2566805551 BellowPrsRaL 500;
BA_ "GenSigTimeoutTime_FMS_FMS5" SG_ 2566805551 BellowPrsRaL 500;
BA_ "GenSigTimeoutTime_FMS_FMS4" SG_ 2566805551 BellowPrsRaL 500;
BA_ "GenSigTimeoutTime_BSM_EBS" SG_ 2566805551 BellowPrsRaL 500;
BA_ "CI_SigName" SG_ 2566805551 BellowPrsRaL "Bellow Pressure Rear Axle Left";
BA_ "CI_SigId" SG_ 2566805551 BellowPrsRaL 3092;
BA_ "CI_ParId" SG_ 2566805551 BellowPrsRaL "1727";
BA_ "SigType" SG_ 2566805551 BellowPrsFaR 1;
BA_ "SPN" SG_ 2566805551 BellowPrsFaR 1726;
BA_ "GenSigTimeoutTime_SGW" SG_ 2566805551 BellowPrsFaR 500;
BA_ "GenSigTimeoutTime_PCM" SG_ 2566805551 BellowPrsFaR 500;
BA_ "GenSigTimeoutTime_MPPxPTFE2" SG_ 2566805551 BellowPrsFaR 500;
BA_ "GenSigTimeoutTime_FMS_FMS5" SG_ 2566805551 BellowPrsFaR 500;
BA_ "GenSigTimeoutTime_FMS_FMS4" SG_ 2566805551 BellowPrsFaR 500;
BA_ "GenSigTimeoutTime_BSM_EBS" SG_ 2566805551 BellowPrsFaR 500;
BA_ "CI_SigName" SG_ 2566805551 BellowPrsFaR "Bellow Pressure Front Axle Right";
BA_ "CI_SigId" SG_ 2566805551 BellowPrsFaR 3091;
BA_ "CI_ParId" SG_ 2566805551 BellowPrsFaR "1726";
BA_ "SigType" SG_ 2566805551 BellowPrsFaL 1;
BA_ "SPN" SG_ 2566805551 BellowPrsFaL 1725;
BA_ "GenSigTimeoutTime_SGW" SG_ 2566805551 BellowPrsFaL 500;
BA_ "GenSigTimeoutTime_PCM" SG_ 2566805551 BellowPrsFaL 500;
BA_ "GenSigTimeoutTime_MPPxPTFE2" SG_ 2566805551 BellowPrsFaL 500;
BA_ "GenSigTimeoutTime_FMS_FMS5" SG_ 2566805551 BellowPrsFaL 500;
BA_ "GenSigTimeoutTime_FMS_FMS4" SG_ 2566805551 BellowPrsFaL 500;
BA_ "GenSigTimeoutTime_BSM_EBS" SG_ 2566805551 BellowPrsFaL 500;
BA_ "CI_SigName" SG_ 2566805551 BellowPrsFaL "Bellow Pressure Front Axle Left";
BA_ "CI_SigId" SG_ 2566805551 BellowPrsFaL 3090;
BA_ "CI_ParId" SG_ 2566805551 BellowPrsFaL "1725";
BA_ "SigType" SG_ 2566805568 BellowPrsRaR_FE5840 1;
BA_ "SPN" SG_ 2566805568 BellowPrsRaR_FE5840 1728;
BA_ "GenSigTimeoutTime_SGW" SG_ 2566805568 BellowPrsRaR_FE5840 500;
BA_ "GenSigTimeoutTime_PCM" SG_ 2566805568 BellowPrsRaR_FE5840 500;
BA_ "CI_SigName" SG_ 2566805568 BellowPrsRaR_FE5840 "Bellow Pressure Rear Axle Right";
BA_ "CI_SigId" SG_ 2566805568 BellowPrsRaR_FE5840 3098;
BA_ "CI_ParId" SG_ 2566805568 BellowPrsRaR_FE5840 "1728";
BA_ "SigType" SG_ 2566805568 BellowPrsRaL_FE5840 1;
BA_ "SPN" SG_ 2566805568 BellowPrsRaL_FE5840 1727;
BA_ "GenSigTimeoutTime_SGW" SG_ 2566805568 BellowPrsRaL_FE5840 500;
BA_ "GenSigTimeoutTime_PCM" SG_ 2566805568 BellowPrsRaL_FE5840 500;
BA_ "CI_SigName" SG_ 2566805568 BellowPrsRaL_FE5840 "Bellow Pressure Rear Axle Left";
BA_ "CI_SigId" SG_ 2566805568 BellowPrsRaL_FE5840 3097;
BA_ "CI_ParId" SG_ 2566805568 BellowPrsRaL_FE5840 "1727";
BA_ "SigType" SG_ 2566763520 At1DpfInTemp 1;
BA_ "SPN" SG_ 2566763520 At1DpfInTemp 3242;
BA_ "GenSigTimeoutTime_SGW" SG_ 2566763520 At1DpfInTemp 2500;
BA_ "GenSigTimeoutTime_PCM" SG_ 2566763520 At1DpfInTemp 2500;
BA_ "GenSigStartValue" SG_ 2566763520 At1DpfInTemp 8736;
BA_ "CI_SigName" SG_ 2566763520 At1DpfInTemp "Aftertreatment 1 Diesel Particulate Filter Intake Temperature";
BA_ "CI_SigId" SG_ 2566763520 At1DpfInTemp 1228;
BA_ "CI_ParId" SG_ 2566763520 At1DpfInTemp "3242";
BA_ "SPN" SG_ 2566804992 AtScrOpInducSev 5246;
BA_ "GenSigTimeoutTime_VCM" SG_ 2566804992 AtScrOpInducSev 5000;
BA_ "GenSigTimeoutTime_SGW" SG_ 2566804992 AtScrOpInducSev 5000;
BA_ "GenSigTimeoutTime_PCM" SG_ 2566804992 AtScrOpInducSev 5000;
BA_ "GenSigTimeoutTime_IC_MulticS" SG_ 2566804992 AtScrOpInducSev 5000;
BA_ "CI_SigName" SG_ 2566804992 AtScrOpInducSev "Aftertreatment SCR Operator Inducement Severity";
BA_ "CI_SigId" SG_ 2566804992 AtScrOpInducSev 1252;
BA_ "CI_ParId" SG_ 2566804992 AtScrOpInducSev "5246";
BA_ "SigType" SG_ 2566804992 At1DefTankTemp1 1;
BA_ "SPN" SG_ 2566804992 At1DefTankTemp1 3031;
BA_ "GenSigTimeoutTime_VCM" SG_ 2566804992 At1DefTankTemp1 5000;
BA_ "GenSigTimeoutTime_SGW" SG_ 2566804992 At1DefTankTemp1 5000;
BA_ "GenSigTimeoutTime_PCM" SG_ 2566804992 At1DefTankTemp1 5000;
BA_ "GenSigTimeoutTime_BCM_NBM" SG_ 2566804992 At1DefTankTemp1 5000;
BA_ "GenSigStartValue" SG_ 2566804992 At1DefTankTemp1 40;
BA_ "CI_SigName" SG_ 2566804992 At1DefTankTemp1 "Aftertreatment 1 Diesel Exhaust Fluid Tank Temperature 1";
BA_ "CI_SigId" SG_ 2566804992 At1DefTankTemp1 1247;
BA_ "CI_ParId" SG_ 2566804992 At1DefTankTemp1 "3031";
BA_ "SigType" SG_ 2566804992 At1DefTankVol 1;
BA_ "SPN" SG_ 2566804992 At1DefTankVol 1761;
BA_ "GenSigTimeoutTime_VCM" SG_ 2566804992 At1DefTankVol 5000;
BA_ "GenSigTimeoutTime_SGW" SG_ 2566804992 At1DefTankVol 5000;
BA_ "GenSigTimeoutTime_PCM" SG_ 2566804992 At1DefTankVol 5000;
BA_ "GenSigTimeoutTime_IC_MulticS" SG_ 2566804992 At1DefTankVol 5000;
BA_ "GenSigTimeoutTime_FMS_FMS5" SG_ 2566804992 At1DefTankVol 5000;
BA_ "GenSigTimeoutTime_FMS_FMS4" SG_ 2566804992 At1DefTankVol 5000;
BA_ "CI_SigName" SG_ 2566804992 At1DefTankVol "Aftertreatment 1 Diesel Exhaust Fluid Tank Volume";
BA_ "CI_SigId" SG_ 2566804992 At1DefTankVol 1246;
BA_ "CI_ParId" SG_ 2566804992 At1DefTankVol "1761";
BA_ "SigType" SG_ 2566849271 Pwr 1;
BA_ "GenSigTimeoutTime_VCU" SG_ 2566849271 Pwr 500;
BA_ "GenSigTimeoutTime_SGW" SG_ 2566849271 Pwr 500;
BA_ "GenSigTimeoutTime_PCM" SG_ 2566849271 Pwr 500;
BA_ "GenSigStartValue" SG_ 2566849271 Pwr 32000;
BA_ "CI_SigName" SG_ 2566849271 Pwr "Power";
BA_ "CI_SigId" SG_ 2566849271 Pwr 1260;
BA_ "CI_ParId" SG_ 2566849271 Pwr "IB063";
BA_ "SigType" SG_ 2566849271 Cur 1;
BA_ "GenSigTimeoutTime_VCU" SG_ 2566849271 Cur 500;
BA_ "GenSigTimeoutTime_SGW" SG_ 2566849271 Cur 500;
BA_ "GenSigTimeoutTime_PCM" SG_ 2566849271 Cur 500;
BA_ "GenSigStartValue" SG_ 2566849271 Cur 32000;
BA_ "CI_SigName" SG_ 2566849271 Cur "Current";
BA_ "CI_SigId" SG_ 2566849271 Cur 1259;
BA_ "CI_ParId" SG_ 2566849271 Cur "IB062";
BA_ "SigType" SG_ 2566849271 _24DcdcOutV 1;
BA_ "GenSigTimeoutTime_VCU" SG_ 2566849271 _24DcdcOutV 500;
BA_ "GenSigTimeoutTime_SGW" SG_ 2566849271 _24DcdcOutV 500;
BA_ "GenSigTimeoutTime_PCM" SG_ 2566849271 _24DcdcOutV 500;
BA_ "CI_SigName" SG_ 2566849271 _24DcdcOutV "24 DCDC Output_Voltage";
BA_ "CI_SigId" SG_ 2566849271 _24DcdcOutV 1258;
BA_ "CI_ParId" SG_ 2566849271 _24DcdcOutV "IB061";
BA_ "SigType" SG_ 2566849271 ErrSts 4;
BA_ "GenSigTimeoutTime_VCU" SG_ 2566849271 ErrSts 500;
BA_ "GenSigTimeoutTime_SGW" SG_ 2566849271 ErrSts 500;
BA_ "GenSigTimeoutTime_PCM" SG_ 2566849271 ErrSts 500;
BA_ "CI_SigName" SG_ 2566849271 ErrSts "Error Status";
BA_ "CI_SigId" SG_ 2566849271 ErrSts 1257;
BA_ "CI_ParId" SG_ 2566849271 ErrSts "IB060";
BA_ "SigType" SG_ 2566849271 PulseEna 4;
BA_ "GenSigTimeoutTime_VCU" SG_ 2566849271 PulseEna 500;
BA_ "GenSigTimeoutTime_SGW" SG_ 2566849271 PulseEna 500;
BA_ "GenSigTimeoutTime_PCM" SG_ 2566849271 PulseEna 500;
BA_ "CI_SigName" SG_ 2566849271 PulseEna "Pulse enable";
BA_ "CI_SigId" SG_ 2566849271 PulseEna 1256;
BA_ "CI_ParId" SG_ 2566849271 PulseEna "IB059";
BA_ "SigType" SG_ 2566849015 Aux2Pwr 1;
BA_ "GenSigTimeoutTime_VCU" SG_ 2566849015 Aux2Pwr 500;
BA_ "GenSigTimeoutTime_SGW" SG_ 2566849015 Aux2Pwr 500;
BA_ "GenSigTimeoutTime_PCM" SG_ 2566849015 Aux2Pwr 500;
BA_ "GenSigStartValue" SG_ 2566849015 Aux2Pwr 32000;
BA_ "CI_SigName" SG_ 2566849015 Aux2Pwr "Aux 2 Power";
BA_ "CI_SigId" SG_ 2566849015 Aux2Pwr 1265;
BA_ "CI_ParId" SG_ 2566849015 Aux2Pwr "IB065";
BA_ "SigType" SG_ 2566849015 Aux2s 1;
BA_ "GenSigTimeoutTime_VCU" SG_ 2566849015 Aux2s 500;
BA_ "GenSigTimeoutTime_SGW" SG_ 2566849015 Aux2s 500;
BA_ "GenSigTimeoutTime_PCM" SG_ 2566849015 Aux2s 500;
BA_ "GenSigStartValue" SG_ 2566849015 Aux2s 32127;
BA_ "CI_SigName" SG_ 2566849015 Aux2s "Aux 2 Speed";
BA_ "CI_SigId" SG_ 2566849015 Aux2s 1264;
BA_ "CI_ParId" SG_ 2566849015 Aux2s "IB064";
BA_ "SigType" SG_ 2566849015 ErrSts_FF01F7 4;
BA_ "GenSigTimeoutTime_VCU" SG_ 2566849015 ErrSts_FF01F7 500;
BA_ "GenSigTimeoutTime_SGW" SG_ 2566849015 ErrSts_FF01F7 500;
BA_ "GenSigTimeoutTime_PCM" SG_ 2566849015 ErrSts_FF01F7 500;
BA_ "CI_SigName" SG_ 2566849015 ErrSts_FF01F7 "Error Status";
BA_ "CI_SigId" SG_ 2566849015 ErrSts_FF01F7 1263;
BA_ "CI_ParId" SG_ 2566849015 ErrSts_FF01F7 "IB060";
BA_ "SigType" SG_ 2566849015 PulseEna_FF01F7 4;
BA_ "GenSigTimeoutTime_VCU" SG_ 2566849015 PulseEna_FF01F7 500;
BA_ "GenSigTimeoutTime_SGW" SG_ 2566849015 PulseEna_FF01F7 500;
BA_ "GenSigTimeoutTime_PCM" SG_ 2566849015 PulseEna_FF01F7 500;
BA_ "CI_SigName" SG_ 2566849015 PulseEna_FF01F7 "Pulse enable";
BA_ "CI_SigId" SG_ 2566849015 PulseEna_FF01F7 1262;
BA_ "CI_ParId" SG_ 2566849015 PulseEna_FF01F7 "IB059";
BA_ "SigType" SG_ 2566848759 DcLinkV 1;
BA_ "GenSigTimeoutTime_VCU" SG_ 2566848759 DcLinkV 500;
BA_ "GenSigTimeoutTime_SGW" SG_ 2566848759 DcLinkV 500;
BA_ "GenSigTimeoutTime_PCM" SG_ 2566848759 DcLinkV 500;
BA_ "CI_SigName" SG_ 2566848759 DcLinkV "DC Link Voltage";
BA_ "CI_SigId" SG_ 2566848759 DcLinkV 1268;
BA_ "CI_ParId" SG_ 2566848759 DcLinkV "IB067";
BA_ "SigType" SG_ 2566848759 Term15Sts 4;
BA_ "GenSigTimeoutTime_VCU" SG_ 2566848759 Term15Sts 500;
BA_ "GenSigTimeoutTime_SGW" SG_ 2566848759 Term15Sts 500;
BA_ "GenSigTimeoutTime_PCM" SG_ 2566848759 Term15Sts 500;
BA_ "CI_SigName" SG_ 2566848759 Term15Sts "Terminal 15 Status";
BA_ "CI_SigId" SG_ 2566848759 Term15Sts 1267;
BA_ "CI_ParId" SG_ 2566848759 Term15Sts "IB066";
BA_ "SigType" SG_ 2566849270 Pwr_FF02F6 1;
BA_ "GenSigTimeoutTime_VCU" SG_ 2566849270 Pwr_FF02F6 500;
BA_ "GenSigTimeoutTime_SGW" SG_ 2566849270 Pwr_FF02F6 500;
BA_ "GenSigTimeoutTime_PCM" SG_ 2566849270 Pwr_FF02F6 500;
BA_ "GenSigStartValue" SG_ 2566849270 Pwr_FF02F6 32000;
BA_ "CI_SigName" SG_ 2566849270 Pwr_FF02F6 "Power";
BA_ "CI_SigId" SG_ 2566849270 Pwr_FF02F6 1274;
BA_ "CI_ParId" SG_ 2566849270 Pwr_FF02F6 "IB063";
BA_ "SigType" SG_ 2566849270 Cur_FF02F6 1;
BA_ "GenSigTimeoutTime_VCU" SG_ 2566849270 Cur_FF02F6 500;
BA_ "GenSigTimeoutTime_SGW" SG_ 2566849270 Cur_FF02F6 500;
BA_ "GenSigTimeoutTime_PCM" SG_ 2566849270 Cur_FF02F6 500;
BA_ "GenSigStartValue" SG_ 2566849270 Cur_FF02F6 32000;
BA_ "CI_SigName" SG_ 2566849270 Cur_FF02F6 "Current";
BA_ "CI_SigId" SG_ 2566849270 Cur_FF02F6 1273;
BA_ "CI_ParId" SG_ 2566849270 Cur_FF02F6 "IB062";
BA_ "SigType" SG_ 2566849270 _24DcdcOutV_FF02F6 1;
BA_ "GenSigTimeoutTime_VCU" SG_ 2566849270 _24DcdcOutV_FF02F6 500;
BA_ "GenSigTimeoutTime_SGW" SG_ 2566849270 _24DcdcOutV_FF02F6 500;
BA_ "GenSigTimeoutTime_PCM" SG_ 2566849270 _24DcdcOutV_FF02F6 500;
BA_ "CI_SigName" SG_ 2566849270 _24DcdcOutV_FF02F6 "24 DCDC Output_Voltage";
BA_ "CI_SigId" SG_ 2566849270 _24DcdcOutV_FF02F6 1272;
BA_ "CI_ParId" SG_ 2566849270 _24DcdcOutV_FF02F6 "IB061";
BA_ "SigType" SG_ 2566849270 ErrSts_FF02F6 4;
BA_ "GenSigTimeoutTime_VCU" SG_ 2566849270 ErrSts_FF02F6 500;
BA_ "GenSigTimeoutTime_SGW" SG_ 2566849270 ErrSts_FF02F6 500;
BA_ "GenSigTimeoutTime_PCM" SG_ 2566849270 ErrSts_FF02F6 500;
BA_ "CI_SigName" SG_ 2566849270 ErrSts_FF02F6 "Error Status";
BA_ "CI_SigId" SG_ 2566849270 ErrSts_FF02F6 1271;
BA_ "CI_ParId" SG_ 2566849270 ErrSts_FF02F6 "IB060";
BA_ "SigType" SG_ 2566849270 PulseEna_FF02F6 4;
BA_ "GenSigTimeoutTime_VCU" SG_ 2566849270 PulseEna_FF02F6 500;
BA_ "GenSigTimeoutTime_SGW" SG_ 2566849270 PulseEna_FF02F6 500;
BA_ "GenSigTimeoutTime_PCM" SG_ 2566849270 PulseEna_FF02F6 500;
BA_ "CI_SigName" SG_ 2566849270 PulseEna_FF02F6 "Pulse enable";
BA_ "CI_SigId" SG_ 2566849270 PulseEna_FF02F6 1270;
BA_ "CI_ParId" SG_ 2566849270 PulseEna_FF02F6 "IB059";
BA_ "SigType" SG_ 2566849014 Aux2Pwr_FF01F6 1;
BA_ "GenSigTimeoutTime_VCU" SG_ 2566849014 Aux2Pwr_FF01F6 500;
BA_ "GenSigTimeoutTime_SGW" SG_ 2566849014 Aux2Pwr_FF01F6 500;
BA_ "GenSigTimeoutTime_PCM" SG_ 2566849014 Aux2Pwr_FF01F6 500;
BA_ "GenSigStartValue" SG_ 2566849014 Aux2Pwr_FF01F6 32000;
BA_ "CI_SigName" SG_ 2566849014 Aux2Pwr_FF01F6 "Aux 2 Power";
BA_ "CI_SigId" SG_ 2566849014 Aux2Pwr_FF01F6 1279;
BA_ "CI_ParId" SG_ 2566849014 Aux2Pwr_FF01F6 "IB065";
BA_ "SigType" SG_ 2566849014 Aux2s_FF01F6 1;
BA_ "GenSigTimeoutTime_VCU" SG_ 2566849014 Aux2s_FF01F6 500;
BA_ "GenSigTimeoutTime_SGW" SG_ 2566849014 Aux2s_FF01F6 500;
BA_ "GenSigTimeoutTime_PCM" SG_ 2566849014 Aux2s_FF01F6 500;
BA_ "GenSigStartValue" SG_ 2566849014 Aux2s_FF01F6 32127;
BA_ "CI_SigName" SG_ 2566849014 Aux2s_FF01F6 "Aux 2 Speed";
BA_ "CI_SigId" SG_ 2566849014 Aux2s_FF01F6 1278;
BA_ "CI_ParId" SG_ 2566849014 Aux2s_FF01F6 "IB064";
BA_ "SigType" SG_ 2566849014 ErrSts_FF01F6 4;
BA_ "GenSigTimeoutTime_VCU" SG_ 2566849014 ErrSts_FF01F6 500;
BA_ "GenSigTimeoutTime_SGW" SG_ 2566849014 ErrSts_FF01F6 500;
BA_ "GenSigTimeoutTime_PCM" SG_ 2566849014 ErrSts_FF01F6 500;
BA_ "CI_SigName" SG_ 2566849014 ErrSts_FF01F6 "Error Status";
BA_ "CI_SigId" SG_ 2566849014 ErrSts_FF01F6 1277;
BA_ "CI_ParId" SG_ 2566849014 ErrSts_FF01F6 "IB060";
BA_ "SigType" SG_ 2566849014 PulseEna_FF01F6 4;
BA_ "GenSigTimeoutTime_VCU" SG_ 2566849014 PulseEna_FF01F6 500;
BA_ "GenSigTimeoutTime_SGW" SG_ 2566849014 PulseEna_FF01F6 500;
BA_ "GenSigTimeoutTime_PCM" SG_ 2566849014 PulseEna_FF01F6 500;
BA_ "CI_SigName" SG_ 2566849014 PulseEna_FF01F6 "Pulse enable";
BA_ "CI_SigId" SG_ 2566849014 PulseEna_FF01F6 1276;
BA_ "CI_ParId" SG_ 2566849014 PulseEna_FF01F6 "IB059";
BA_ "SigType" SG_ 2566848758 DcLinkV_FF00F6 1;
BA_ "GenSigTimeoutTime_VCU" SG_ 2566848758 DcLinkV_FF00F6 500;
BA_ "GenSigTimeoutTime_SGW" SG_ 2566848758 DcLinkV_FF00F6 500;
BA_ "GenSigTimeoutTime_PCM" SG_ 2566848758 DcLinkV_FF00F6 500;
BA_ "CI_SigName" SG_ 2566848758 DcLinkV_FF00F6 "DC Link Voltage";
BA_ "CI_SigId" SG_ 2566848758 DcLinkV_FF00F6 1282;
BA_ "CI_ParId" SG_ 2566848758 DcLinkV_FF00F6 "IB067";
BA_ "SigType" SG_ 2566848758 Term15Sts_FF00F6 4;
BA_ "GenSigTimeoutTime_VCU" SG_ 2566848758 Term15Sts_FF00F6 500;
BA_ "GenSigTimeoutTime_SGW" SG_ 2566848758 Term15Sts_FF00F6 500;
BA_ "GenSigTimeoutTime_PCM" SG_ 2566848758 Term15Sts_FF00F6 500;
BA_ "CI_SigName" SG_ 2566848758 Term15Sts_FF00F6 "Terminal 15 Status";
BA_ "CI_SigId" SG_ 2566848758 Term15Sts_FF00F6 1281;
BA_ "CI_ParId" SG_ 2566848758 Term15Sts_FF00F6 "IB066";
BA_ "SigType" SG_ 2566838561 Auxi_OChan2_ElecHeaterPower 1;
BA_ "GenSigTimeoutTime_VMU" SG_ 2566838561 Auxi_OChan2_ElecHeaterPower 500;
BA_ "GenSigTimeoutTime_VCU" SG_ 2566838561 Auxi_OChan2_ElecHeaterPower 500;
BA_ "GenSigTimeoutTime_SGW" SG_ 2566838561 Auxi_OChan2_ElecHeaterPower 500;
BA_ "GenSigTimeoutTime_PCM" SG_ 2566838561 Auxi_OChan2_ElecHeaterPower 500;
BA_ "CI_SigName" SG_ 2566838561 Auxi_OChan2_ElecHeaterPower "Auxi_OChan2_ElecHeaterPower";
BA_ "CI_SigId" SG_ 2566838561 Auxi_OChan2_ElecHeaterPower 15027;
BA_ "CI_ParId" SG_ 2566838561 Auxi_OChan2_ElecHeaterPower "IB2118";
BA_ "SigType" SG_ 2566838561 Auxi_OChan2_ElecHeatPower_LSB 1;
BA_ "GenSigTimeoutTime_VMU" SG_ 2566838561 Auxi_OChan2_ElecHeatPower_LSB 500;
BA_ "GenSigTimeoutTime_VCU" SG_ 2566838561 Auxi_OChan2_ElecHeatPower_LSB 500;
BA_ "GenSigTimeoutTime_SGW" SG_ 2566838561 Auxi_OChan2_ElecHeatPower_LSB 500;
BA_ "GenSigTimeoutTime_PCM" SG_ 2566838561 Auxi_OChan2_ElecHeatPower_LSB 500;
BA_ "CI_SigName" SG_ 2566838561 Auxi_OChan2_ElecHeatPower_LSB "Auxi_OChan2_ElecHeatPower_LSB";
BA_ "CI_SigId" SG_ 2566838561 Auxi_OChan2_ElecHeatPower_LSB 15026;
BA_ "CI_ParId" SG_ 2566838561 Auxi_OChan2_ElecHeatPower_LSB "IB2117";
BA_ "SigType" SG_ 2566838561 AuxIo16 4;
BA_ "SPN" SG_ 2566838561 AuxIo16 716;
BA_ "GenSigTimeoutTime_VMU" SG_ 2566838561 AuxIo16 500;
BA_ "GenSigTimeoutTime_VCU" SG_ 2566838561 AuxIo16 500;
BA_ "GenSigTimeoutTime_SGW" SG_ 2566838561 AuxIo16 500;
BA_ "GenSigTimeoutTime_PCM" SG_ 2566838561 AuxIo16 500;
BA_ "GenSigTimeoutTime_MPPxPTFE2" SG_ 2566838561 AuxIo16 500;
BA_ "GenSigTimeoutTime_FMS_FMS5" SG_ 2566838561 AuxIo16 500;
BA_ "CI_SigName" SG_ 2566838561 AuxIo16 "Auxiliary I/O #16";
BA_ "CI_SigId" SG_ 2566838561 AuxIo16 2961;
BA_ "CI_ParId" SG_ 2566838561 AuxIo16 "716";
VAL_ 2566811431 AccSetDistMode 0 "Mode #1, largest distance" 1 "Mode #2" 2 "Mode #3" 3 "Mode #4" 4 "Mode #5,shortest distance" 5 "Conventional CC mode" 6 "Error condition" 7 "Not Available/not valid" ;
VAL_ 2566811431 AccMode 0 "Off, Standby, enabled" 1 "Speed control active" 2 "Distance control active" 3 "Overtake mode" 4 "Hold mode" 5 "Finish mode" 6 "Disabled or error condition" 7 "Not Available/not valid" ;
VAL_ 2566803735 AccUseDem 0 "Not using ACC keeping" 1 "Using ACC distance keeping" 2 "Reserved" 3 "Don't Care" ;
VAL_ 2565406464 Pgn_Busy 37120 "VLSI1" 40448 "DM29" 41216 "DM33" 41728 "DM31" 41984 "DM30" 47360 "PLLT(PlanListLifetime)" 47872 "PLD(PlanListDistance)" 49408 "DM21" 49664 "DM20" 49920 "DM22" 53504 "MaintBcIc" 54016 "DM19" 60928 "ACL" 61184 "STOD" 64342 "HVESP3CFG" 64344 "HVESP2CFG" 64346 "HVESP1CFG" 64529 "TGFI" 64579 "TCSI" 64582 "TSIS" 64583 "MTI" 64605 "HVESSCFG" 64606 "HVESSHIST" 64653 "PII" 64701 "A1SCRSI2" 64782 "AT1OGC2" 64784 "AT1IGC2" 64839 "TML" 64879 "EEC8" 64896 "DM28" 64905 "VDS2" 64906 "J2012" 64912 "AETC" 64920 "AT1HI1" 64949 "DM23" 64950 "DM24" 64951 "DM25" 64952 "DM26" 64953 "TPRI" 64965 "ECUID" 64981 "EEC5" 65039 "LC" 65099 "TCFG2" 65109 "GFD" 65127 "CCC" 65131 "DI" 65136 "CVW" 65144 "TP1" 65145 "TP2" 65146 "TP3" 65195 "ETC6" 65196 "EBC4" 65199 "GFC" 65201 "EH" 65202 "GFI1" 65203 "LFI1" 65208 "GTFI" 65212 "CBI" 65214 "EEC4" 65216 "SERV" 65219 "ETC5" 65221 "ETC4" 65223 "ETC3" 65227 "DM02" 65228 "DM03" 65229 "DM04" 65230 "DM05" 65231 "DM06" 65234 "DM10" 65235 "DM11" 65236 "DM12" 65242 "SOFT" 65244 "IO" 65248 "VD" 65250 "TCFG" 65253 "HOURS" 65254 "TD" 65255 "VH" 65256 "VDS" 65257 "LFC1" 65258 "VW" 65259 "CI" 65260 "VI" 65261 "CCSS" 65284 "PB_DriversConsentOnPersonalData" 65376 "VehCfg" 65413 "PB_3CT" 65482 "PB_ID1" 65484 "PB_VNS" 65502 "Av2" 65520 "SCh" 65521 "DIS" 65524 "PB_IVA" ;
VAL_ 2565406464 Pgn_Ad 37120 "VLSI1" 40448 "DM29" 41216 "DM33" 41728 "DM31" 41984 "DM30" 47360 "PLLT(PlanListLifetime)" 47872 "PLD(PlanListDistance)" 49408 "DM21" 49664 "DM20" 49920 "DM22" 53504 "MaintBcIc" 54016 "DM19" 60928 "ACL" 61184 "STOD" 64342 "HVESP3CFG" 64344 "HVESP2CFG" 64346 "HVESP1CFG" 64529 "TGFI" 64579 "TCSI" 64582 "TSIS" 64583 "MTI" 64605 "HVESSCFG" 64606 "HVESSHIST" 64653 "PII" 64701 "A1SCRSI2" 64782 "AT1OGC2" 64784 "AT1IGC2" 64839 "TML" 64879 "EEC8" 64896 "DM28" 64905 "VDS2" 64906 "J2012" 64912 "AETC" 64920 "AT1HI1" 64949 "DM23" 64950 "DM24" 64951 "DM25" 64952 "DM26" 64953 "TPRI" 64965 "ECUID" 64981 "EEC5" 65039 "LC" 65099 "TCFG2" 65109 "GFD" 65127 "CCC" 65131 "DI" 65136 "CVW" 65144 "TP1" 65145 "TP2" 65146 "TP3" 65195 "ETC6" 65196 "EBC4" 65199 "GFC" 65201 "EH" 65202 "GFI1" 65203 "LFI1" 65208 "GTFI" 65212 "CBI" 65214 "EEC4" 65216 "SERV" 65219 "ETC5" 65221 "ETC4" 65223 "ETC3" 65227 "DM02" 65228 "DM03" 65229 "DM04" 65230 "DM05" 65231 "DM06" 65234 "DM10" 65235 "DM11" 65236 "DM12" 65242 "SOFT" 65244 "IO" 65248 "VD" 65250 "TCFG" 65253 "HOURS" 65254 "TD" 65255 "VH" 65256 "VDS" 65257 "LFC1" 65258 "VW" 65259 "CI" 65260 "VI" 65261 "CCSS" 65284 "PB_DriversConsentOnPersonalData" 65376 "VehCfg" 65413 "PB_3CT" 65482 "PB_ID1" 65484 "PB_VNS" 65502 "Av2" 65520 "SCh" 65521 "DIS" 65524 "PB_IVA" ;
VAL_ 2565406464 Pgn_Nack 37120 "VLSI1" 40448 "DM29" 41216 "DM33" 41728 "DM31" 41984 "DM30" 47360 "PLLT(PlanListLifetime)" 47872 "PLD(PlanListDistance)" 49408 "DM21" 49664 "DM20" 49920 "DM22" 53504 "MaintBcIc" 54016 "DM19" 60928 "ACL" 61184 "STOD" 64342 "HVESP3CFG" 64344 "HVESP2CFG" 64346 "HVESP1CFG" 64529 "TGFI" 64579 "TCSI" 64582 "TSIS" 64583 "MTI" 64605 "HVESSCFG" 64606 "HVESSHIST" 64653 "PII" 64701 "A1SCRSI2" 64782 "AT1OGC2" 64784 "AT1IGC2" 64839 "TML" 64879 "EEC8" 64896 "DM28" 64905 "VDS2" 64906 "J2012" 64912 "AETC" 64920 "AT1HI1" 64949 "DM23" 64950 "DM24" 64951 "DM25" 64952 "DM26" 64953 "TPRI" 64965 "ECUID" 64981 "EEC5" 65039 "LC" 65099 "TCFG2" 65109 "GFD" 65127 "CCC" 65131 "DI" 65136 "CVW" 65144 "TP1" 65145 "TP2" 65146 "TP3" 65195 "ETC6" 65196 "EBC4" 65199 "GFC" 65201 "EH" 65202 "GFI1" 65203 "LFI1" 65208 "GTFI" 65212 "CBI" 65214 "EEC4" 65216 "SERV" 65219 "ETC5" 65221 "ETC4" 65223 "ETC3" 65227 "DM02" 65228 "DM03" 65229 "DM04" 65230 "DM05" 65231 "DM06" 65234 "DM10" 65235 "DM11" 65236 "DM12" 65242 "SOFT" 65244 "IO" 65248 "VD" 65250 "TCFG" 65253 "HOURS" 65254 "TD" 65255 "VH" 65256 "VDS" 65257 "LFC1" 65258 "VW" 65259 "CI" 65260 "VI" 65261 "CCSS" 65284 "PB_DriversConsentOnPersonalData" 65376 "VehCfg" 65413 "PB_3CT" 65482 "PB_ID1" 65484 "PB_VNS" 65502 "Av2" 65520 "SCh" 65521 "DIS" 65524 "PB_IVA" ;
VAL_ 2565406464 Pgn_Ack 37120 "VLSI1" 40448 "DM29" 41216 "DM33" 41728 "DM31" 41984 "DM30" 47360 "PLLT(PlanListLifetime)" 47872 "PLD(PlanListDistance)" 49408 "DM21" 49664 "DM20" 49920 "DM22" 53504 "MaintBcIc" 54016 "DM19" 60928 "ACL" 61184 "STOD" 64342 "HVESP3CFG" 64344 "HVESP2CFG" 64346 "HVESP1CFG" 64529 "TGFI" 64579 "TCSI" 64582 "TSIS" 64583 "MTI" 64605 "HVESSCFG" 64606 "HVESSHIST" 64653 "PII" 64701 "A1SCRSI2" 64782 "AT1OGC2" 64784 "AT1IGC2" 64839 "TML" 64879 "EEC8" 64896 "DM28" 64905 "VDS2" 64906 "J2012" 64912 "AETC" 64920 "AT1HI1" 64949 "DM23" 64950 "DM24" 64951 "DM25" 64952 "DM26" 64953 "TPRI" 64965 "ECUID" 64981 "EEC5" 65039 "LC" 65099 "TCFG2" 65109 "GFD" 65127 "CCC" 65131 "DI" 65136 "CVW" 65144 "TP1" 65145 "TP2" 65146 "TP3" 65195 "ETC6" 65196 "EBC4" 65199 "GFC" 65201 "EH" 65202 "GFI1" 65203 "LFI1" 65208 "GTFI" 65212 "CBI" 65214 "EEC4" 65216 "SERV" 65219 "ETC5" 65221 "ETC4" 65223 "ETC3" 65227 "DM02" 65228 "DM03" 65229 "DM04" 65230 "DM05" 65231 "DM06" 65234 "DM10" 65235 "DM11" 65236 "DM12" 65242 "SOFT" 65244 "IO" 65248 "VD" 65250 "TCFG" 65253 "HOURS" 65254 "TD" 65255 "VH" 65256 "VDS" 65257 "LFC1" 65258 "VW" 65259 "CI" 65260 "VI" 65261 "CCSS" 65284 "PB_DriversConsentOnPersonalData" 65376 "VehCfg" 65413 "PB_3CT" 65482 "PB_ID1" 65484 "PB_VNS" 65502 "Av2" 65520 "SCh" 65521 "DIS" 65524 "PB_IVA" ;
VAL_ 2565406464 CtrlByte_Ackm 0 "ACK" 1 "NACK" 2 "Access Denied" 3 "Cannot Respond" ;
VAL_ 2565406467 Pgn_Busy_E8FF03 37120 "VLSI1" 40448 "DM29" 41216 "DM33" 41728 "DM31" 41984 "DM30" 47360 "PLLT(PlanListLifetime)" 47872 "PLD(PlanListDistance)" 49408 "DM21" 49664 "DM20" 49920 "DM22" 53504 "MaintBcIc" 54016 "DM19" 60928 "ACL" 61184 "STOD" 64342 "HVESP3CFG" 64344 "HVESP2CFG" 64346 "HVESP1CFG" 64529 "TGFI" 64579 "TCSI" 64582 "TSIS" 64583 "MTI" 64605 "HVESSCFG" 64606 "HVESSHIST" 64653 "PII" 64701 "A1SCRSI2" 64782 "AT1OGC2" 64784 "AT1IGC2" 64839 "TML" 64879 "EEC8" 64896 "DM28" 64905 "VDS2" 64906 "J2012" 64912 "AETC" 64920 "AT1HI1" 64949 "DM23" 64950 "DM24" 64951 "DM25" 64952 "DM26" 64953 "TPRI" 64965 "ECUID" 64981 "EEC5" 65039 "LC" 65099 "TCFG2" 65109 "GFD" 65127 "CCC" 65131 "DI" 65136 "CVW" 65144 "TP1" 65145 "TP2" 65146 "TP3" 65195 "ETC6" 65196 "EBC4" 65199 "GFC" 65201 "EH" 65202 "GFI1" 65203 "LFI1" 65208 "GTFI" 65212 "CBI" 65214 "EEC4" 65216 "SERV" 65219 "ETC5" 65221 "ETC4" 65223 "ETC3" 65227 "DM02" 65228 "DM03" 65229 "DM04" 65230 "DM05" 65231 "DM06" 65234 "DM10" 65235 "DM11" 65236 "DM12" 65242 "SOFT" 65244 "IO" 65248 "VD" 65250 "TCFG" 65253 "HOURS" 65254 "TD" 65255 "VH" 65256 "VDS" 65257 "LFC1" 65258 "VW" 65259 "CI" 65260 "VI" 65261 "CCSS" 65284 "PB_DriversConsentOnPersonalData" 65376 "VehCfg" 65413 "PB_3CT" 65482 "PB_ID1" 65484 "PB_VNS" 65502 "Av2" 65520 "SCh" 65521 "DIS" 65524 "PB_IVA" ;
VAL_ 2565406467 Pgn_Ad_E8FF03 37120 "VLSI1" 40448 "DM29" 41216 "DM33" 41728 "DM31" 41984 "DM30" 47360 "PLLT(PlanListLifetime)" 47872 "PLD(PlanListDistance)" 49408 "DM21" 49664 "DM20" 49920 "DM22" 53504 "MaintBcIc" 54016 "DM19" 60928 "ACL" 61184 "STOD" 64342 "HVESP3CFG" 64344 "HVESP2CFG" 64346 "HVESP1CFG" 64529 "TGFI" 64579 "TCSI" 64582 "TSIS" 64583 "MTI" 64605 "HVESSCFG" 64606 "HVESSHIST" 64653 "PII" 64701 "A1SCRSI2" 64782 "AT1OGC2" 64784 "AT1IGC2" 64839 "TML" 64879 "EEC8" 64896 "DM28" 64905 "VDS2" 64906 "J2012" 64912 "AETC" 64920 "AT1HI1" 64949 "DM23" 64950 "DM24" 64951 "DM25" 64952 "DM26" 64953 "TPRI" 64965 "ECUID" 64981 "EEC5" 65039 "LC" 65099 "TCFG2" 65109 "GFD" 65127 "CCC" 65131 "DI" 65136 "CVW" 65144 "TP1" 65145 "TP2" 65146 "TP3" 65195 "ETC6" 65196 "EBC4" 65199 "GFC" 65201 "EH" 65202 "GFI1" 65203 "LFI1" 65208 "GTFI" 65212 "CBI" 65214 "EEC4" 65216 "SERV" 65219 "ETC5" 65221 "ETC4" 65223 "ETC3" 65227 "DM02" 65228 "DM03" 65229 "DM04" 65230 "DM05" 65231 "DM06" 65234 "DM10" 65235 "DM11" 65236 "DM12" 65242 "SOFT" 65244 "IO" 65248 "VD" 65250 "TCFG" 65253 "HOURS" 65254 "TD" 65255 "VH" 65256 "VDS" 65257 "LFC1" 65258 "VW" 65259 "CI" 65260 "VI" 65261 "CCSS" 65284 "PB_DriversConsentOnPersonalData" 65376 "VehCfg" 65413 "PB_3CT" 65482 "PB_ID1" 65484 "PB_VNS" 65502 "Av2" 65520 "SCh" 65521 "DIS" 65524 "PB_IVA" ;
VAL_ 2565406467 Pgn_Nack_E8FF03 37120 "VLSI1" 40448 "DM29" 41216 "DM33" 41728 "DM31" 41984 "DM30" 47360 "PLLT(PlanListLifetime)" 47872 "PLD(PlanListDistance)" 49408 "DM21" 49664 "DM20" 49920 "DM22" 53504 "MaintBcIc" 54016 "DM19" 60928 "ACL" 61184 "STOD" 64342 "HVESP3CFG" 64344 "HVESP2CFG" 64346 "HVESP1CFG" 64529 "TGFI" 64579 "TCSI" 64582 "TSIS" 64583 "MTI" 64605 "HVESSCFG" 64606 "HVESSHIST" 64653 "PII" 64701 "A1SCRSI2" 64782 "AT1OGC2" 64784 "AT1IGC2" 64839 "TML" 64879 "EEC8" 64896 "DM28" 64905 "VDS2" 64906 "J2012" 64912 "AETC" 64920 "AT1HI1" 64949 "DM23" 64950 "DM24" 64951 "DM25" 64952 "DM26" 64953 "TPRI" 64965 "ECUID" 64981 "EEC5" 65039 "LC" 65099 "TCFG2" 65109 "GFD" 65127 "CCC" 65131 "DI" 65136 "CVW" 65144 "TP1" 65145 "TP2" 65146 "TP3" 65195 "ETC6" 65196 "EBC4" 65199 "GFC" 65201 "EH" 65202 "GFI1" 65203 "LFI1" 65208 "GTFI" 65212 "CBI" 65214 "EEC4" 65216 "SERV" 65219 "ETC5" 65221 "ETC4" 65223 "ETC3" 65227 "DM02" 65228 "DM03" 65229 "DM04" 65230 "DM05" 65231 "DM06" 65234 "DM10" 65235 "DM11" 65236 "DM12" 65242 "SOFT" 65244 "IO" 65248 "VD" 65250 "TCFG" 65253 "HOURS" 65254 "TD" 65255 "VH" 65256 "VDS" 65257 "LFC1" 65258 "VW" 65259 "CI" 65260 "VI" 65261 "CCSS" 65284 "PB_DriversConsentOnPersonalData" 65376 "VehCfg" 65413 "PB_3CT" 65482 "PB_ID1" 65484 "PB_VNS" 65502 "Av2" 65520 "SCh" 65521 "DIS" 65524 "PB_IVA" ;
VAL_ 2565406467 Pgn_Ack_E8FF03 37120 "VLSI1" 40448 "DM29" 41216 "DM33" 41728 "DM31" 41984 "DM30" 47360 "PLLT(PlanListLifetime)" 47872 "PLD(PlanListDistance)" 49408 "DM21" 49664 "DM20" 49920 "DM22" 53504 "MaintBcIc" 54016 "DM19" 60928 "ACL" 61184 "STOD" 64342 "HVESP3CFG" 64344 "HVESP2CFG" 64346 "HVESP1CFG" 64529 "TGFI" 64579 "TCSI" 64582 "TSIS" 64583 "MTI" 64605 "HVESSCFG" 64606 "HVESSHIST" 64653 "PII" 64701 "A1SCRSI2" 64782 "AT1OGC2" 64784 "AT1IGC2" 64839 "TML" 64879 "EEC8" 64896 "DM28" 64905 "VDS2" 64906 "J2012" 64912 "AETC" 64920 "AT1HI1" 64949 "DM23" 64950 "DM24" 64951 "DM25" 64952 "DM26" 64953 "TPRI" 64965 "ECUID" 64981 "EEC5" 65039 "LC" 65099 "TCFG2" 65109 "GFD" 65127 "CCC" 65131 "DI" 65136 "CVW" 65144 "TP1" 65145 "TP2" 65146 "TP3" 65195 "ETC6" 65196 "EBC4" 65199 "GFC" 65201 "EH" 65202 "GFI1" 65203 "LFI1" 65208 "GTFI" 65212 "CBI" 65214 "EEC4" 65216 "SERV" 65219 "ETC5" 65221 "ETC4" 65223 "ETC3" 65227 "DM02" 65228 "DM03" 65229 "DM04" 65230 "DM05" 65231 "DM06" 65234 "DM10" 65235 "DM11" 65236 "DM12" 65242 "SOFT" 65244 "IO" 65248 "VD" 65250 "TCFG" 65253 "HOURS" 65254 "TD" 65255 "VH" 65256 "VDS" 65257 "LFC1" 65258 "VW" 65259 "CI" 65260 "VI" 65261 "CCSS" 65284 "PB_DriversConsentOnPersonalData" 65376 "VehCfg" 65413 "PB_3CT" 65482 "PB_ID1" 65484 "PB_VNS" 65502 "Av2" 65520 "SCh" 65521 "DIS" 65524 "PB_IVA" ;
VAL_ 2565406467 CtrlByte_Ackm_E8FF03 0 "ACK" 1 "NACK" 2 "Access Denied" 3 "Cannot Respond" ;
VAL_ 2565406475 Pgn_Busy_E8FF0B 37120 "VLSI1" 40448 "DM29" 41216 "DM33" 41728 "DM31" 41984 "DM30" 47360 "PLLT(PlanListLifetime)" 47872 "PLD(PlanListDistance)" 49408 "DM21" 49664 "DM20" 49920 "DM22" 53504 "MaintBcIc" 54016 "DM19" 60928 "ACL" 61184 "STOD" 64342 "HVESP3CFG" 64344 "HVESP2CFG" 64346 "HVESP1CFG" 64529 "TGFI" 64579 "TCSI" 64582 "TSIS" 64583 "MTI" 64605 "HVESSCFG" 64606 "HVESSHIST" 64653 "PII" 64701 "A1SCRSI2" 64782 "AT1OGC2" 64784 "AT1IGC2" 64839 "TML" 64879 "EEC8" 64896 "DM28" 64905 "VDS2" 64906 "J2012" 64912 "AETC" 64920 "AT1HI1" 64949 "DM23" 64950 "DM24" 64951 "DM25" 64952 "DM26" 64953 "TPRI" 64965 "ECUID" 64981 "EEC5" 65039 "LC" 65099 "TCFG2" 65109 "GFD" 65127 "CCC" 65131 "DI" 65136 "CVW" 65144 "TP1" 65145 "TP2" 65146 "TP3" 65195 "ETC6" 65196 "EBC4" 65199 "GFC" 65201 "EH" 65202 "GFI1" 65203 "LFI1" 65208 "GTFI" 65212 "CBI" 65214 "EEC4" 65216 "SERV" 65219 "ETC5" 65221 "ETC4" 65223 "ETC3" 65227 "DM02" 65228 "DM03" 65229 "DM04" 65230 "DM05" 65231 "DM06" 65234 "DM10" 65235 "DM11" 65236 "DM12" 65242 "SOFT" 65244 "IO" 65248 "VD" 65250 "TCFG" 65253 "HOURS" 65254 "TD" 65255 "VH" 65256 "VDS" 65257 "LFC1" 65258 "VW" 65259 "CI" 65260 "VI" 65261 "CCSS" 65284 "PB_DriversConsentOnPersonalData" 65376 "VehCfg" 65413 "PB_3CT" 65482 "PB_ID1" 65484 "PB_VNS" 65502 "Av2" 65520 "SCh" 65521 "DIS" 65524 "PB_IVA" ;
VAL_ 2565406475 Pgn_Ad_E8FF0B 37120 "VLSI1" 40448 "DM29" 41216 "DM33" 41728 "DM31" 41984 "DM30" 47360 "PLLT(PlanListLifetime)" 47872 "PLD(PlanListDistance)" 49408 "DM21" 49664 "DM20" 49920 "DM22" 53504 "MaintBcIc" 54016 "DM19" 60928 "ACL" 61184 "STOD" 64342 "HVESP3CFG" 64344 "HVESP2CFG" 64346 "HVESP1CFG" 64529 "TGFI" 64579 "TCSI" 64582 "TSIS" 64583 "MTI" 64605 "HVESSCFG" 64606 "HVESSHIST" 64653 "PII" 64701 "A1SCRSI2" 64782 "AT1OGC2" 64784 "AT1IGC2" 64839 "TML" 64879 "EEC8" 64896 "DM28" 64905 "VDS2" 64906 "J2012" 64912 "AETC" 64920 "AT1HI1" 64949 "DM23" 64950 "DM24" 64951 "DM25" 64952 "DM26" 64953 "TPRI" 64965 "ECUID" 64981 "EEC5" 65039 "LC" 65099 "TCFG2" 65109 "GFD" 65127 "CCC" 65131 "DI" 65136 "CVW" 65144 "TP1" 65145 "TP2" 65146 "TP3" 65195 "ETC6" 65196 "EBC4" 65199 "GFC" 65201 "EH" 65202 "GFI1" 65203 "LFI1" 65208 "GTFI" 65212 "CBI" 65214 "EEC4" 65216 "SERV" 65219 "ETC5" 65221 "ETC4" 65223 "ETC3" 65227 "DM02" 65228 "DM03" 65229 "DM04" 65230 "DM05" 65231 "DM06" 65234 "DM10" 65235 "DM11" 65236 "DM12" 65242 "SOFT" 65244 "IO" 65248 "VD" 65250 "TCFG" 65253 "HOURS" 65254 "TD" 65255 "VH" 65256 "VDS" 65257 "LFC1" 65258 "VW" 65259 "CI" 65260 "VI" 65261 "CCSS" 65284 "PB_DriversConsentOnPersonalData" 65376 "VehCfg" 65413 "PB_3CT" 65482 "PB_ID1" 65484 "PB_VNS" 65502 "Av2" 65520 "SCh" 65521 "DIS" 65524 "PB_IVA" ;
VAL_ 2565406475 Pgn_Nack_E8FF0B 37120 "VLSI1" 40448 "DM29" 41216 "DM33" 41728 "DM31" 41984 "DM30" 47360 "PLLT(PlanListLifetime)" 47872 "PLD(PlanListDistance)" 49408 "DM21" 49664 "DM20" 49920 "DM22" 53504 "MaintBcIc" 54016 "DM19" 60928 "ACL" 61184 "STOD" 64342 "HVESP3CFG" 64344 "HVESP2CFG" 64346 "HVESP1CFG" 64529 "TGFI" 64579 "TCSI" 64582 "TSIS" 64583 "MTI" 64605 "HVESSCFG" 64606 "HVESSHIST" 64653 "PII" 64701 "A1SCRSI2" 64782 "AT1OGC2" 64784 "AT1IGC2" 64839 "TML" 64879 "EEC8" 64896 "DM28" 64905 "VDS2" 64906 "J2012" 64912 "AETC" 64920 "AT1HI1" 64949 "DM23" 64950 "DM24" 64951 "DM25" 64952 "DM26" 64953 "TPRI" 64965 "ECUID" 64981 "EEC5" 65039 "LC" 65099 "TCFG2" 65109 "GFD" 65127 "CCC" 65131 "DI" 65136 "CVW" 65144 "TP1" 65145 "TP2" 65146 "TP3" 65195 "ETC6" 65196 "EBC4" 65199 "GFC" 65201 "EH" 65202 "GFI1" 65203 "LFI1" 65208 "GTFI" 65212 "CBI" 65214 "EEC4" 65216 "SERV" 65219 "ETC5" 65221 "ETC4" 65223 "ETC3" 65227 "DM02" 65228 "DM03" 65229 "DM04" 65230 "DM05" 65231 "DM06" 65234 "DM10" 65235 "DM11" 65236 "DM12" 65242 "SOFT" 65244 "IO" 65248 "VD" 65250 "TCFG" 65253 "HOURS" 65254 "TD" 65255 "VH" 65256 "VDS" 65257 "LFC1" 65258 "VW" 65259 "CI" 65260 "VI" 65261 "CCSS" 65284 "PB_DriversConsentOnPersonalData" 65376 "VehCfg" 65413 "PB_3CT" 65482 "PB_ID1" 65484 "PB_VNS" 65502 "Av2" 65520 "SCh" 65521 "DIS" 65524 "PB_IVA" ;
VAL_ 2565406475 Pgn_Ack_E8FF0B 37120 "VLSI1" 40448 "DM29" 41216 "DM33" 41728 "DM31" 41984 "DM30" 47360 "PLLT(PlanListLifetime)" 47872 "PLD(PlanListDistance)" 49408 "DM21" 49664 "DM20" 49920 "DM22" 53504 "MaintBcIc" 54016 "DM19" 60928 "ACL" 61184 "STOD" 64342 "HVESP3CFG" 64344 "HVESP2CFG" 64346 "HVESP1CFG" 64529 "TGFI" 64579 "TCSI" 64582 "TSIS" 64583 "MTI" 64605 "HVESSCFG" 64606 "HVESSHIST" 64653 "PII" 64701 "A1SCRSI2" 64782 "AT1OGC2" 64784 "AT1IGC2" 64839 "TML" 64879 "EEC8" 64896 "DM28" 64905 "VDS2" 64906 "J2012" 64912 "AETC" 64920 "AT1HI1" 64949 "DM23" 64950 "DM24" 64951 "DM25" 64952 "DM26" 64953 "TPRI" 64965 "ECUID" 64981 "EEC5" 65039 "LC" 65099 "TCFG2" 65109 "GFD" 65127 "CCC" 65131 "DI" 65136 "CVW" 65144 "TP1" 65145 "TP2" 65146 "TP3" 65195 "ETC6" 65196 "EBC4" 65199 "GFC" 65201 "EH" 65202 "GFI1" 65203 "LFI1" 65208 "GTFI" 65212 "CBI" 65214 "EEC4" 65216 "SERV" 65219 "ETC5" 65221 "ETC4" 65223 "ETC3" 65227 "DM02" 65228 "DM03" 65229 "DM04" 65230 "DM05" 65231 "DM06" 65234 "DM10" 65235 "DM11" 65236 "DM12" 65242 "SOFT" 65244 "IO" 65248 "VD" 65250 "TCFG" 65253 "HOURS" 65254 "TD" 65255 "VH" 65256 "VDS" 65257 "LFC1" 65258 "VW" 65259 "CI" 65260 "VI" 65261 "CCSS" 65284 "PB_DriversConsentOnPersonalData" 65376 "VehCfg" 65413 "PB_3CT" 65482 "PB_ID1" 65484 "PB_VNS" 65502 "Av2" 65520 "SCh" 65521 "DIS" 65524 "PB_IVA" ;
VAL_ 2565406475 CtrlByte_Ackm_E8FF0B 0 "ACK" 1 "NACK" 2 "Access Denied" 3 "Cannot Respond" ;
VAL_ 2565406487 Pgn_Busy_E8FF17 37120 "VLSI1" 40448 "DM29" 41216 "DM33" 41728 "DM31" 41984 "DM30" 47360 "PLLT(PlanListLifetime)" 47872 "PLD(PlanListDistance)" 49408 "DM21" 49664 "DM20" 49920 "DM22" 53504 "MaintBcIc" 54016 "DM19" 60928 "ACL" 61184 "STOD" 64342 "HVESP3CFG" 64344 "HVESP2CFG" 64346 "HVESP1CFG" 64529 "TGFI" 64579 "TCSI" 64582 "TSIS" 64583 "MTI" 64605 "HVESSCFG" 64606 "HVESSHIST" 64653 "PII" 64701 "A1SCRSI2" 64782 "AT1OGC2" 64784 "AT1IGC2" 64839 "TML" 64879 "EEC8" 64896 "DM28" 64905 "VDS2" 64906 "J2012" 64912 "AETC" 64920 "AT1HI1" 64949 "DM23" 64950 "DM24" 64951 "DM25" 64952 "DM26" 64953 "TPRI" 64965 "ECUID" 64981 "EEC5" 65039 "LC" 65099 "TCFG2" 65109 "GFD" 65127 "CCC" 65131 "DI" 65136 "CVW" 65144 "TP1" 65145 "TP2" 65146 "TP3" 65195 "ETC6" 65196 "EBC4" 65199 "GFC" 65201 "EH" 65202 "GFI1" 65203 "LFI1" 65208 "GTFI" 65212 "CBI" 65214 "EEC4" 65216 "SERV" 65219 "ETC5" 65221 "ETC4" 65223 "ETC3" 65227 "DM02" 65228 "DM03" 65229 "DM04" 65230 "DM05" 65231 "DM06" 65234 "DM10" 65235 "DM11" 65236 "DM12" 65242 "SOFT" 65244 "IO" 65248 "VD" 65250 "TCFG" 65253 "HOURS" 65254 "TD" 65255 "VH" 65256 "VDS" 65257 "LFC1" 65258 "VW" 65259 "CI" 65260 "VI" 65261 "CCSS" 65284 "PB_DriversConsentOnPersonalData" 65376 "VehCfg" 65413 "PB_3CT" 65482 "PB_ID1" 65484 "PB_VNS" 65502 "Av2" 65520 "SCh" 65521 "DIS" 65524 "PB_IVA" ;
VAL_ 2565406487 Pgn_Ad_E8FF17 37120 "VLSI1" 40448 "DM29" 41216 "DM33" 41728 "DM31" 41984 "DM30" 47360 "PLLT(PlanListLifetime)" 47872 "PLD(PlanListDistance)" 49408 "DM21" 49664 "DM20" 49920 "DM22" 53504 "MaintBcIc" 54016 "DM19" 60928 "ACL" 61184 "STOD" 64342 "HVESP3CFG" 64344 "HVESP2CFG" 64346 "HVESP1CFG" 64529 "TGFI" 64579 "TCSI" 64582 "TSIS" 64583 "MTI" 64605 "HVESSCFG" 64606 "HVESSHIST" 64653 "PII" 64701 "A1SCRSI2" 64782 "AT1OGC2" 64784 "AT1IGC2" 64839 "TML" 64879 "EEC8" 64896 "DM28" 64905 "VDS2" 64906 "J2012" 64912 "AETC" 64920 "AT1HI1" 64949 "DM23" 64950 "DM24" 64951 "DM25" 64952 "DM26" 64953 "TPRI" 64965 "ECUID" 64981 "EEC5" 65039 "LC" 65099 "TCFG2" 65109 "GFD" 65127 "CCC" 65131 "DI" 65136 "CVW" 65144 "TP1" 65145 "TP2" 65146 "TP3" 65195 "ETC6" 65196 "EBC4" 65199 "GFC" 65201 "EH" 65202 "GFI1" 65203 "LFI1" 65208 "GTFI" 65212 "CBI" 65214 "EEC4" 65216 "SERV" 65219 "ETC5" 65221 "ETC4" 65223 "ETC3" 65227 "DM02" 65228 "DM03" 65229 "DM04" 65230 "DM05" 65231 "DM06" 65234 "DM10" 65235 "DM11" 65236 "DM12" 65242 "SOFT" 65244 "IO" 65248 "VD" 65250 "TCFG" 65253 "HOURS" 65254 "TD" 65255 "VH" 65256 "VDS" 65257 "LFC1" 65258 "VW" 65259 "CI" 65260 "VI" 65261 "CCSS" 65284 "PB_DriversConsentOnPersonalData" 65376 "VehCfg" 65413 "PB_3CT" 65482 "PB_ID1" 65484 "PB_VNS" 65502 "Av2" 65520 "SCh" 65521 "DIS" 65524 "PB_IVA" ;
VAL_ 2565406487 Pgn_Nack_E8FF17 37120 "VLSI1" 40448 "DM29" 41216 "DM33" 41728 "DM31" 41984 "DM30" 47360 "PLLT(PlanListLifetime)" 47872 "PLD(PlanListDistance)" 49408 "DM21" 49664 "DM20" 49920 "DM22" 53504 "MaintBcIc" 54016 "DM19" 60928 "ACL" 61184 "STOD" 64342 "HVESP3CFG" 64344 "HVESP2CFG" 64346 "HVESP1CFG" 64529 "TGFI" 64579 "TCSI" 64582 "TSIS" 64583 "MTI" 64605 "HVESSCFG" 64606 "HVESSHIST" 64653 "PII" 64701 "A1SCRSI2" 64782 "AT1OGC2" 64784 "AT1IGC2" 64839 "TML" 64879 "EEC8" 64896 "DM28" 64905 "VDS2" 64906 "J2012" 64912 "AETC" 64920 "AT1HI1" 64949 "DM23" 64950 "DM24" 64951 "DM25" 64952 "DM26" 64953 "TPRI" 64965 "ECUID" 64981 "EEC5" 65039 "LC" 65099 "TCFG2" 65109 "GFD" 65127 "CCC" 65131 "DI" 65136 "CVW" 65144 "TP1" 65145 "TP2" 65146 "TP3" 65195 "ETC6" 65196 "EBC4" 65199 "GFC" 65201 "EH" 65202 "GFI1" 65203 "LFI1" 65208 "GTFI" 65212 "CBI" 65214 "EEC4" 65216 "SERV" 65219 "ETC5" 65221 "ETC4" 65223 "ETC3" 65227 "DM02" 65228 "DM03" 65229 "DM04" 65230 "DM05" 65231 "DM06" 65234 "DM10" 65235 "DM11" 65236 "DM12" 65242 "SOFT" 65244 "IO" 65248 "VD" 65250 "TCFG" 65253 "HOURS" 65254 "TD" 65255 "VH" 65256 "VDS" 65257 "LFC1" 65258 "VW" 65259 "CI" 65260 "VI" 65261 "CCSS" 65284 "PB_DriversConsentOnPersonalData" 65376 "VehCfg" 65413 "PB_3CT" 65482 "PB_ID1" 65484 "PB_VNS" 65502 "Av2" 65520 "SCh" 65521 "DIS" 65524 "PB_IVA" ;
VAL_ 2565406487 Pgn_Ack_E8FF17 37120 "VLSI1" 40448 "DM29" 41216 "DM33" 41728 "DM31" 41984 "DM30" 47360 "PLLT(PlanListLifetime)" 47872 "PLD(PlanListDistance)" 49408 "DM21" 49664 "DM20" 49920 "DM22" 53504 "MaintBcIc" 54016 "DM19" 60928 "ACL" 61184 "STOD" 64342 "HVESP3CFG" 64344 "HVESP2CFG" 64346 "HVESP1CFG" 64529 "TGFI" 64579 "TCSI" 64582 "TSIS" 64583 "MTI" 64605 "HVESSCFG" 64606 "HVESSHIST" 64653 "PII" 64701 "A1SCRSI2" 64782 "AT1OGC2" 64784 "AT1IGC2" 64839 "TML" 64879 "EEC8" 64896 "DM28" 64905 "VDS2" 64906 "J2012" 64912 "AETC" 64920 "AT1HI1" 64949 "DM23" 64950 "DM24" 64951 "DM25" 64952 "DM26" 64953 "TPRI" 64965 "ECUID" 64981 "EEC5" 65039 "LC" 65099 "TCFG2" 65109 "GFD" 65127 "CCC" 65131 "DI" 65136 "CVW" 65144 "TP1" 65145 "TP2" 65146 "TP3" 65195 "ETC6" 65196 "EBC4" 65199 "GFC" 65201 "EH" 65202 "GFI1" 65203 "LFI1" 65208 "GTFI" 65212 "CBI" 65214 "EEC4" 65216 "SERV" 65219 "ETC5" 65221 "ETC4" 65223 "ETC3" 65227 "DM02" 65228 "DM03" 65229 "DM04" 65230 "DM05" 65231 "DM06" 65234 "DM10" 65235 "DM11" 65236 "DM12" 65242 "SOFT" 65244 "IO" 65248 "VD" 65250 "TCFG" 65253 "HOURS" 65254 "TD" 65255 "VH" 65256 "VDS" 65257 "LFC1" 65258 "VW" 65259 "CI" 65260 "VI" 65261 "CCSS" 65284 "PB_DriversConsentOnPersonalData" 65376 "VehCfg" 65413 "PB_3CT" 65482 "PB_ID1" 65484 "PB_VNS" 65502 "Av2" 65520 "SCh" 65521 "DIS" 65524 "PB_IVA" ;
VAL_ 2565406487 CtrlByte_Ackm_E8FF17 0 "ACK" 1 "NACK" 2 "Access Denied" 3 "Cannot Respond" ;
VAL_ 2565406492 Pgn_Busy_E8FF1C 37120 "VLSI1" 40448 "DM29" 41216 "DM33" 41728 "DM31" 41984 "DM30" 47360 "PLLT(PlanListLifetime)" 47872 "PLD(PlanListDistance)" 49408 "DM21" 49664 "DM20" 49920 "DM22" 53504 "MaintBcIc" 54016 "DM19" 60928 "ACL" 61184 "STOD" 64342 "HVESP3CFG" 64344 "HVESP2CFG" 64346 "HVESP1CFG" 64529 "TGFI" 64579 "TCSI" 64582 "TSIS" 64583 "MTI" 64605 "HVESSCFG" 64606 "HVESSHIST" 64653 "PII" 64701 "A1SCRSI2" 64782 "AT1OGC2" 64784 "AT1IGC2" 64839 "TML" 64879 "EEC8" 64896 "DM28" 64905 "VDS2" 64906 "J2012" 64912 "AETC" 64920 "AT1HI1" 64949 "DM23" 64950 "DM24" 64951 "DM25" 64952 "DM26" 64953 "TPRI" 64965 "ECUID" 64981 "EEC5" 65039 "LC" 65099 "TCFG2" 65109 "GFD" 65127 "CCC" 65131 "DI" 65136 "CVW" 65144 "TP1" 65145 "TP2" 65146 "TP3" 65195 "ETC6" 65196 "EBC4" 65199 "GFC" 65201 "EH" 65202 "GFI1" 65203 "LFI1" 65208 "GTFI" 65212 "CBI" 65214 "EEC4" 65216 "SERV" 65219 "ETC5" 65221 "ETC4" 65223 "ETC3" 65227 "DM02" 65228 "DM03" 65229 "DM04" 65230 "DM05" 65231 "DM06" 65234 "DM10" 65235 "DM11" 65236 "DM12" 65242 "SOFT" 65244 "IO" 65248 "VD" 65250 "TCFG" 65253 "HOURS" 65254 "TD" 65255 "VH" 65256 "VDS" 65257 "LFC1" 65258 "VW" 65259 "CI" 65260 "VI" 65261 "CCSS" 65284 "PB_DriversConsentOnPersonalData" 65376 "VehCfg" 65413 "PB_3CT" 65482 "PB_ID1" 65484 "PB_VNS" 65502 "Av2" 65520 "SCh" 65521 "DIS" 65524 "PB_IVA" ;
VAL_ 2565406492 Pgn_Ad_E8FF1C 37120 "VLSI1" 40448 "DM29" 41216 "DM33" 41728 "DM31" 41984 "DM30" 47360 "PLLT(PlanListLifetime)" 47872 "PLD(PlanListDistance)" 49408 "DM21" 49664 "DM20" 49920 "DM22" 53504 "MaintBcIc" 54016 "DM19" 60928 "ACL" 61184 "STOD" 64342 "HVESP3CFG" 64344 "HVESP2CFG" 64346 "HVESP1CFG" 64529 "TGFI" 64579 "TCSI" 64582 "TSIS" 64583 "MTI" 64605 "HVESSCFG" 64606 "HVESSHIST" 64653 "PII" 64701 "A1SCRSI2" 64782 "AT1OGC2" 64784 "AT1IGC2" 64839 "TML" 64879 "EEC8" 64896 "DM28" 64905 "VDS2" 64906 "J2012" 64912 "AETC" 64920 "AT1HI1" 64949 "DM23" 64950 "DM24" 64951 "DM25" 64952 "DM26" 64953 "TPRI" 64965 "ECUID" 64981 "EEC5" 65039 "LC" 65099 "TCFG2" 65109 "GFD" 65127 "CCC" 65131 "DI" 65136 "CVW" 65144 "TP1" 65145 "TP2" 65146 "TP3" 65195 "ETC6" 65196 "EBC4" 65199 "GFC" 65201 "EH" 65202 "GFI1" 65203 "LFI1" 65208 "GTFI" 65212 "CBI" 65214 "EEC4" 65216 "SERV" 65219 "ETC5" 65221 "ETC4" 65223 "ETC3" 65227 "DM02" 65228 "DM03" 65229 "DM04" 65230 "DM05" 65231 "DM06" 65234 "DM10" 65235 "DM11" 65236 "DM12" 65242 "SOFT" 65244 "IO" 65248 "VD" 65250 "TCFG" 65253 "HOURS" 65254 "TD" 65255 "VH" 65256 "VDS" 65257 "LFC1" 65258 "VW" 65259 "CI" 65260 "VI" 65261 "CCSS" 65284 "PB_DriversConsentOnPersonalData" 65376 "VehCfg" 65413 "PB_3CT" 65482 "PB_ID1" 65484 "PB_VNS" 65502 "Av2" 65520 "SCh" 65521 "DIS" 65524 "PB_IVA" ;
VAL_ 2565406492 Pgn_Nack_E8FF1C 37120 "VLSI1" 40448 "DM29" 41216 "DM33" 41728 "DM31" 41984 "DM30" 47360 "PLLT(PlanListLifetime)" 47872 "PLD(PlanListDistance)" 49408 "DM21" 49664 "DM20" 49920 "DM22" 53504 "MaintBcIc" 54016 "DM19" 60928 "ACL" 61184 "STOD" 64342 "HVESP3CFG" 64344 "HVESP2CFG" 64346 "HVESP1CFG" 64529 "TGFI" 64579 "TCSI" 64582 "TSIS" 64583 "MTI" 64605 "HVESSCFG" 64606 "HVESSHIST" 64653 "PII" 64701 "A1SCRSI2" 64782 "AT1OGC2" 64784 "AT1IGC2" 64839 "TML" 64879 "EEC8" 64896 "DM28" 64905 "VDS2" 64906 "J2012" 64912 "AETC" 64920 "AT1HI1" 64949 "DM23" 64950 "DM24" 64951 "DM25" 64952 "DM26" 64953 "TPRI" 64965 "ECUID" 64981 "EEC5" 65039 "LC" 65099 "TCFG2" 65109 "GFD" 65127 "CCC" 65131 "DI" 65136 "CVW" 65144 "TP1" 65145 "TP2" 65146 "TP3" 65195 "ETC6" 65196 "EBC4" 65199 "GFC" 65201 "EH" 65202 "GFI1" 65203 "LFI1" 65208 "GTFI" 65212 "CBI" 65214 "EEC4" 65216 "SERV" 65219 "ETC5" 65221 "ETC4" 65223 "ETC3" 65227 "DM02" 65228 "DM03" 65229 "DM04" 65230 "DM05" 65231 "DM06" 65234 "DM10" 65235 "DM11" 65236 "DM12" 65242 "SOFT" 65244 "IO" 65248 "VD" 65250 "TCFG" 65253 "HOURS" 65254 "TD" 65255 "VH" 65256 "VDS" 65257 "LFC1" 65258 "VW" 65259 "CI" 65260 "VI" 65261 "CCSS" 65284 "PB_DriversConsentOnPersonalData" 65376 "VehCfg" 65413 "PB_3CT" 65482 "PB_ID1" 65484 "PB_VNS" 65502 "Av2" 65520 "SCh" 65521 "DIS" 65524 "PB_IVA" ;
VAL_ 2565406492 Pgn_Ack_E8FF1C 37120 "VLSI1" 40448 "DM29" 41216 "DM33" 41728 "DM31" 41984 "DM30" 47360 "PLLT(PlanListLifetime)" 47872 "PLD(PlanListDistance)" 49408 "DM21" 49664 "DM20" 49920 "DM22" 53504 "MaintBcIc" 54016 "DM19" 60928 "ACL" 61184 "STOD" 64342 "HVESP3CFG" 64344 "HVESP2CFG" 64346 "HVESP1CFG" 64529 "TGFI" 64579 "TCSI" 64582 "TSIS" 64583 "MTI" 64605 "HVESSCFG" 64606 "HVESSHIST" 64653 "PII" 64701 "A1SCRSI2" 64782 "AT1OGC2" 64784 "AT1IGC2" 64839 "TML" 64879 "EEC8" 64896 "DM28" 64905 "VDS2" 64906 "J2012" 64912 "AETC" 64920 "AT1HI1" 64949 "DM23" 64950 "DM24" 64951 "DM25" 64952 "DM26" 64953 "TPRI" 64965 "ECUID" 64981 "EEC5" 65039 "LC" 65099 "TCFG2" 65109 "GFD" 65127 "CCC" 65131 "DI" 65136 "CVW" 65144 "TP1" 65145 "TP2" 65146 "TP3" 65195 "ETC6" 65196 "EBC4" 65199 "GFC" 65201 "EH" 65202 "GFI1" 65203 "LFI1" 65208 "GTFI" 65212 "CBI" 65214 "EEC4" 65216 "SERV" 65219 "ETC5" 65221 "ETC4" 65223 "ETC3" 65227 "DM02" 65228 "DM03" 65229 "DM04" 65230 "DM05" 65231 "DM06" 65234 "DM10" 65235 "DM11" 65236 "DM12" 65242 "SOFT" 65244 "IO" 65248 "VD" 65250 "TCFG" 65253 "HOURS" 65254 "TD" 65255 "VH" 65256 "VDS" 65257 "LFC1" 65258 "VW" 65259 "CI" 65260 "VI" 65261 "CCSS" 65284 "PB_DriversConsentOnPersonalData" 65376 "VehCfg" 65413 "PB_3CT" 65482 "PB_ID1" 65484 "PB_VNS" 65502 "Av2" 65520 "SCh" 65521 "DIS" 65524 "PB_IVA" ;
VAL_ 2565406492 CtrlByte_Ackm_E8FF1C 0 "ACK" 1 "NACK" 2 "Access Denied" 3 "Cannot Respond" ;
VAL_ 2565406493 Pgn_Busy_E8FF1D 37120 "VLSI1" 40448 "DM29" 41216 "DM33" 41728 "DM31" 41984 "DM30" 47360 "PLLT(PlanListLifetime)" 47872 "PLD(PlanListDistance)" 49408 "DM21" 49664 "DM20" 49920 "DM22" 53504 "MaintBcIc" 54016 "DM19" 60928 "ACL" 61184 "STOD" 64342 "HVESP3CFG" 64344 "HVESP2CFG" 64346 "HVESP1CFG" 64529 "TGFI" 64579 "TCSI" 64582 "TSIS" 64583 "MTI" 64605 "HVESSCFG" 64606 "HVESSHIST" 64653 "PII" 64701 "A1SCRSI2" 64782 "AT1OGC2" 64784 "AT1IGC2" 64839 "TML" 64879 "EEC8" 64896 "DM28" 64905 "VDS2" 64906 "J2012" 64912 "AETC" 64920 "AT1HI1" 64949 "DM23" 64950 "DM24" 64951 "DM25" 64952 "DM26" 64953 "TPRI" 64965 "ECUID" 64981 "EEC5" 65039 "LC" 65099 "TCFG2" 65109 "GFD" 65127 "CCC" 65131 "DI" 65136 "CVW" 65144 "TP1" 65145 "TP2" 65146 "TP3" 65195 "ETC6" 65196 "EBC4" 65199 "GFC" 65201 "EH" 65202 "GFI1" 65203 "LFI1" 65208 "GTFI" 65212 "CBI" 65214 "EEC4" 65216 "SERV" 65219 "ETC5" 65221 "ETC4" 65223 "ETC3" 65227 "DM02" 65228 "DM03" 65229 "DM04" 65230 "DM05" 65231 "DM06" 65234 "DM10" 65235 "DM11" 65236 "DM12" 65242 "SOFT" 65244 "IO" 65248 "VD" 65250 "TCFG" 65253 "HOURS" 65254 "TD" 65255 "VH" 65256 "VDS" 65257 "LFC1" 65258 "VW" 65259 "CI" 65260 "VI" 65261 "CCSS" 65284 "PB_DriversConsentOnPersonalData" 65376 "VehCfg" 65413 "PB_3CT" 65482 "PB_ID1" 65484 "PB_VNS" 65502 "Av2" 65520 "SCh" 65521 "DIS" 65524 "PB_IVA" ;
VAL_ 2565406493 Pgn_Ad_E8FF1D 37120 "VLSI1" 40448 "DM29" 41216 "DM33" 41728 "DM31" 41984 "DM30" 47360 "PLLT(PlanListLifetime)" 47872 "PLD(PlanListDistance)" 49408 "DM21" 49664 "DM20" 49920 "DM22" 53504 "MaintBcIc" 54016 "DM19" 60928 "ACL" 61184 "STOD" 64342 "HVESP3CFG" 64344 "HVESP2CFG" 64346 "HVESP1CFG" 64529 "TGFI" 64579 "TCSI" 64582 "TSIS" 64583 "MTI" 64605 "HVESSCFG" 64606 "HVESSHIST" 64653 "PII" 64701 "A1SCRSI2" 64782 "AT1OGC2" 64784 "AT1IGC2" 64839 "TML" 64879 "EEC8" 64896 "DM28" 64905 "VDS2" 64906 "J2012" 64912 "AETC" 64920 "AT1HI1" 64949 "DM23" 64950 "DM24" 64951 "DM25" 64952 "DM26" 64953 "TPRI" 64965 "ECUID" 64981 "EEC5" 65039 "LC" 65099 "TCFG2" 65109 "GFD" 65127 "CCC" 65131 "DI" 65136 "CVW" 65144 "TP1" 65145 "TP2" 65146 "TP3" 65195 "ETC6" 65196 "EBC4" 65199 "GFC" 65201 "EH" 65202 "GFI1" 65203 "LFI1" 65208 "GTFI" 65212 "CBI" 65214 "EEC4" 65216 "SERV" 65219 "ETC5" 65221 "ETC4" 65223 "ETC3" 65227 "DM02" 65228 "DM03" 65229 "DM04" 65230 "DM05" 65231 "DM06" 65234 "DM10" 65235 "DM11" 65236 "DM12" 65242 "SOFT" 65244 "IO" 65248 "VD" 65250 "TCFG" 65253 "HOURS" 65254 "TD" 65255 "VH" 65256 "VDS" 65257 "LFC1" 65258 "VW" 65259 "CI" 65260 "VI" 65261 "CCSS" 65284 "PB_DriversConsentOnPersonalData" 65376 "VehCfg" 65413 "PB_3CT" 65482 "PB_ID1" 65484 "PB_VNS" 65502 "Av2" 65520 "SCh" 65521 "DIS" 65524 "PB_IVA" ;
VAL_ 2565406493 Pgn_Nack_E8FF1D 37120 "VLSI1" 40448 "DM29" 41216 "DM33" 41728 "DM31" 41984 "DM30" 47360 "PLLT(PlanListLifetime)" 47872 "PLD(PlanListDistance)" 49408 "DM21" 49664 "DM20" 49920 "DM22" 53504 "MaintBcIc" 54016 "DM19" 60928 "ACL" 61184 "STOD" 64342 "HVESP3CFG" 64344 "HVESP2CFG" 64346 "HVESP1CFG" 64529 "TGFI" 64579 "TCSI" 64582 "TSIS" 64583 "MTI" 64605 "HVESSCFG" 64606 "HVESSHIST" 64653 "PII" 64701 "A1SCRSI2" 64782 "AT1OGC2" 64784 "AT1IGC2" 64839 "TML" 64879 "EEC8" 64896 "DM28" 64905 "VDS2" 64906 "J2012" 64912 "AETC" 64920 "AT1HI1" 64949 "DM23" 64950 "DM24" 64951 "DM25" 64952 "DM26" 64953 "TPRI" 64965 "ECUID" 64981 "EEC5" 65039 "LC" 65099 "TCFG2" 65109 "GFD" 65127 "CCC" 65131 "DI" 65136 "CVW" 65144 "TP1" 65145 "TP2" 65146 "TP3" 65195 "ETC6" 65196 "EBC4" 65199 "GFC" 65201 "EH" 65202 "GFI1" 65203 "LFI1" 65208 "GTFI" 65212 "CBI" 65214 "EEC4" 65216 "SERV" 65219 "ETC5" 65221 "ETC4" 65223 "ETC3" 65227 "DM02" 65228 "DM03" 65229 "DM04" 65230 "DM05" 65231 "DM06" 65234 "DM10" 65235 "DM11" 65236 "DM12" 65242 "SOFT" 65244 "IO" 65248 "VD" 65250 "TCFG" 65253 "HOURS" 65254 "TD" 65255 "VH" 65256 "VDS" 65257 "LFC1" 65258 "VW" 65259 "CI" 65260 "VI" 65261 "CCSS" 65284 "PB_DriversConsentOnPersonalData" 65376 "VehCfg" 65413 "PB_3CT" 65482 "PB_ID1" 65484 "PB_VNS" 65502 "Av2" 65520 "SCh" 65521 "DIS" 65524 "PB_IVA" ;
VAL_ 2565406493 Pgn_Ack_E8FF1D 37120 "VLSI1" 40448 "DM29" 41216 "DM33" 41728 "DM31" 41984 "DM30" 47360 "PLLT(PlanListLifetime)" 47872 "PLD(PlanListDistance)" 49408 "DM21" 49664 "DM20" 49920 "DM22" 53504 "MaintBcIc" 54016 "DM19" 60928 "ACL" 61184 "STOD" 64342 "HVESP3CFG" 64344 "HVESP2CFG" 64346 "HVESP1CFG" 64529 "TGFI" 64579 "TCSI" 64582 "TSIS" 64583 "MTI" 64605 "HVESSCFG" 64606 "HVESSHIST" 64653 "PII" 64701 "A1SCRSI2" 64782 "AT1OGC2" 64784 "AT1IGC2" 64839 "TML" 64879 "EEC8" 64896 "DM28" 64905 "VDS2" 64906 "J2012" 64912 "AETC" 64920 "AT1HI1" 64949 "DM23" 64950 "DM24" 64951 "DM25" 64952 "DM26" 64953 "TPRI" 64965 "ECUID" 64981 "EEC5" 65039 "LC" 65099 "TCFG2" 65109 "GFD" 65127 "CCC" 65131 "DI" 65136 "CVW" 65144 "TP1" 65145 "TP2" 65146 "TP3" 65195 "ETC6" 65196 "EBC4" 65199 "GFC" 65201 "EH" 65202 "GFI1" 65203 "LFI1" 65208 "GTFI" 65212 "CBI" 65214 "EEC4" 65216 "SERV" 65219 "ETC5" 65221 "ETC4" 65223 "ETC3" 65227 "DM02" 65228 "DM03" 65229 "DM04" 65230 "DM05" 65231 "DM06" 65234 "DM10" 65235 "DM11" 65236 "DM12" 65242 "SOFT" 65244 "IO" 65248 "VD" 65250 "TCFG" 65253 "HOURS" 65254 "TD" 65255 "VH" 65256 "VDS" 65257 "LFC1" 65258 "VW" 65259 "CI" 65260 "VI" 65261 "CCSS" 65284 "PB_DriversConsentOnPersonalData" 65376 "VehCfg" 65413 "PB_3CT" 65482 "PB_ID1" 65484 "PB_VNS" 65502 "Av2" 65520 "SCh" 65521 "DIS" 65524 "PB_IVA" ;
VAL_ 2565406493 CtrlByte_Ackm_E8FF1D 0 "ACK" 1 "NACK" 2 "Access Denied" 3 "Cannot Respond" ;
VAL_ 2565406503 Pgn_Busy_E8FF27 37120 "VLSI1" 40448 "DM29" 41216 "DM33" 41728 "DM31" 41984 "DM30" 47360 "PLLT(PlanListLifetime)" 47872 "PLD(PlanListDistance)" 49408 "DM21" 49664 "DM20" 49920 "DM22" 53504 "MaintBcIc" 54016 "DM19" 60928 "ACL" 61184 "STOD" 64342 "HVESP3CFG" 64344 "HVESP2CFG" 64346 "HVESP1CFG" 64529 "TGFI" 64579 "TCSI" 64582 "TSIS" 64583 "MTI" 64605 "HVESSCFG" 64606 "HVESSHIST" 64653 "PII" 64701 "A1SCRSI2" 64782 "AT1OGC2" 64784 "AT1IGC2" 64839 "TML" 64879 "EEC8" 64896 "DM28" 64905 "VDS2" 64906 "J2012" 64912 "AETC" 64920 "AT1HI1" 64949 "DM23" 64950 "DM24" 64951 "DM25" 64952 "DM26" 64953 "TPRI" 64965 "ECUID" 64981 "EEC5" 65039 "LC" 65099 "TCFG2" 65109 "GFD" 65127 "CCC" 65131 "DI" 65136 "CVW" 65144 "TP1" 65145 "TP2" 65146 "TP3" 65195 "ETC6" 65196 "EBC4" 65199 "GFC" 65201 "EH" 65202 "GFI1" 65203 "LFI1" 65208 "GTFI" 65212 "CBI" 65214 "EEC4" 65216 "SERV" 65219 "ETC5" 65221 "ETC4" 65223 "ETC3" 65227 "DM02" 65228 "DM03" 65229 "DM04" 65230 "DM05" 65231 "DM06" 65234 "DM10" 65235 "DM11" 65236 "DM12" 65242 "SOFT" 65244 "IO" 65248 "VD" 65250 "TCFG" 65253 "HOURS" 65254 "TD" 65255 "VH" 65256 "VDS" 65257 "LFC1" 65258 "VW" 65259 "CI" 65260 "VI" 65261 "CCSS" 65284 "PB_DriversConsentOnPersonalData" 65376 "VehCfg" 65413 "PB_3CT" 65482 "PB_ID1" 65484 "PB_VNS" 65502 "Av2" 65520 "SCh" 65521 "DIS" 65524 "PB_IVA" ;
VAL_ 2565406503 Pgn_Ad_E8FF27 37120 "VLSI1" 40448 "DM29" 41216 "DM33" 41728 "DM31" 41984 "DM30" 47360 "PLLT(PlanListLifetime)" 47872 "PLD(PlanListDistance)" 49408 "DM21" 49664 "DM20" 49920 "DM22" 53504 "MaintBcIc" 54016 "DM19" 60928 "ACL" 61184 "STOD" 64342 "HVESP3CFG" 64344 "HVESP2CFG" 64346 "HVESP1CFG" 64529 "TGFI" 64579 "TCSI" 64582 "TSIS" 64583 "MTI" 64605 "HVESSCFG" 64606 "HVESSHIST" 64653 "PII" 64701 "A1SCRSI2" 64782 "AT1OGC2" 64784 "AT1IGC2" 64839 "TML" 64879 "EEC8" 64896 "DM28" 64905 "VDS2" 64906 "J2012" 64912 "AETC" 64920 "AT1HI1" 64949 "DM23" 64950 "DM24" 64951 "DM25" 64952 "DM26" 64953 "TPRI" 64965 "ECUID" 64981 "EEC5" 65039 "LC" 65099 "TCFG2" 65109 "GFD" 65127 "CCC" 65131 "DI" 65136 "CVW" 65144 "TP1" 65145 "TP2" 65146 "TP3" 65195 "ETC6" 65196 "EBC4" 65199 "GFC" 65201 "EH" 65202 "GFI1" 65203 "LFI1" 65208 "GTFI" 65212 "CBI" 65214 "EEC4" 65216 "SERV" 65219 "ETC5" 65221 "ETC4" 65223 "ETC3" 65227 "DM02" 65228 "DM03" 65229 "DM04" 65230 "DM05" 65231 "DM06" 65234 "DM10" 65235 "DM11" 65236 "DM12" 65242 "SOFT" 65244 "IO" 65248 "VD" 65250 "TCFG" 65253 "HOURS" 65254 "TD" 65255 "VH" 65256 "VDS" 65257 "LFC1" 65258 "VW" 65259 "CI" 65260 "VI" 65261 "CCSS" 65284 "PB_DriversConsentOnPersonalData" 65376 "VehCfg" 65413 "PB_3CT" 65482 "PB_ID1" 65484 "PB_VNS" 65502 "Av2" 65520 "SCh" 65521 "DIS" 65524 "PB_IVA" ;
VAL_ 2565406503 Pgn_Nack_E8FF27 37120 "VLSI1" 40448 "DM29" 41216 "DM33" 41728 "DM31" 41984 "DM30" 47360 "PLLT(PlanListLifetime)" 47872 "PLD(PlanListDistance)" 49408 "DM21" 49664 "DM20" 49920 "DM22" 53504 "MaintBcIc" 54016 "DM19" 60928 "ACL" 61184 "STOD" 64342 "HVESP3CFG" 64344 "HVESP2CFG" 64346 "HVESP1CFG" 64529 "TGFI" 64579 "TCSI" 64582 "TSIS" 64583 "MTI" 64605 "HVESSCFG" 64606 "HVESSHIST" 64653 "PII" 64701 "A1SCRSI2" 64782 "AT1OGC2" 64784 "AT1IGC2" 64839 "TML" 64879 "EEC8" 64896 "DM28" 64905 "VDS2" 64906 "J2012" 64912 "AETC" 64920 "AT1HI1" 64949 "DM23" 64950 "DM24" 64951 "DM25" 64952 "DM26" 64953 "TPRI" 64965 "ECUID" 64981 "EEC5" 65039 "LC" 65099 "TCFG2" 65109 "GFD" 65127 "CCC" 65131 "DI" 65136 "CVW" 65144 "TP1" 65145 "TP2" 65146 "TP3" 65195 "ETC6" 65196 "EBC4" 65199 "GFC" 65201 "EH" 65202 "GFI1" 65203 "LFI1" 65208 "GTFI" 65212 "CBI" 65214 "EEC4" 65216 "SERV" 65219 "ETC5" 65221 "ETC4" 65223 "ETC3" 65227 "DM02" 65228 "DM03" 65229 "DM04" 65230 "DM05" 65231 "DM06" 65234 "DM10" 65235 "DM11" 65236 "DM12" 65242 "SOFT" 65244 "IO" 65248 "VD" 65250 "TCFG" 65253 "HOURS" 65254 "TD" 65255 "VH" 65256 "VDS" 65257 "LFC1" 65258 "VW" 65259 "CI" 65260 "VI" 65261 "CCSS" 65284 "PB_DriversConsentOnPersonalData" 65376 "VehCfg" 65413 "PB_3CT" 65482 "PB_ID1" 65484 "PB_VNS" 65502 "Av2" 65520 "SCh" 65521 "DIS" 65524 "PB_IVA" ;
VAL_ 2565406503 Pgn_Ack_E8FF27 37120 "VLSI1" 40448 "DM29" 41216 "DM33" 41728 "DM31" 41984 "DM30" 47360 "PLLT(PlanListLifetime)" 47872 "PLD(PlanListDistance)" 49408 "DM21" 49664 "DM20" 49920 "DM22" 53504 "MaintBcIc" 54016 "DM19" 60928 "ACL" 61184 "STOD" 64342 "HVESP3CFG" 64344 "HVESP2CFG" 64346 "HVESP1CFG" 64529 "TGFI" 64579 "TCSI" 64582 "TSIS" 64583 "MTI" 64605 "HVESSCFG" 64606 "HVESSHIST" 64653 "PII" 64701 "A1SCRSI2" 64782 "AT1OGC2" 64784 "AT1IGC2" 64839 "TML" 64879 "EEC8" 64896 "DM28" 64905 "VDS2" 64906 "J2012" 64912 "AETC" 64920 "AT1HI1" 64949 "DM23" 64950 "DM24" 64951 "DM25" 64952 "DM26" 64953 "TPRI" 64965 "ECUID" 64981 "EEC5" 65039 "LC" 65099 "TCFG2" 65109 "GFD" 65127 "CCC" 65131 "DI" 65136 "CVW" 65144 "TP1" 65145 "TP2" 65146 "TP3" 65195 "ETC6" 65196 "EBC4" 65199 "GFC" 65201 "EH" 65202 "GFI1" 65203 "LFI1" 65208 "GTFI" 65212 "CBI" 65214 "EEC4" 65216 "SERV" 65219 "ETC5" 65221 "ETC4" 65223 "ETC3" 65227 "DM02" 65228 "DM03" 65229 "DM04" 65230 "DM05" 65231 "DM06" 65234 "DM10" 65235 "DM11" 65236 "DM12" 65242 "SOFT" 65244 "IO" 65248 "VD" 65250 "TCFG" 65253 "HOURS" 65254 "TD" 65255 "VH" 65256 "VDS" 65257 "LFC1" 65258 "VW" 65259 "CI" 65260 "VI" 65261 "CCSS" 65284 "PB_DriversConsentOnPersonalData" 65376 "VehCfg" 65413 "PB_3CT" 65482 "PB_ID1" 65484 "PB_VNS" 65502 "Av2" 65520 "SCh" 65521 "DIS" 65524 "PB_IVA" ;
VAL_ 2565406503 CtrlByte_Ackm_E8FF27 0 "ACK" 1 "NACK" 2 "Access Denied" 3 "Cannot Respond" ;
VAL_ 2565406515 Pgn_Busy_E8FF33 37120 "VLSI1" 40448 "DM29" 41216 "DM33" 41728 "DM31" 41984 "DM30" 47360 "PLLT(PlanListLifetime)" 47872 "PLD(PlanListDistance)" 49408 "DM21" 49664 "DM20" 49920 "DM22" 53504 "MaintBcIc" 54016 "DM19" 60928 "ACL" 61184 "STOD" 64342 "HVESP3CFG" 64344 "HVESP2CFG" 64346 "HVESP1CFG" 64529 "TGFI" 64579 "TCSI" 64582 "TSIS" 64583 "MTI" 64605 "HVESSCFG" 64606 "HVESSHIST" 64653 "PII" 64701 "A1SCRSI2" 64782 "AT1OGC2" 64784 "AT1IGC2" 64839 "TML" 64879 "EEC8" 64896 "DM28" 64905 "VDS2" 64906 "J2012" 64912 "AETC" 64920 "AT1HI1" 64949 "DM23" 64950 "DM24" 64951 "DM25" 64952 "DM26" 64953 "TPRI" 64965 "ECUID" 64981 "EEC5" 65039 "LC" 65099 "TCFG2" 65109 "GFD" 65127 "CCC" 65131 "DI" 65136 "CVW" 65144 "TP1" 65145 "TP2" 65146 "TP3" 65195 "ETC6" 65196 "EBC4" 65199 "GFC" 65201 "EH" 65202 "GFI1" 65203 "LFI1" 65208 "GTFI" 65212 "CBI" 65214 "EEC4" 65216 "SERV" 65219 "ETC5" 65221 "ETC4" 65223 "ETC3" 65227 "DM02" 65228 "DM03" 65229 "DM04" 65230 "DM05" 65231 "DM06" 65234 "DM10" 65235 "DM11" 65236 "DM12" 65242 "SOFT" 65244 "IO" 65248 "VD" 65250 "TCFG" 65253 "HOURS" 65254 "TD" 65255 "VH" 65256 "VDS" 65257 "LFC1" 65258 "VW" 65259 "CI" 65260 "VI" 65261 "CCSS" 65284 "PB_DriversConsentOnPersonalData" 65376 "VehCfg" 65413 "PB_3CT" 65482 "PB_ID1" 65484 "PB_VNS" 65502 "Av2" 65520 "SCh" 65521 "DIS" 65524 "PB_IVA" ;
VAL_ 2565406515 Pgn_Ad_E8FF33 37120 "VLSI1" 40448 "DM29" 41216 "DM33" 41728 "DM31" 41984 "DM30" 47360 "PLLT(PlanListLifetime)" 47872 "PLD(PlanListDistance)" 49408 "DM21" 49664 "DM20" 49920 "DM22" 53504 "MaintBcIc" 54016 "DM19" 60928 "ACL" 61184 "STOD" 64342 "HVESP3CFG" 64344 "HVESP2CFG" 64346 "HVESP1CFG" 64529 "TGFI" 64579 "TCSI" 64582 "TSIS" 64583 "MTI" 64605 "HVESSCFG" 64606 "HVESSHIST" 64653 "PII" 64701 "A1SCRSI2" 64782 "AT1OGC2" 64784 "AT1IGC2" 64839 "TML" 64879 "EEC8" 64896 "DM28" 64905 "VDS2" 64906 "J2012" 64912 "AETC" 64920 "AT1HI1" 64949 "DM23" 64950 "DM24" 64951 "DM25" 64952 "DM26" 64953 "TPRI" 64965 "ECUID" 64981 "EEC5" 65039 "LC" 65099 "TCFG2" 65109 "GFD" 65127 "CCC" 65131 "DI" 65136 "CVW" 65144 "TP1" 65145 "TP2" 65146 "TP3" 65195 "ETC6" 65196 "EBC4" 65199 "GFC" 65201 "EH" 65202 "GFI1" 65203 "LFI1" 65208 "GTFI" 65212 "CBI" 65214 "EEC4" 65216 "SERV" 65219 "ETC5" 65221 "ETC4" 65223 "ETC3" 65227 "DM02" 65228 "DM03" 65229 "DM04" 65230 "DM05" 65231 "DM06" 65234 "DM10" 65235 "DM11" 65236 "DM12" 65242 "SOFT" 65244 "IO" 65248 "VD" 65250 "TCFG" 65253 "HOURS" 65254 "TD" 65255 "VH" 65256 "VDS" 65257 "LFC1" 65258 "VW" 65259 "CI" 65260 "VI" 65261 "CCSS" 65284 "PB_DriversConsentOnPersonalData" 65376 "VehCfg" 65413 "PB_3CT" 65482 "PB_ID1" 65484 "PB_VNS" 65502 "Av2" 65520 "SCh" 65521 "DIS" 65524 "PB_IVA" ;
VAL_ 2565406515 Pgn_Nack_E8FF33 37120 "VLSI1" 40448 "DM29" 41216 "DM33" 41728 "DM31" 41984 "DM30" 47360 "PLLT(PlanListLifetime)" 47872 "PLD(PlanListDistance)" 49408 "DM21" 49664 "DM20" 49920 "DM22" 53504 "MaintBcIc" 54016 "DM19" 60928 "ACL" 61184 "STOD" 64342 "HVESP3CFG" 64344 "HVESP2CFG" 64346 "HVESP1CFG" 64529 "TGFI" 64579 "TCSI" 64582 "TSIS" 64583 "MTI" 64605 "HVESSCFG" 64606 "HVESSHIST" 64653 "PII" 64701 "A1SCRSI2" 64782 "AT1OGC2" 64784 "AT1IGC2" 64839 "TML" 64879 "EEC8" 64896 "DM28" 64905 "VDS2" 64906 "J2012" 64912 "AETC" 64920 "AT1HI1" 64949 "DM23" 64950 "DM24" 64951 "DM25" 64952 "DM26" 64953 "TPRI" 64965 "ECUID" 64981 "EEC5" 65039 "LC" 65099 "TCFG2" 65109 "GFD" 65127 "CCC" 65131 "DI" 65136 "CVW" 65144 "TP1" 65145 "TP2" 65146 "TP3" 65195 "ETC6" 65196 "EBC4" 65199 "GFC" 65201 "EH" 65202 "GFI1" 65203 "LFI1" 65208 "GTFI" 65212 "CBI" 65214 "EEC4" 65216 "SERV" 65219 "ETC5" 65221 "ETC4" 65223 "ETC3" 65227 "DM02" 65228 "DM03" 65229 "DM04" 65230 "DM05" 65231 "DM06" 65234 "DM10" 65235 "DM11" 65236 "DM12" 65242 "SOFT" 65244 "IO" 65248 "VD" 65250 "TCFG" 65253 "HOURS" 65254 "TD" 65255 "VH" 65256 "VDS" 65257 "LFC1" 65258 "VW" 65259 "CI" 65260 "VI" 65261 "CCSS" 65284 "PB_DriversConsentOnPersonalData" 65376 "VehCfg" 65413 "PB_3CT" 65482 "PB_ID1" 65484 "PB_VNS" 65502 "Av2" 65520 "SCh" 65521 "DIS" 65524 "PB_IVA" ;
VAL_ 2565406515 Pgn_Ack_E8FF33 37120 "VLSI1" 40448 "DM29" 41216 "DM33" 41728 "DM31" 41984 "DM30" 47360 "PLLT(PlanListLifetime)" 47872 "PLD(PlanListDistance)" 49408 "DM21" 49664 "DM20" 49920 "DM22" 53504 "MaintBcIc" 54016 "DM19" 60928 "ACL" 61184 "STOD" 64342 "HVESP3CFG" 64344 "HVESP2CFG" 64346 "HVESP1CFG" 64529 "TGFI" 64579 "TCSI" 64582 "TSIS" 64583 "MTI" 64605 "HVESSCFG" 64606 "HVESSHIST" 64653 "PII" 64701 "A1SCRSI2" 64782 "AT1OGC2" 64784 "AT1IGC2" 64839 "TML" 64879 "EEC8" 64896 "DM28" 64905 "VDS2" 64906 "J2012" 64912 "AETC" 64920 "AT1HI1" 64949 "DM23" 64950 "DM24" 64951 "DM25" 64952 "DM26" 64953 "TPRI" 64965 "ECUID" 64981 "EEC5" 65039 "LC" 65099 "TCFG2" 65109 "GFD" 65127 "CCC" 65131 "DI" 65136 "CVW" 65144 "TP1" 65145 "TP2" 65146 "TP3" 65195 "ETC6" 65196 "EBC4" 65199 "GFC" 65201 "EH" 65202 "GFI1" 65203 "LFI1" 65208 "GTFI" 65212 "CBI" 65214 "EEC4" 65216 "SERV" 65219 "ETC5" 65221 "ETC4" 65223 "ETC3" 65227 "DM02" 65228 "DM03" 65229 "DM04" 65230 "DM05" 65231 "DM06" 65234 "DM10" 65235 "DM11" 65236 "DM12" 65242 "SOFT" 65244 "IO" 65248 "VD" 65250 "TCFG" 65253 "HOURS" 65254 "TD" 65255 "VH" 65256 "VDS" 65257 "LFC1" 65258 "VW" 65259 "CI" 65260 "VI" 65261 "CCSS" 65284 "PB_DriversConsentOnPersonalData" 65376 "VehCfg" 65413 "PB_3CT" 65482 "PB_ID1" 65484 "PB_VNS" 65502 "Av2" 65520 "SCh" 65521 "DIS" 65524 "PB_IVA" ;
VAL_ 2565406515 CtrlByte_Ackm_E8FF33 0 "ACK" 1 "NACK" 2 "Access Denied" 3 "Cannot Respond" ;
VAL_ 2565406520 Pgn_Busy_E8FF38 37120 "VLSI1" 40448 "DM29" 41216 "DM33" 41728 "DM31" 41984 "DM30" 47360 "PLLT(PlanListLifetime)" 47872 "PLD(PlanListDistance)" 49408 "DM21" 49664 "DM20" 49920 "DM22" 53504 "MaintBcIc" 54016 "DM19" 60928 "ACL" 61184 "STOD" 64342 "HVESP3CFG" 64344 "HVESP2CFG" 64346 "HVESP1CFG" 64529 "TGFI" 64579 "TCSI" 64582 "TSIS" 64583 "MTI" 64605 "HVESSCFG" 64606 "HVESSHIST" 64653 "PII" 64701 "A1SCRSI2" 64782 "AT1OGC2" 64784 "AT1IGC2" 64839 "TML" 64879 "EEC8" 64896 "DM28" 64905 "VDS2" 64906 "J2012" 64912 "AETC" 64920 "AT1HI1" 64949 "DM23" 64950 "DM24" 64951 "DM25" 64952 "DM26" 64953 "TPRI" 64965 "ECUID" 64981 "EEC5" 65039 "LC" 65099 "TCFG2" 65109 "GFD" 65127 "CCC" 65131 "DI" 65136 "CVW" 65144 "TP1" 65145 "TP2" 65146 "TP3" 65195 "ETC6" 65196 "EBC4" 65199 "GFC" 65201 "EH" 65202 "GFI1" 65203 "LFI1" 65208 "GTFI" 65212 "CBI" 65214 "EEC4" 65216 "SERV" 65219 "ETC5" 65221 "ETC4" 65223 "ETC3" 65227 "DM02" 65228 "DM03" 65229 "DM04" 65230 "DM05" 65231 "DM06" 65234 "DM10" 65235 "DM11" 65236 "DM12" 65242 "SOFT" 65244 "IO" 65248 "VD" 65250 "TCFG" 65253 "HOURS" 65254 "TD" 65255 "VH" 65256 "VDS" 65257 "LFC1" 65258 "VW" 65259 "CI" 65260 "VI" 65261 "CCSS" 65284 "PB_DriversConsentOnPersonalData" 65376 "VehCfg" 65413 "PB_3CT" 65482 "PB_ID1" 65484 "PB_VNS" 65502 "Av2" 65520 "SCh" 65521 "DIS" 65524 "PB_IVA" ;
VAL_ 2565406520 Pgn_Ad_E8FF38 37120 "VLSI1" 40448 "DM29" 41216 "DM33" 41728 "DM31" 41984 "DM30" 47360 "PLLT(PlanListLifetime)" 47872 "PLD(PlanListDistance)" 49408 "DM21" 49664 "DM20" 49920 "DM22" 53504 "MaintBcIc" 54016 "DM19" 60928 "ACL" 61184 "STOD" 64342 "HVESP3CFG" 64344 "HVESP2CFG" 64346 "HVESP1CFG" 64529 "TGFI" 64579 "TCSI" 64582 "TSIS" 64583 "MTI" 64605 "HVESSCFG" 64606 "HVESSHIST" 64653 "PII" 64701 "A1SCRSI2" 64782 "AT1OGC2" 64784 "AT1IGC2" 64839 "TML" 64879 "EEC8" 64896 "DM28" 64905 "VDS2" 64906 "J2012" 64912 "AETC" 64920 "AT1HI1" 64949 "DM23" 64950 "DM24" 64951 "DM25" 64952 "DM26" 64953 "TPRI" 64965 "ECUID" 64981 "EEC5" 65039 "LC" 65099 "TCFG2" 65109 "GFD" 65127 "CCC" 65131 "DI" 65136 "CVW" 65144 "TP1" 65145 "TP2" 65146 "TP3" 65195 "ETC6" 65196 "EBC4" 65199 "GFC" 65201 "EH" 65202 "GFI1" 65203 "LFI1" 65208 "GTFI" 65212 "CBI" 65214 "EEC4" 65216 "SERV" 65219 "ETC5" 65221 "ETC4" 65223 "ETC3" 65227 "DM02" 65228 "DM03" 65229 "DM04" 65230 "DM05" 65231 "DM06" 65234 "DM10" 65235 "DM11" 65236 "DM12" 65242 "SOFT" 65244 "IO" 65248 "VD" 65250 "TCFG" 65253 "HOURS" 65254 "TD" 65255 "VH" 65256 "VDS" 65257 "LFC1" 65258 "VW" 65259 "CI" 65260 "VI" 65261 "CCSS" 65284 "PB_DriversConsentOnPersonalData" 65376 "VehCfg" 65413 "PB_3CT" 65482 "PB_ID1" 65484 "PB_VNS" 65502 "Av2" 65520 "SCh" 65521 "DIS" 65524 "PB_IVA" ;
VAL_ 2565406520 Pgn_Nack_E8FF38 37120 "VLSI1" 40448 "DM29" 41216 "DM33" 41728 "DM31" 41984 "DM30" 47360 "PLLT(PlanListLifetime)" 47872 "PLD(PlanListDistance)" 49408 "DM21" 49664 "DM20" 49920 "DM22" 53504 "MaintBcIc" 54016 "DM19" 60928 "ACL" 61184 "STOD" 64342 "HVESP3CFG" 64344 "HVESP2CFG" 64346 "HVESP1CFG" 64529 "TGFI" 64579 "TCSI" 64582 "TSIS" 64583 "MTI" 64605 "HVESSCFG" 64606 "HVESSHIST" 64653 "PII" 64701 "A1SCRSI2" 64782 "AT1OGC2" 64784 "AT1IGC2" 64839 "TML" 64879 "EEC8" 64896 "DM28" 64905 "VDS2" 64906 "J2012" 64912 "AETC" 64920 "AT1HI1" 64949 "DM23" 64950 "DM24" 64951 "DM25" 64952 "DM26" 64953 "TPRI" 64965 "ECUID" 64981 "EEC5" 65039 "LC" 65099 "TCFG2" 65109 "GFD" 65127 "CCC" 65131 "DI" 65136 "CVW" 65144 "TP1" 65145 "TP2" 65146 "TP3" 65195 "ETC6" 65196 "EBC4" 65199 "GFC" 65201 "EH" 65202 "GFI1" 65203 "LFI1" 65208 "GTFI" 65212 "CBI" 65214 "EEC4" 65216 "SERV" 65219 "ETC5" 65221 "ETC4" 65223 "ETC3" 65227 "DM02" 65228 "DM03" 65229 "DM04" 65230 "DM05" 65231 "DM06" 65234 "DM10" 65235 "DM11" 65236 "DM12" 65242 "SOFT" 65244 "IO" 65248 "VD" 65250 "TCFG" 65253 "HOURS" 65254 "TD" 65255 "VH" 65256 "VDS" 65257 "LFC1" 65258 "VW" 65259 "CI" 65260 "VI" 65261 "CCSS" 65284 "PB_DriversConsentOnPersonalData" 65376 "VehCfg" 65413 "PB_3CT" 65482 "PB_ID1" 65484 "PB_VNS" 65502 "Av2" 65520 "SCh" 65521 "DIS" 65524 "PB_IVA" ;
VAL_ 2565406520 Pgn_Ack_E8FF38 37120 "VLSI1" 40448 "DM29" 41216 "DM33" 41728 "DM31" 41984 "DM30" 47360 "PLLT(PlanListLifetime)" 47872 "PLD(PlanListDistance)" 49408 "DM21" 49664 "DM20" 49920 "DM22" 53504 "MaintBcIc" 54016 "DM19" 60928 "ACL" 61184 "STOD" 64342 "HVESP3CFG" 64344 "HVESP2CFG" 64346 "HVESP1CFG" 64529 "TGFI" 64579 "TCSI" 64582 "TSIS" 64583 "MTI" 64605 "HVESSCFG" 64606 "HVESSHIST" 64653 "PII" 64701 "A1SCRSI2" 64782 "AT1OGC2" 64784 "AT1IGC2" 64839 "TML" 64879 "EEC8" 64896 "DM28" 64905 "VDS2" 64906 "J2012" 64912 "AETC" 64920 "AT1HI1" 64949 "DM23" 64950 "DM24" 64951 "DM25" 64952 "DM26" 64953 "TPRI" 64965 "ECUID" 64981 "EEC5" 65039 "LC" 65099 "TCFG2" 65109 "GFD" 65127 "CCC" 65131 "DI" 65136 "CVW" 65144 "TP1" 65145 "TP2" 65146 "TP3" 65195 "ETC6" 65196 "EBC4" 65199 "GFC" 65201 "EH" 65202 "GFI1" 65203 "LFI1" 65208 "GTFI" 65212 "CBI" 65214 "EEC4" 65216 "SERV" 65219 "ETC5" 65221 "ETC4" 65223 "ETC3" 65227 "DM02" 65228 "DM03" 65229 "DM04" 65230 "DM05" 65231 "DM06" 65234 "DM10" 65235 "DM11" 65236 "DM12" 65242 "SOFT" 65244 "IO" 65248 "VD" 65250 "TCFG" 65253 "HOURS" 65254 "TD" 65255 "VH" 65256 "VDS" 65257 "LFC1" 65258 "VW" 65259 "CI" 65260 "VI" 65261 "CCSS" 65284 "PB_DriversConsentOnPersonalData" 65376 "VehCfg" 65413 "PB_3CT" 65482 "PB_ID1" 65484 "PB_VNS" 65502 "Av2" 65520 "SCh" 65521 "DIS" 65524 "PB_IVA" ;
VAL_ 2565406520 CtrlByte_Ackm_E8FF38 0 "ACK" 1 "NACK" 2 "Access Denied" 3 "Cannot Respond" ;
VAL_ 2565406590 Pgn_Busy_E8FF7E 37120 "VLSI1" 40448 "DM29" 41216 "DM33" 41728 "DM31" 41984 "DM30" 47360 "PLLT(PlanListLifetime)" 47872 "PLD(PlanListDistance)" 49408 "DM21" 49664 "DM20" 49920 "DM22" 53504 "MaintBcIc" 54016 "DM19" 60928 "ACL" 61184 "STOD" 64342 "HVESP3CFG" 64344 "HVESP2CFG" 64346 "HVESP1CFG" 64529 "TGFI" 64579 "TCSI" 64582 "TSIS" 64583 "MTI" 64605 "HVESSCFG" 64606 "HVESSHIST" 64653 "PII" 64701 "A1SCRSI2" 64782 "AT1OGC2" 64784 "AT1IGC2" 64839 "TML" 64879 "EEC8" 64896 "DM28" 64905 "VDS2" 64906 "J2012" 64912 "AETC" 64920 "AT1HI1" 64949 "DM23" 64950 "DM24" 64951 "DM25" 64952 "DM26" 64953 "TPRI" 64965 "ECUID" 64981 "EEC5" 65039 "LC" 65099 "TCFG2" 65109 "GFD" 65127 "CCC" 65131 "DI" 65136 "CVW" 65144 "TP1" 65145 "TP2" 65146 "TP3" 65195 "ETC6" 65196 "EBC4" 65199 "GFC" 65201 "EH" 65202 "GFI1" 65203 "LFI1" 65208 "GTFI" 65212 "CBI" 65214 "EEC4" 65216 "SERV" 65219 "ETC5" 65221 "ETC4" 65223 "ETC3" 65227 "DM02" 65228 "DM03" 65229 "DM04" 65230 "DM05" 65231 "DM06" 65234 "DM10" 65235 "DM11" 65236 "DM12" 65242 "SOFT" 65244 "IO" 65248 "VD" 65250 "TCFG" 65253 "HOURS" 65254 "TD" 65255 "VH" 65256 "VDS" 65257 "LFC1" 65258 "VW" 65259 "CI" 65260 "VI" 65261 "CCSS" 65284 "PB_DriversConsentOnPersonalData" 65376 "VehCfg" 65413 "PB_3CT" 65482 "PB_ID1" 65484 "PB_VNS" 65502 "Av2" 65520 "SCh" 65521 "DIS" 65524 "PB_IVA" ;
VAL_ 2565406590 Pgn_Ad_E8FF7E 37120 "VLSI1" 40448 "DM29" 41216 "DM33" 41728 "DM31" 41984 "DM30" 47360 "PLLT(PlanListLifetime)" 47872 "PLD(PlanListDistance)" 49408 "DM21" 49664 "DM20" 49920 "DM22" 53504 "MaintBcIc" 54016 "DM19" 60928 "ACL" 61184 "STOD" 64342 "HVESP3CFG" 64344 "HVESP2CFG" 64346 "HVESP1CFG" 64529 "TGFI" 64579 "TCSI" 64582 "TSIS" 64583 "MTI" 64605 "HVESSCFG" 64606 "HVESSHIST" 64653 "PII" 64701 "A1SCRSI2" 64782 "AT1OGC2" 64784 "AT1IGC2" 64839 "TML" 64879 "EEC8" 64896 "DM28" 64905 "VDS2" 64906 "J2012" 64912 "AETC" 64920 "AT1HI1" 64949 "DM23" 64950 "DM24" 64951 "DM25" 64952 "DM26" 64953 "TPRI" 64965 "ECUID" 64981 "EEC5" 65039 "LC" 65099 "TCFG2" 65109 "GFD" 65127 "CCC" 65131 "DI" 65136 "CVW" 65144 "TP1" 65145 "TP2" 65146 "TP3" 65195 "ETC6" 65196 "EBC4" 65199 "GFC" 65201 "EH" 65202 "GFI1" 65203 "LFI1" 65208 "GTFI" 65212 "CBI" 65214 "EEC4" 65216 "SERV" 65219 "ETC5" 65221 "ETC4" 65223 "ETC3" 65227 "DM02" 65228 "DM03" 65229 "DM04" 65230 "DM05" 65231 "DM06" 65234 "DM10" 65235 "DM11" 65236 "DM12" 65242 "SOFT" 65244 "IO" 65248 "VD" 65250 "TCFG" 65253 "HOURS" 65254 "TD" 65255 "VH" 65256 "VDS" 65257 "LFC1" 65258 "VW" 65259 "CI" 65260 "VI" 65261 "CCSS" 65284 "PB_DriversConsentOnPersonalData" 65376 "VehCfg" 65413 "PB_3CT" 65482 "PB_ID1" 65484 "PB_VNS" 65502 "Av2" 65520 "SCh" 65521 "DIS" 65524 "PB_IVA" ;
VAL_ 2565406590 Pgn_Nack_E8FF7E 37120 "VLSI1" 40448 "DM29" 41216 "DM33" 41728 "DM31" 41984 "DM30" 47360 "PLLT(PlanListLifetime)" 47872 "PLD(PlanListDistance)" 49408 "DM21" 49664 "DM20" 49920 "DM22" 53504 "MaintBcIc" 54016 "DM19" 60928 "ACL" 61184 "STOD" 64342 "HVESP3CFG" 64344 "HVESP2CFG" 64346 "HVESP1CFG" 64529 "TGFI" 64579 "TCSI" 64582 "TSIS" 64583 "MTI" 64605 "HVESSCFG" 64606 "HVESSHIST" 64653 "PII" 64701 "A1SCRSI2" 64782 "AT1OGC2" 64784 "AT1IGC2" 64839 "TML" 64879 "EEC8" 64896 "DM28" 64905 "VDS2" 64906 "J2012" 64912 "AETC" 64920 "AT1HI1" 64949 "DM23" 64950 "DM24" 64951 "DM25" 64952 "DM26" 64953 "TPRI" 64965 "ECUID" 64981 "EEC5" 65039 "LC" 65099 "TCFG2" 65109 "GFD" 65127 "CCC" 65131 "DI" 65136 "CVW" 65144 "TP1" 65145 "TP2" 65146 "TP3" 65195 "ETC6" 65196 "EBC4" 65199 "GFC" 65201 "EH" 65202 "GFI1" 65203 "LFI1" 65208 "GTFI" 65212 "CBI" 65214 "EEC4" 65216 "SERV" 65219 "ETC5" 65221 "ETC4" 65223 "ETC3" 65227 "DM02" 65228 "DM03" 65229 "DM04" 65230 "DM05" 65231 "DM06" 65234 "DM10" 65235 "DM11" 65236 "DM12" 65242 "SOFT" 65244 "IO" 65248 "VD" 65250 "TCFG" 65253 "HOURS" 65254 "TD" 65255 "VH" 65256 "VDS" 65257 "LFC1" 65258 "VW" 65259 "CI" 65260 "VI" 65261 "CCSS" 65284 "PB_DriversConsentOnPersonalData" 65376 "VehCfg" 65413 "PB_3CT" 65482 "PB_ID1" 65484 "PB_VNS" 65502 "Av2" 65520 "SCh" 65521 "DIS" 65524 "PB_IVA" ;
VAL_ 2565406590 Pgn_Ack_E8FF7E 37120 "VLSI1" 40448 "DM29" 41216 "DM33" 41728 "DM31" 41984 "DM30" 47360 "PLLT(PlanListLifetime)" 47872 "PLD(PlanListDistance)" 49408 "DM21" 49664 "DM20" 49920 "DM22" 53504 "MaintBcIc" 54016 "DM19" 60928 "ACL" 61184 "STOD" 64342 "HVESP3CFG" 64344 "HVESP2CFG" 64346 "HVESP1CFG" 64529 "TGFI" 64579 "TCSI" 64582 "TSIS" 64583 "MTI" 64605 "HVESSCFG" 64606 "HVESSHIST" 64653 "PII" 64701 "A1SCRSI2" 64782 "AT1OGC2" 64784 "AT1IGC2" 64839 "TML" 64879 "EEC8" 64896 "DM28" 64905 "VDS2" 64906 "J2012" 64912 "AETC" 64920 "AT1HI1" 64949 "DM23" 64950 "DM24" 64951 "DM25" 64952 "DM26" 64953 "TPRI" 64965 "ECUID" 64981 "EEC5" 65039 "LC" 65099 "TCFG2" 65109 "GFD" 65127 "CCC" 65131 "DI" 65136 "CVW" 65144 "TP1" 65145 "TP2" 65146 "TP3" 65195 "ETC6" 65196 "EBC4" 65199 "GFC" 65201 "EH" 65202 "GFI1" 65203 "LFI1" 65208 "GTFI" 65212 "CBI" 65214 "EEC4" 65216 "SERV" 65219 "ETC5" 65221 "ETC4" 65223 "ETC3" 65227 "DM02" 65228 "DM03" 65229 "DM04" 65230 "DM05" 65231 "DM06" 65234 "DM10" 65235 "DM11" 65236 "DM12" 65242 "SOFT" 65244 "IO" 65248 "VD" 65250 "TCFG" 65253 "HOURS" 65254 "TD" 65255 "VH" 65256 "VDS" 65257 "LFC1" 65258 "VW" 65259 "CI" 65260 "VI" 65261 "CCSS" 65284 "PB_DriversConsentOnPersonalData" 65376 "VehCfg" 65413 "PB_3CT" 65482 "PB_ID1" 65484 "PB_VNS" 65502 "Av2" 65520 "SCh" 65521 "DIS" 65524 "PB_IVA" ;
VAL_ 2565406590 CtrlByte_Ackm_E8FF7E 0 "ACK" 1 "NACK" 2 "Access Denied" 3 "Cannot Respond" ;
VAL_ 2565406622 Pgn_Busy_E8FF9E 37120 "VLSI1" 40448 "DM29" 41216 "DM33" 41728 "DM31" 41984 "DM30" 47360 "PLLT(PlanListLifetime)" 47872 "PLD(PlanListDistance)" 49408 "DM21" 49664 "DM20" 49920 "DM22" 53504 "MaintBcIc" 54016 "DM19" 60928 "ACL" 61184 "STOD" 64342 "HVESP3CFG" 64344 "HVESP2CFG" 64346 "HVESP1CFG" 64529 "TGFI" 64579 "TCSI" 64582 "TSIS" 64583 "MTI" 64605 "HVESSCFG" 64606 "HVESSHIST" 64653 "PII" 64701 "A1SCRSI2" 64782 "AT1OGC2" 64784 "AT1IGC2" 64839 "TML" 64879 "EEC8" 64896 "DM28" 64905 "VDS2" 64906 "J2012" 64912 "AETC" 64920 "AT1HI1" 64949 "DM23" 64950 "DM24" 64951 "DM25" 64952 "DM26" 64953 "TPRI" 64965 "ECUID" 64981 "EEC5" 65039 "LC" 65099 "TCFG2" 65109 "GFD" 65127 "CCC" 65131 "DI" 65136 "CVW" 65144 "TP1" 65145 "TP2" 65146 "TP3" 65195 "ETC6" 65196 "EBC4" 65199 "GFC" 65201 "EH" 65202 "GFI1" 65203 "LFI1" 65208 "GTFI" 65212 "CBI" 65214 "EEC4" 65216 "SERV" 65219 "ETC5" 65221 "ETC4" 65223 "ETC3" 65227 "DM02" 65228 "DM03" 65229 "DM04" 65230 "DM05" 65231 "DM06" 65234 "DM10" 65235 "DM11" 65236 "DM12" 65242 "SOFT" 65244 "IO" 65248 "VD" 65250 "TCFG" 65253 "HOURS" 65254 "TD" 65255 "VH" 65256 "VDS" 65257 "LFC1" 65258 "VW" 65259 "CI" 65260 "VI" 65261 "CCSS" 65284 "PB_DriversConsentOnPersonalData" 65376 "VehCfg" 65413 "PB_3CT" 65482 "PB_ID1" 65484 "PB_VNS" 65502 "Av2" 65520 "SCh" 65521 "DIS" 65524 "PB_IVA" ;
VAL_ 2565406622 Pgn_Ad_E8FF9E 37120 "VLSI1" 40448 "DM29" 41216 "DM33" 41728 "DM31" 41984 "DM30" 47360 "PLLT(PlanListLifetime)" 47872 "PLD(PlanListDistance)" 49408 "DM21" 49664 "DM20" 49920 "DM22" 53504 "MaintBcIc" 54016 "DM19" 60928 "ACL" 61184 "STOD" 64342 "HVESP3CFG" 64344 "HVESP2CFG" 64346 "HVESP1CFG" 64529 "TGFI" 64579 "TCSI" 64582 "TSIS" 64583 "MTI" 64605 "HVESSCFG" 64606 "HVESSHIST" 64653 "PII" 64701 "A1SCRSI2" 64782 "AT1OGC2" 64784 "AT1IGC2" 64839 "TML" 64879 "EEC8" 64896 "DM28" 64905 "VDS2" 64906 "J2012" 64912 "AETC" 64920 "AT1HI1" 64949 "DM23" 64950 "DM24" 64951 "DM25" 64952 "DM26" 64953 "TPRI" 64965 "ECUID" 64981 "EEC5" 65039 "LC" 65099 "TCFG2" 65109 "GFD" 65127 "CCC" 65131 "DI" 65136 "CVW" 65144 "TP1" 65145 "TP2" 65146 "TP3" 65195 "ETC6" 65196 "EBC4" 65199 "GFC" 65201 "EH" 65202 "GFI1" 65203 "LFI1" 65208 "GTFI" 65212 "CBI" 65214 "EEC4" 65216 "SERV" 65219 "ETC5" 65221 "ETC4" 65223 "ETC3" 65227 "DM02" 65228 "DM03" 65229 "DM04" 65230 "DM05" 65231 "DM06" 65234 "DM10" 65235 "DM11" 65236 "DM12" 65242 "SOFT" 65244 "IO" 65248 "VD" 65250 "TCFG" 65253 "HOURS" 65254 "TD" 65255 "VH" 65256 "VDS" 65257 "LFC1" 65258 "VW" 65259 "CI" 65260 "VI" 65261 "CCSS" 65284 "PB_DriversConsentOnPersonalData" 65376 "VehCfg" 65413 "PB_3CT" 65482 "PB_ID1" 65484 "PB_VNS" 65502 "Av2" 65520 "SCh" 65521 "DIS" 65524 "PB_IVA" ;
VAL_ 2565406622 Pgn_Nack_E8FF9E 37120 "VLSI1" 40448 "DM29" 41216 "DM33" 41728 "DM31" 41984 "DM30" 47360 "PLLT(PlanListLifetime)" 47872 "PLD(PlanListDistance)" 49408 "DM21" 49664 "DM20" 49920 "DM22" 53504 "MaintBcIc" 54016 "DM19" 60928 "ACL" 61184 "STOD" 64342 "HVESP3CFG" 64344 "HVESP2CFG" 64346 "HVESP1CFG" 64529 "TGFI" 64579 "TCSI" 64582 "TSIS" 64583 "MTI" 64605 "HVESSCFG" 64606 "HVESSHIST" 64653 "PII" 64701 "A1SCRSI2" 64782 "AT1OGC2" 64784 "AT1IGC2" 64839 "TML" 64879 "EEC8" 64896 "DM28" 64905 "VDS2" 64906 "J2012" 64912 "AETC" 64920 "AT1HI1" 64949 "DM23" 64950 "DM24" 64951 "DM25" 64952 "DM26" 64953 "TPRI" 64965 "ECUID" 64981 "EEC5" 65039 "LC" 65099 "TCFG2" 65109 "GFD" 65127 "CCC" 65131 "DI" 65136 "CVW" 65144 "TP1" 65145 "TP2" 65146 "TP3" 65195 "ETC6" 65196 "EBC4" 65199 "GFC" 65201 "EH" 65202 "GFI1" 65203 "LFI1" 65208 "GTFI" 65212 "CBI" 65214 "EEC4" 65216 "SERV" 65219 "ETC5" 65221 "ETC4" 65223 "ETC3" 65227 "DM02" 65228 "DM03" 65229 "DM04" 65230 "DM05" 65231 "DM06" 65234 "DM10" 65235 "DM11" 65236 "DM12" 65242 "SOFT" 65244 "IO" 65248 "VD" 65250 "TCFG" 65253 "HOURS" 65254 "TD" 65255 "VH" 65256 "VDS" 65257 "LFC1" 65258 "VW" 65259 "CI" 65260 "VI" 65261 "CCSS" 65284 "PB_DriversConsentOnPersonalData" 65376 "VehCfg" 65413 "PB_3CT" 65482 "PB_ID1" 65484 "PB_VNS" 65502 "Av2" 65520 "SCh" 65521 "DIS" 65524 "PB_IVA" ;
VAL_ 2565406622 Pgn_Ack_E8FF9E 37120 "VLSI1" 40448 "DM29" 41216 "DM33" 41728 "DM31" 41984 "DM30" 47360 "PLLT(PlanListLifetime)" 47872 "PLD(PlanListDistance)" 49408 "DM21" 49664 "DM20" 49920 "DM22" 53504 "MaintBcIc" 54016 "DM19" 60928 "ACL" 61184 "STOD" 64342 "HVESP3CFG" 64344 "HVESP2CFG" 64346 "HVESP1CFG" 64529 "TGFI" 64579 "TCSI" 64582 "TSIS" 64583 "MTI" 64605 "HVESSCFG" 64606 "HVESSHIST" 64653 "PII" 64701 "A1SCRSI2" 64782 "AT1OGC2" 64784 "AT1IGC2" 64839 "TML" 64879 "EEC8" 64896 "DM28" 64905 "VDS2" 64906 "J2012" 64912 "AETC" 64920 "AT1HI1" 64949 "DM23" 64950 "DM24" 64951 "DM25" 64952 "DM26" 64953 "TPRI" 64965 "ECUID" 64981 "EEC5" 65039 "LC" 65099 "TCFG2" 65109 "GFD" 65127 "CCC" 65131 "DI" 65136 "CVW" 65144 "TP1" 65145 "TP2" 65146 "TP3" 65195 "ETC6" 65196 "EBC4" 65199 "GFC" 65201 "EH" 65202 "GFI1" 65203 "LFI1" 65208 "GTFI" 65212 "CBI" 65214 "EEC4" 65216 "SERV" 65219 "ETC5" 65221 "ETC4" 65223 "ETC3" 65227 "DM02" 65228 "DM03" 65229 "DM04" 65230 "DM05" 65231 "DM06" 65234 "DM10" 65235 "DM11" 65236 "DM12" 65242 "SOFT" 65244 "IO" 65248 "VD" 65250 "TCFG" 65253 "HOURS" 65254 "TD" 65255 "VH" 65256 "VDS" 65257 "LFC1" 65258 "VW" 65259 "CI" 65260 "VI" 65261 "CCSS" 65284 "PB_DriversConsentOnPersonalData" 65376 "VehCfg" 65413 "PB_3CT" 65482 "PB_ID1" 65484 "PB_VNS" 65502 "Av2" 65520 "SCh" 65521 "DIS" 65524 "PB_IVA" ;
VAL_ 2565406622 CtrlByte_Ackm_E8FF9E 0 "ACK" 1 "NACK" 2 "Access Denied" 3 "Cannot Respond" ;
VAL_ 2565406624 Pgn_Busy_E8FFA0 37120 "VLSI1" 40448 "DM29" 41216 "DM33" 41728 "DM31" 41984 "DM30" 47360 "PLLT(PlanListLifetime)" 47872 "PLD(PlanListDistance)" 49408 "DM21" 49664 "DM20" 49920 "DM22" 53504 "MaintBcIc" 54016 "DM19" 60928 "ACL" 61184 "STOD" 64342 "HVESP3CFG" 64344 "HVESP2CFG" 64346 "HVESP1CFG" 64529 "TGFI" 64579 "TCSI" 64582 "TSIS" 64583 "MTI" 64605 "HVESSCFG" 64606 "HVESSHIST" 64653 "PII" 64701 "A1SCRSI2" 64782 "AT1OGC2" 64784 "AT1IGC2" 64839 "TML" 64879 "EEC8" 64896 "DM28" 64905 "VDS2" 64906 "J2012" 64912 "AETC" 64920 "AT1HI1" 64949 "DM23" 64950 "DM24" 64951 "DM25" 64952 "DM26" 64953 "TPRI" 64965 "ECUID" 64981 "EEC5" 65039 "LC" 65099 "TCFG2" 65109 "GFD" 65127 "CCC" 65131 "DI" 65136 "CVW" 65144 "TP1" 65145 "TP2" 65146 "TP3" 65195 "ETC6" 65196 "EBC4" 65199 "GFC" 65201 "EH" 65202 "GFI1" 65203 "LFI1" 65208 "GTFI" 65212 "CBI" 65214 "EEC4" 65216 "SERV" 65219 "ETC5" 65221 "ETC4" 65223 "ETC3" 65227 "DM02" 65228 "DM03" 65229 "DM04" 65230 "DM05" 65231 "DM06" 65234 "DM10" 65235 "DM11" 65236 "DM12" 65242 "SOFT" 65244 "IO" 65248 "VD" 65250 "TCFG" 65253 "HOURS" 65254 "TD" 65255 "VH" 65256 "VDS" 65257 "LFC1" 65258 "VW" 65259 "CI" 65260 "VI" 65261 "CCSS" 65284 "PB_DriversConsentOnPersonalData" 65376 "VehCfg" 65413 "PB_3CT" 65482 "PB_ID1" 65484 "PB_VNS" 65502 "Av2" 65520 "SCh" 65521 "DIS" 65524 "PB_IVA" ;
VAL_ 2565406624 Pgn_Ad_E8FFA0 37120 "VLSI1" 40448 "DM29" 41216 "DM33" 41728 "DM31" 41984 "DM30" 47360 "PLLT(PlanListLifetime)" 47872 "PLD(PlanListDistance)" 49408 "DM21" 49664 "DM20" 49920 "DM22" 53504 "MaintBcIc" 54016 "DM19" 60928 "ACL" 61184 "STOD" 64342 "HVESP3CFG" 64344 "HVESP2CFG" 64346 "HVESP1CFG" 64529 "TGFI" 64579 "TCSI" 64582 "TSIS" 64583 "MTI" 64605 "HVESSCFG" 64606 "HVESSHIST" 64653 "PII" 64701 "A1SCRSI2" 64782 "AT1OGC2" 64784 "AT1IGC2" 64839 "TML" 64879 "EEC8" 64896 "DM28" 64905 "VDS2" 64906 "J2012" 64912 "AETC" 64920 "AT1HI1" 64949 "DM23" 64950 "DM24" 64951 "DM25" 64952 "DM26" 64953 "TPRI" 64965 "ECUID" 64981 "EEC5" 65039 "LC" 65099 "TCFG2" 65109 "GFD" 65127 "CCC" 65131 "DI" 65136 "CVW" 65144 "TP1" 65145 "TP2" 65146 "TP3" 65195 "ETC6" 65196 "EBC4" 65199 "GFC" 65201 "EH" 65202 "GFI1" 65203 "LFI1" 65208 "GTFI" 65212 "CBI" 65214 "EEC4" 65216 "SERV" 65219 "ETC5" 65221 "ETC4" 65223 "ETC3" 65227 "DM02" 65228 "DM03" 65229 "DM04" 65230 "DM05" 65231 "DM06" 65234 "DM10" 65235 "DM11" 65236 "DM12" 65242 "SOFT" 65244 "IO" 65248 "VD" 65250 "TCFG" 65253 "HOURS" 65254 "TD" 65255 "VH" 65256 "VDS" 65257 "LFC1" 65258 "VW" 65259 "CI" 65260 "VI" 65261 "CCSS" 65284 "PB_DriversConsentOnPersonalData" 65376 "VehCfg" 65413 "PB_3CT" 65482 "PB_ID1" 65484 "PB_VNS" 65502 "Av2" 65520 "SCh" 65521 "DIS" 65524 "PB_IVA" ;
VAL_ 2565406624 Pgn_Nack_E8FFA0 37120 "VLSI1" 40448 "DM29" 41216 "DM33" 41728 "DM31" 41984 "DM30" 47360 "PLLT(PlanListLifetime)" 47872 "PLD(PlanListDistance)" 49408 "DM21" 49664 "DM20" 49920 "DM22" 53504 "MaintBcIc" 54016 "DM19" 60928 "ACL" 61184 "STOD" 64342 "HVESP3CFG" 64344 "HVESP2CFG" 64346 "HVESP1CFG" 64529 "TGFI" 64579 "TCSI" 64582 "TSIS" 64583 "MTI" 64605 "HVESSCFG" 64606 "HVESSHIST" 64653 "PII" 64701 "A1SCRSI2" 64782 "AT1OGC2" 64784 "AT1IGC2" 64839 "TML" 64879 "EEC8" 64896 "DM28" 64905 "VDS2" 64906 "J2012" 64912 "AETC" 64920 "AT1HI1" 64949 "DM23" 64950 "DM24" 64951 "DM25" 64952 "DM26" 64953 "TPRI" 64965 "ECUID" 64981 "EEC5" 65039 "LC" 65099 "TCFG2" 65109 "GFD" 65127 "CCC" 65131 "DI" 65136 "CVW" 65144 "TP1" 65145 "TP2" 65146 "TP3" 65195 "ETC6" 65196 "EBC4" 65199 "GFC" 65201 "EH" 65202 "GFI1" 65203 "LFI1" 65208 "GTFI" 65212 "CBI" 65214 "EEC4" 65216 "SERV" 65219 "ETC5" 65221 "ETC4" 65223 "ETC3" 65227 "DM02" 65228 "DM03" 65229 "DM04" 65230 "DM05" 65231 "DM06" 65234 "DM10" 65235 "DM11" 65236 "DM12" 65242 "SOFT" 65244 "IO" 65248 "VD" 65250 "TCFG" 65253 "HOURS" 65254 "TD" 65255 "VH" 65256 "VDS" 65257 "LFC1" 65258 "VW" 65259 "CI" 65260 "VI" 65261 "CCSS" 65284 "PB_DriversConsentOnPersonalData" 65376 "VehCfg" 65413 "PB_3CT" 65482 "PB_ID1" 65484 "PB_VNS" 65502 "Av2" 65520 "SCh" 65521 "DIS" 65524 "PB_IVA" ;
VAL_ 2565406624 Pgn_Ack_E8FFA0 37120 "VLSI1" 40448 "DM29" 41216 "DM33" 41728 "DM31" 41984 "DM30" 47360 "PLLT(PlanListLifetime)" 47872 "PLD(PlanListDistance)" 49408 "DM21" 49664 "DM20" 49920 "DM22" 53504 "MaintBcIc" 54016 "DM19" 60928 "ACL" 61184 "STOD" 64342 "HVESP3CFG" 64344 "HVESP2CFG" 64346 "HVESP1CFG" 64529 "TGFI" 64579 "TCSI" 64582 "TSIS" 64583 "MTI" 64605 "HVESSCFG" 64606 "HVESSHIST" 64653 "PII" 64701 "A1SCRSI2" 64782 "AT1OGC2" 64784 "AT1IGC2" 64839 "TML" 64879 "EEC8" 64896 "DM28" 64905 "VDS2" 64906 "J2012" 64912 "AETC" 64920 "AT1HI1" 64949 "DM23" 64950 "DM24" 64951 "DM25" 64952 "DM26" 64953 "TPRI" 64965 "ECUID" 64981 "EEC5" 65039 "LC" 65099 "TCFG2" 65109 "GFD" 65127 "CCC" 65131 "DI" 65136 "CVW" 65144 "TP1" 65145 "TP2" 65146 "TP3" 65195 "ETC6" 65196 "EBC4" 65199 "GFC" 65201 "EH" 65202 "GFI1" 65203 "LFI1" 65208 "GTFI" 65212 "CBI" 65214 "EEC4" 65216 "SERV" 65219 "ETC5" 65221 "ETC4" 65223 "ETC3" 65227 "DM02" 65228 "DM03" 65229 "DM04" 65230 "DM05" 65231 "DM06" 65234 "DM10" 65235 "DM11" 65236 "DM12" 65242 "SOFT" 65244 "IO" 65248 "VD" 65250 "TCFG" 65253 "HOURS" 65254 "TD" 65255 "VH" 65256 "VDS" 65257 "LFC1" 65258 "VW" 65259 "CI" 65260 "VI" 65261 "CCSS" 65284 "PB_DriversConsentOnPersonalData" 65376 "VehCfg" 65413 "PB_3CT" 65482 "PB_ID1" 65484 "PB_VNS" 65502 "Av2" 65520 "SCh" 65521 "DIS" 65524 "PB_IVA" ;
VAL_ 2565406624 CtrlByte_Ackm_E8FFA0 0 "ACK" 1 "NACK" 2 "Access Denied" 3 "Cannot Respond" ;
VAL_ 2364551072 AebsSts 0 "Not ready" 1 "Temporarily not available" 2 "Deactivated by driver" 3 "Ready" 4 "Driver overrides system" 5 "Collision warning active" 6 "Collision warning with braking" 7 "Emergency braking active" 8 "Perf. / sensitivity limited" 9 "Reserved" 10 "Reserved" 11 "Reserved" 12 "Reserved" 13 "Reserved" 14 "Error indication" 15 "Not Available / Not installed" ;
VAL_ 2349572119 DrivActvDemForAebs 0 "Deactivation of system" 1 "No deactivation of system" 2 "Reserved" 3 "Don’t' care / Take no action" ;
VAL_ 2566827553 AirComprSts 0 "Compressor not active" 1 "Compressor active" 2 "Error indicator" 3 "Not Available" ;
VAL_ 2566827553 AirSuspSupplyPrs1 254 "Error" 255 "Not_available" ;
VAL_ 2566620766 Data7 64 "CAN J1939" ;
VAL_ 2566620766 Data6 18 "Rev50436_4_2020" ;
VAL_ 2566620766 Data4 1 "and DATA1 0xB0 GeneralError" 2 "and DATA1 0xB0 SelftestError" 3 "and DATA1 0xB0 AlchIntlckNoFunct" 4 "and DATA1 0xB0 CommError" 85 "Acknowledge" 133 "NotAknowledge" ;
VAL_ 2566620766 CAID2EngStartRollingSit 83 "AutorizedStart_Byte3" 172 "AutorizedStart_Byte2" ;
VAL_ 2566620766 CAID2Sts 2 "ProtocolValidatReqByNBM" 176 "Error" 240 "ShutDownReqByNBM" ;
VAL_ 2566845696 EngIn1AirTemp 254 "Error" 255 "Not_available" ;
VAL_ 2566845696 AmbAirTemp 65534 "Error" 65535 "Not_available" ;
VAL_ 2566845696 BaromPrs 254 "Error" 255 "Not_available" ;
VAL_ 2566845719 AmbAirTemp_FEF517 65534 "Error" 65535 "Not_available" ;
VAL_ 2566845719 CabInternTemp 65534 "Error" 65535 "Not_available" ;
VAL_ 2565921626 Dc_AcAccsInv2OpSts 0 "API_Off" 1 "API_On" 2 "API_Faulted On" 3 "API_Faulted Off" 4 "Error" 5 "Reserved" 6 "Error" 7 "Not Available" ;
VAL_ 2565922650 Dc_AcAccsInv3LoadshedReq 0 "Not requested" 1 "Requested" 2 "Requested, Shutdown Imminent" 3 "Don’t Care / Take no action" ;
VAL_ 2565922650 Dc_AcAccsInv3OpSts 0 "Off" 1 "On" 2 "Faulted On" 3 "Faulted Off" 4 "Reserved" 5 "Reserved" 6 "Error" 7 "Not Available" ;
VAL_ 2566837527 Altern3Sts 0 "Not charging" 1 "Charging" 2 "Error" 3 "Not Available" ;
VAL_ 2566837527 Altern2Sts 0 "Not charging" 1 "Charging" 2 "Error" 3 "Not Available" ;
VAL_ 2566837527 Altern1Sts 0 "Not charging" 1 "Charging" 2 "Error" 3 "Not Available" ;
VAL_ 2365479471 KneelInfo 0 "Not active" 1 "Lowering active" 2 "Kneeling level reached" 3 "Lifting active" 4 "Kneeling aborted" 5 "Not defined" 6 "Not defined" 13 "Not defined" 14 "Error" 15 "Not Available" ;
VAL_ 2365479488 KneelInfo_E5A40 0 "Not active" 1 "Lowering active" 2 "Kneeling level reached" 3 "Lifting active" 4 "Kneeling aborted" 5 "Not defined" 6 "Not defined" 13 "Not defined" 14 "Error" 15 "Not Available" ;
VAL_ 2566804992 AtScrOpInducSev 0 "No Inducement Active" 1 "Level 1" 2 "Level 2" 3 "Level 3" 4 "Level 4" 5 "Level 5" 6 "Temporary Override of Inducement" 7 "Not Available / Not Supported" ;
VAL_ 2566804992 At1DefTankVol 251 "No valid measurement" ;
VAL_ 2566849271 ErrSts 0 "No error" 1 "Error" 2 "Reserved" 3 "Not available" ;
VAL_ 2566849271 PulseEna 0 "Pulses not enabled" 1 "Pulses enabled" 2 "Reserved" 3 "Not available" ;
VAL_ 2566849015 ErrSts_FF01F7 0 "No error" 1 "Error" 2 "Reserved" 3 "Not available" ;
VAL_ 2566849015 PulseEna_FF01F7 0 "Pulses not enabled" 1 "Pulses enabled" 2 "Reserved" 3 "Not available" ;
VAL_ 2566848759 Term15Sts 0 "Terminal 15 off" 1 "Terminal 15 on" 2 "Reserved" 3 "Not available" ;
VAL_ 2566849270 ErrSts_FF02F6 0 "No error" 1 "Error" 2 "Reserved" 3 "Not available" ;
VAL_ 2566849270 PulseEna_FF02F6 0 "Pulses not enabled" 1 "Pulses enabled" 2 "Reserved" 3 "Not available" ;
VAL_ 2566849014 ErrSts_FF01F6 0 "No error" 1 "Error" 2 "Reserved" 3 "Not available" ;
VAL_ 2566849014 PulseEna_FF01F6 0 "Pulses not enabled" 1 "Pulses enabled" 2 "Reserved" 3 "Not available" ;
VAL_ 2566848758 Term15Sts_FF00F6 0 "Terminal 15 off" 1 "Terminal 15 on" 2 "Reserved" 3 "Not available" ;
VAL_ 2566838561 Auxi_OChan2_ElecHeaterPower 254 "Error" 255 "Not_Available" ;
VAL_ 2566838561 Auxi_OChan2_ElecHeatPower_LSB 254 "Error" 255 "Not_Available" ;
VAL_ 2566838561 AuxIo16 0 "Off" 1 "On" 2 "Error" 3 "Not Available" ;
